VERSION ""

NS_ :

BS_:

BU_: VMCU VGGSECUSystem TECU OBDScanT2 HMIIOM EMS ECUspare2 ECUspare1 DACU CIOM BBM

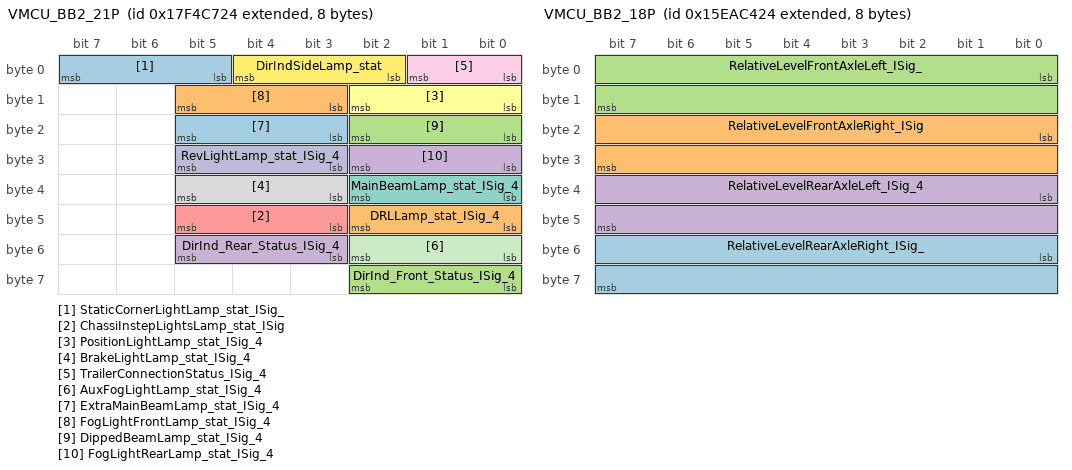
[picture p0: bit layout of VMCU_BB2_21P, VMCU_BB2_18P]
BO_ 2549401380 VMCU_BB2_21P: 8 VMCU
 SG_ StaticCornerLightLamp_stat_ISig_ : 5|3@1+ (1,0) [0|0] ""  HMIIOM
 SG_ DRLLamp_stat_ISig_4 : 40|3@1+ (1,0) [0|0] ""  HMIIOM
 SG_ DirInd_Front_Status_ISig_4 : 56|3@1+ (1,0) [0|0] ""  HMIIOM
 SG_ DirInd_Rear_Status_ISig_4 : 51|3@1+ (1,0) [0|0] ""  HMIIOM
 SG_ ChassiInstepLightsLamp_stat_ISig : 43|3@1+ (1,0) [0|0] ""  HMIIOM
 SG_ PositionLightLamp_stat_ISig_4 : 8|3@1+ (1,0) [0|0] ""  HMIIOM
 SG_ MainBeamLamp_stat_ISig_4 : 32|3@1+ (1,0) [0|0] ""  HMIIOM
 SG_ BrakeLightLamp_stat_ISig_4 : 35|3@1+ (1,0) [0|0] ""  HMIIOM
 SG_ TrailerConnectionStatus_ISig_4 : 0|2@1+ (1,0) [0|0] ""  HMIIOM
 SG_ RevLightLamp_stat_ISig_4 : 27|3@1+ (1,0) [0|0] ""  HMIIOM
 SG_ AuxFogLightLamp_stat_ISig_4 : 48|3@1+ (1,0) [0|0] ""  HMIIOM
 SG_ DirIndSideLamp_stat : 2|3@1+ (1,0) [0|0] ""  HMIIOM
 SG_ ExtraMainBeamLamp_stat_ISig_4 : 19|3@1+ (1,0) [0|0] ""  HMIIOM
 SG_ FogLightFrontLamp_stat_ISig_4 : 11|3@1+ (1,0) [0|0] ""  HMIIOM
 SG_ DippedBeamLamp_stat_ISig_4 : 16|3@1+ (1,0) [0|0] ""  HMIIOM
 SG_ FogLightRearLamp_stat_ISig_4 : 24|3@1+ (1,0) [0|0] ""  HMIIOM

BO_ 2481980708 VMCU_BB2_20P: 8 VMCU
 SG_ StartupProhibitStatus_ISig_4 : 8|2@1+ (1,0) [0|0] ""  BBM,HMIIOM
 SG_ LoadDistributionReasonChanged_IS : 59|3@1+ (1,0) [0|0] ""  HMIIOM
 SG_ RampLevelStatus_ISig_4 : 32|4@1+ (1,0) [0|0] ""  HMIIOM,CIOM
 SG_ KneelingInformation_ISig_4 : 42|4@1+ (1,0) [0|0] ""  BBM,HMIIOM,CIOM
 SG_ FrontAxleInBumperRange_ISig_4 : 40|2@1+ (1,0) [0|0] ""  TECU,HMIIOM
 SG_ FerryFunctionStatus_ISig_4 : 2|3@1+ (1,0) [0|0] ""  HMIIOM,CIOM
 SG_ EngPtoConsumesTorque : 10|2@1+ (1,0) [0|0] ""  TECU
 SG_ LiftingControlModeRearAxle_ISig_ : 36|2@1+ (1,0) [0|0] ""  BBM
 SG_ KneelingStatusHMI_ISig_4 : 53|2@1+ (1,0) [0|0] ""  CIOM
 SG_ SWEngineStop_rqst_ISig_4 : 12|3@1+ (1,0) [0|0] ""  VGGSECUSystem,BBM
 SG_ FrontEndPositionStatus_ISig_4 : 18|3@1+ (1,0) [0|0] ""  CIOM
 SG_ LiftingControlModeFrontAxle_ISig : 30|2@1+ (1,0) [0|0] ""  BBM
 SG_ FrontAxleInBumperRange_UB_ISig_4 : 46|1@1+ (1,0) [0|0] ""  TECU,HMIIOM
 SG_ UnevenLoadWarning_ISig_4 : 16|2@1+ (1,0) [0|0] ""  HMIIOM
 SG_ RampHeightOutsideTargetRange_ISi : 27|3@1+ (1,0) [0|0] ""  HMIIOM,CIOM
 SG_ DriveLevelPosUserInteraction_ISi : 48|3@1+ (1,0) [0|0] ""  HMIIOM
 SG_ RearEndPositionStatus_ISig_4 : 24|3@1+ (1,0) [0|0] ""  TECU,CIOM
 SG_ ProhibitControlStatus_ISig_4 : 6|2@1+ (1,0) [0|0] ""  HMIIOM,BBM
 SG_ ChangeKneelACK_ISig_4 : 51|2@1+ (1,0) [0|0] ""  CIOM
 SG_ RollEndPositionStatus_ISig_4 : 21|3@1+ (1,0) [0|0] ""  CIOM
 SG_ RearAxleInBumperRange_UB_ISig_4 : 47|1@1+ (1,0) [0|0] ""  TECU,HMIIOM
 SG_ TransferCaseBadCondition : 56|3@1+ (1,0) [0|0] ""  HMIIOM
 SG_ ECSStandbyAllowed_ISig_4 : 0|2@1+ (1,0) [0|0] ""  CIOM
 SG_ RearAxleInBumperRange_ISig_4 : 38|2@1+ (1,0) [0|0] ""  TECU,HMIIOM

BO_ 2515190820 VMCU_BB2_18P: 8 VMCU
 SG_ RelativeLevelRearAxleRight_ISig_ : 48|16@1+ (0.1,-3200) [-3200|3353.5] "mm"  BBM
 SG_ RelativeLevelFrontAxleRight_ISig : 16|16@1+ (0.1,-3200) [-3200|3353.5] "mm"  BBM
 SG_ RelativeLevelFrontAxleLeft_ISig_ : 0|16@1+ (0.1,-3200) [-3200|3353.5] "mm"  BBM
 SG_ RelativeLevelRearAxleLeft_ISig_4 : 32|16@1+ (0.1,-3200) [-3200|3353.5] "mm"  BBM

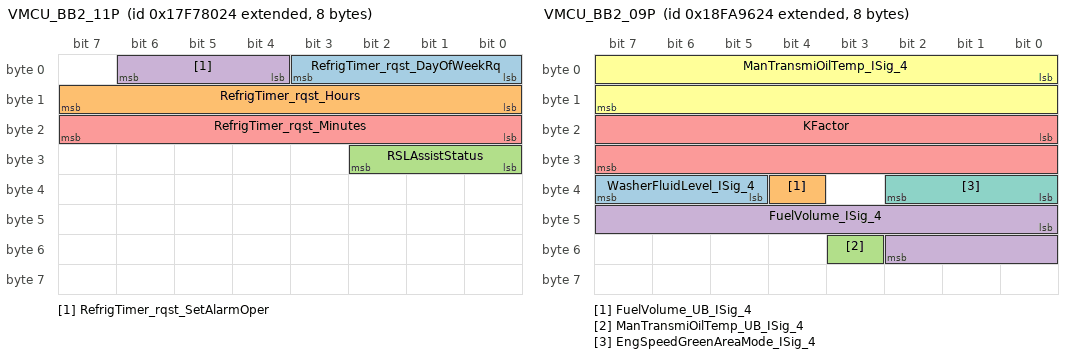
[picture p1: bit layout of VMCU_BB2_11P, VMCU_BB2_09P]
BO_ 2549579812 VMCU_BB2_11P: 8 VMCU
 SG_ RefrigTimer_rqst_DayOfWeekRq : 0|4@1+ (1,0) [0|0] ""  HMIIOM
 SG_ RefrigTimer_rqst_Hours : 8|8@1+ (1,0) [0|255] "h"  HMIIOM
 SG_ RSLAssistStatus : 24|3@1+ (1,0) [0|0] ""  TECU
 SG_ RefrigTimer_rqst_SetAlarmOper : 4|3@1+ (1,0) [0|0] ""  HMIIOM
 SG_ RefrigTimer_rqst_Minutes : 16|8@1+ (1,0) [0|255] "min"  HMIIOM

BO_ 2549430564 VMCU_BB2_10P: 8 VMCU
 SG_ HighResolutionTripDistance2_ISig : 32|32@1+ (5,0) [0|21474836475] "m"  VGGSECUSystem,HMIIOM
 SG_ HighResolutionTripDistance1_ISig : 0|32@1+ (5,0) [0|21474836475] "m"  BBM,VGGSECUSystem,HMIIOM

BO_ 2566559268 VMCU_BB2_09P: 8 VMCU
 SG_ WasherFluidLevel_ISig_4 : 37|3@1+ (1,0) [0|0] ""  HMIIOM
 SG_ FuelVolume_UB_ISig_4 : 36|1@1+ (1,0) [0|0] ""  HMIIOM
 SG_ ManTransmiOilTemp_UB_ISig_4 : 51|1@1+ (1,0) [0|0] ""  HMIIOM
 SG_ FuelVolume_ISig_4 : 40|11@1+ (1,0) [0|2047] "l"  HMIIOM
 SG_ KFactor : 16|16@1+ (1,0) [0|65535] "NotApplicable"  EMS,TECU,BBM,DACU
 SG_ ManTransmiOilTemp_ISig_4 : 0|16@1+ (0.03125,-273) [-273|1774.96875] "DegreeC"  HMIIOM
 SG_ EngSpeedGreenAreaMode_ISig_4 : 32|3@1+ (1,0) [0|0] ""  HMIIOM

BO_ 2515721252 VMCU_BB2_08P: 8 VMCU
 SG_ CabRoofSignLightFeedback_stat : 52|2@1+ (1,0) [0|0] ""  CIOM
 SG_ TemporaryRSLStatus : 54|2@1+ (1,0) [0|0] ""  CIOM
 SG_ CabExtraSideWrknLightFdbk_stat_I : 4|2@1+ (1,0) [0|0] ""  CIOM,BBM
 SG_ CabWrknLightChassisFdbk_stat_ISi : 10|2@1+ (1,0) [0|0] ""  BBM,CIOM
 SG_ HeadLightLevelRequest_stat : 40|5@1+ (1,0) [0|0] ""  HMIIOM
 SG_ CabTrailerBodyLgthnFdbk_stat : 8|2@1+ (1,0) [0|0] ""  CIOM
 SG_ DiffLockInterWhlStatusSplitBox_I : 56|2@1+ (1,0) [0|0] ""  BBM
 SG_ BodyOrCabWorkingLightFdbk_stat_I : 0|2@1+ (1,0) [0|0] ""  CIOM,BBM
 SG_ WheelBasedVehicleSpeedLowRes_ISi : 32|8@1+ (1,0) [0|255] "Km_per_h"  HMIIOM,CIOM
 SG_ AirDryerCoolingFanSpeed_rqst : 16|16@1+ (1,0) [0|65535] "rpm"  VGGSECUSystem,EMS
 SG_ CabFrontSpotFeedback_Status : 6|2@1+ (1,0) [0|0] ""  CIOM
 SG_ CabTiltEnableStatus : 2|2@1+ (1,0) [0|0] ""  CIOM
 SG_ TransmReverseDirectionSw_stat_IS : 58|2@1+ (1,0) [0|0] ""  BBM
 SG_ CabRoofSpotFeedback_Status : 12|2@1+ (1,0) [0|0] ""  HMIIOM,CIOM
 SG_ CabBeaconLightFeedback_Status_IS : 50|2@1+ (1,0) [0|0] ""  CIOM,BBM
 SG_ ExtraAxleSteeringFunctionStat_IS : 60|3@1+ (1,0) [0|0] ""  CIOM
 SG_ AirDryerCoolingFanSpeed_rqst_UB : 48|1@1+ (1,0) [0|0] ""  VGGSECUSystem,EMS
 SG_ CabTiltLockStatus_ISig_4 : 14|2@1+ (1,0) [0|0] ""  BBM,HMIIOM
 SG_ PositionLightRearLamp_stat_ISig_ : 45|3@1+ (1,0) [0|0] ""  HMIIOM

BO_ 2498842916 VMCU_BB2_07P: 8 VMCU
 SG_ Pto1BadCondition_ISig_4 : 4|4@1+ (1,0) [0|0] ""  BBM,HMIIOM
 SG_ PtosStatus_UB_ISig_4 : 40|1@1+ (1,0) [0|0] ""  EMS,CIOM,BBM,HMIIOM
 SG_ Pto4BadCondition : 12|4@1+ (1,0) [0|0] ""  HMIIOM,BBM
 SG_ Pto2BadCondition : 8|4@1+ (1,0) [0|0] ""  HMIIOM,BBM
 SG_ PtoRequest : 18|2@1+ (1,0) [0|0] ""  EMS
 SG_ Pto2ConsentRequest : 32|2@1+ (1,0) [0|0] ""  TECU
 SG_ PBStatusDisplay_cmd_ISig_4 : 42|2@1+ (1,0) [0|0] ""  HMIIOM
 SG_ Pto4DrivingRequest : 28|2@1+ (1,0) [0|0] ""  BBM
 SG_ Pto3Indication : 58|2@1+ (1,0) [0|0] ""  CIOM
 SG_ Pto2Status_ISig_4 : 22|2@1+ (1,0) [0|0] ""  HMIIOM,TECU,CIOM,BBM
 SG_ Pto4Status_ISig_4 : 34|2@1+ (1,0) [0|0] ""  CIOM,HMIIOM,BBM
 SG_ RampLevelRequestACK_ISig_4 : 44|2@1+ (1,0) [0|0] ""  CIOM
 SG_ Pto3BadCondition : 0|4@1+ (1,0) [0|0] ""  HMIIOM,BBM
 SG_ PtosStatus_ISig_4 : 36|2@1+ (1,0) [0|0] ""  BBM,CIOM,EMS,HMIIOM
 SG_ FrontWheelDriveAutoStatus_ISig_4 : 46|2@1+ (1,0) [0|0] ""  BBM,HMIIOM
 SG_ Pto1ConsentRequest : 24|2@1+ (1,0) [0|0] ""  TECU
 SG_ Pto4Indication : 60|2@1+ (1,0) [0|0] ""  CIOM
 SG_ Pto1FeedbackStatus_UB_ISig_4 : 41|1@1+ (1,0) [0|0] ""  BBM,HMIIOM
 SG_ Pto1Indication : 53|2@1+ (1,0) [0|0] ""  CIOM
 SG_ Pto3Status_ISig_4 : 16|2@1+ (1,0) [0|0] ""  BBM,HMIIOM,CIOM
 SG_ Pto2Indication : 56|2@1+ (1,0) [0|0] ""  CIOM
 SG_ Pto1FeedbackStatus_ISig_4 : 38|2@1+ (1,0) [0|0] ""  HMIIOM,BBM
 SG_ TransferCaseOrSplitboxPTOMode_IS : 26|2@1+ (1,0) [0|0] ""  TECU,BBM,HMIIOM
 SG_ FrontWheelDriveMenuFeedback : 48|2@1+ (1,0) [0|0] ""  HMIIOM
 SG_ DirIndRearLamp_Stat_ISig_4 : 50|3@1+ (1,0) [0|0] ""  HMIIOM
 SG_ Pto1Status_ISig_4 : 20|2@1+ (1,0) [0|0] ""  CIOM,TECU,BBM,HMIIOM
 SG_ Pto3DrivingRequest : 30|2@1+ (1,0) [0|0] ""  BBM

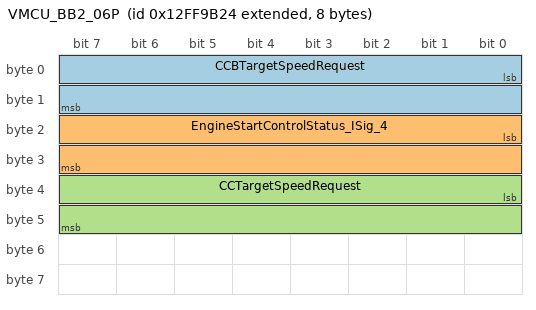
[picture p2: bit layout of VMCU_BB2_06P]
BO_ 2466224932 VMCU_BB2_06P: 8 VMCU
 SG_ CCBTargetSpeedRequest : 0|16@1+ (0.00390625,0) [0|255.99609375] "Km_per_h"  EMS,TECU
 SG_ EngineStartControlStatus_ISig_4 : 16|16@1+ (1,0) [0|0] ""  HMIIOM,BBM,VGGSECUSystem
 SG_ CCTargetSpeedRequest : 32|16@1+ (0.00390625,0) [0|255.99609375] "Km_per_h"  TECU,EMS

BO_ 2466210596 VMCU_BB2_05P: 8 VMCU
 SG_ StoreIdleValue_ISig_4 : 56|2@1+ (1,0) [0|0] ""  HMIIOM,EMS
 SG_ EngSpdCtrlBadConditions_ISig_4 : 50|5@1+ (1,0) [0|0] ""  HMIIOM,VGGSECUSystem
 SG_ TrailerConnected_UB_ISig_4 : 23|1@1+ (1,0) [0|0] ""  HMIIOM,EMS,DACU,TECU,BBM
 SG_ CrossCountryBadConditions : 24|5@1+ (1,0) [0|0] ""  HMIIOM
 SG_ ESCReqEMS_CtrlTrimMode_ISig_4 : 14|4@1+ (1,0) [0|0] ""  EMS,TECU,HMIIOM
 SG_ ESCReqESC_CtrlTrimMode_ISig_4 : 40|4@1+ (1,0) [0|0] ""  CIOM,HMIIOM,BBM,VGGSECUSystem
 SG_ IdleAdjustConditionStatus : 20|2@1+ (1,0) [0|0] ""  HMIIOM
 SG_ StopProhibitStatus_ISig_4 : 61|2@1+ (1,0) [0|0] ""  HMIIOM,BBM
 SG_ ESCReqEMS_CtrlTrimStat_ISig_4 : 11|3@1+ (1,0) [0|0] ""  HMIIOM,EMS,TECU
 SG_ TrailerConnected_ISig_4 : 18|2@1+ (1,0) [0|0] ""  TECU,HMIIOM,EMS,DACU,BBM
 SG_ ESCReqESC_CtrlTrimValue_ISig_4 : 32|8@1+ (10,0) [0|2550] ""  VGGSECUSystem,BBM,HMIIOM,CIOM
 SG_ BrakeLight_rqst_UB_ISig_4 : 22|1@1+ (1,0) [0|0] ""  BBM
 SG_ ESCReqESC_CtrlTrimStat_ISig_4 : 44|3@1+ (1,0) [0|0] ""  CIOM,BBM,HMIIOM,VGGSECUSystem
 SG_ SCLLogicEnable_rqst : 58|3@1+ (1,0) [0|0] ""  CIOM
 SG_ ESCReqESC_CtrlTrimReq_ISig_4 : 47|3@1+ (1,0) [0|0] ""  HMIIOM,CIOM,BBM,VGGSECUSystem
 SG_ BrakeLight_rqst_ISig_4 : 29|3@1+ (1,0) [0|0] ""  BBM
 SG_ ESCReqEMS_CtrlTrimValue_ISig_4 : 0|8@1+ (10,0) [0|2550] ""  HMIIOM,TECU,EMS
 SG_ ESCReqEMS_CtrlTrimReq_ISig_4 : 8|3@1+ (1,0) [0|0] ""  HMIIOM,TECU,EMS

BO_ 2466196004 VMCU_BB2_04P: 8 VMCU
 SG_ WiperParkStatus_Global_UB_ISig_4 : 39|1@1+ (1,0) [0|0] ""  DACU
 SG_ TrailerTest_stat : 3|3@1+ (1,0) [0|0] ""  VGGSECUSystem,HMIIOM
 SG_ Washing_HMI_rqst_ISig_4 : 42|2@1+ (1,0) [0|0] ""  CIOM
 SG_ AuxBrakesDwngrdModeInd_rqst_ISig : 27|3@1+ (1,0) [0|0] ""  HMIIOM,VGGSECUSystem
 SG_ XRSLTargetSpeedRequest : 48|16@1+ (0.00390625,0) [0|255.99609375] "Km_per_h"  EMS
 SG_ XPRsystemstate_ISig_4 : 8|8@1+ (1,0) [0|255] "NotApplicable"  DACU,BBM
 SG_ KeyAuthentication_rqst : 35|3@1+ (1,0) [0|0] ""  CIOM
 SG_ EngineSpeedControlStatus_ISig_4 : 32|3@1+ (1,0) [0|0] ""  CIOM,HMIIOM,BBM,VGGSECUSystem
 SG_ EngineSpeedLimitReached : 0|3@1+ (1,0) [0|0] ""  HMIIOM
 SG_ SecondThrottle : 30|2@1+ (1,0) [0|0] ""  EMS,DACU
 SG_ PredeliveryModeIndication_cmd_IS : 40|2@1+ (1,0) [0|0] ""  HMIIOM,CIOM
 SG_ LoadCutOffIndication_cmd_ISig_4 : 44|2@1+ (1,0) [0|0] ""  HMIIOM
 SG_ AutoPBRelease_stat_ISig_4 : 22|2@1+ (1,0) [0|0] ""  HMIIOM
 SG_ AutoParkBrakeActvnInhibd_stat_IS : 6|2@1+ (1,0) [0|0] ""  HMIIOM
 SG_ WiperParkStatus_Global_ISig_4 : 20|2@1+ (1,0) [0|0] ""  DACU
 SG_ ExitPreDeliveryModeHMI_rqst_ISig : 16|2@1+ (1,0) [0|0] ""  CIOM
 SG_ FdEquipmentStatus1_ISig_4 : 18|2@1+ (1,0) [0|0] ""  BBM,HMIIOM,CIOM

BO_ 2432649764 VMCU_BB2_03P: 8 VMCU
 SG_ ParkBrakeAlert_ISig_4 : 42|2@1+ (1,0) [0|0] ""  HMIIOM
 SG_ IntLightMode_CoreRqst_IL_Mode : 48|3@1+ (1,0) [0|0] ""  HMIIOM,CIOM
 SG_ WiperModeStatus_UB_ISig_4 : 55|1@1+ (1,0) [0|0] ""  CIOM,HMIIOM,DACU
 SG_ SteeringColumnLockErrInd_rqst : 27|3@1+ (1,0) [0|0] ""  HMIIOM
 SG_ MainBeamIndication_cmd : 14|2@1+ (1,0) [0|0] ""  HMIIOM
 SG_ PosLightWarning_rqst : 12|2@1+ (1,0) [0|0] ""  HMIIOM
 SG_ RainsensorActivationHMI_stat : 52|2@1+ (1,0) [0|0] ""  HMIIOM
 SG_ FogLight_Front_Indication_Cmd : 18|2@1+ (1,0) [0|0] ""  HMIIOM
 SG_ ParkingLight_Indication : 30|2@1+ (1,0) [0|0] ""  CIOM
 SG_ DaytimeRunningLight_Indication : 16|2@1+ (1,0) [0|0] ""  CIOM
 SG_ EPBBackupMode_ISig_4 : 44|4@1+ (1,0) [0|0] ""  HMIIOM
 SG_ WiperModeStatus_ISig_4 : 32|3@1+ (1,0) [0|0] ""  CIOM,DACU
 SG_ FrontFog_Indication : 22|2@1+ (1,0) [0|0] ""  CIOM
 SG_ PBReleaseAcceptance_stat_ISig_4 : 37|3@1+ (1,0) [0|0] ""  HMIIOM
 SG_ ParkingBrake_stat_UB_ISig_4 : 54|1@1+ (1,0) [0|0] ""  HMIIOM,EMS,CIOM,TECU,BBM
 SG_ DrivingLightPlus_Indication : 8|2@1+ (1,0) [0|0] ""  CIOM
 SG_ IntLightMode_CoreRqst_EventFlag : 51|1@1+ (1,0) [0|0] ""  CIOM,HMIIOM
 SG_ ParkingBrake_stat_ISig_4 : 40|2@1+ (1,0) [0|0] ""  EMS,HMIIOM,VGGSECUSystem,CIOM,BBM,TECU
 SG_ DrivingLight_Indication : 4|2@1+ (1,0) [0|0] ""  CIOM
 SG_ Rainsensor_Indication : 20|2@1+ (1,0) [0|0] ""  HMIIOM
 SG_ DippedBeamIndication_cmd : 10|2@1+ (1,0) [0|0] ""  HMIIOM
 SG_ MirrorHeatingMode_ISig_4 : 24|3@1+ (1,0) [0|0] ""  CIOM
 SG_ RearFog_Indication : 35|2@1+ (1,0) [0|0] ""  CIOM
 SG_ InteriorLightLevelInd_cmd : 56|8@1+ (1,0) [0|255] "Percent"  CIOM
 SG_ FogLight_Rear_Indication_Cmd : 2|2@1+ (1,0) [0|0] ""  HMIIOM
 SG_ PosLight_Indication_Cmd : 6|2@1+ (1,0) [0|0] ""  HMIIOM
 SG_ DirIndicationTimeoutInd_rqst : 0|2@1+ (1,0) [0|0] ""  HMIIOM

CM_ SG_ 2515190820 RelativeLevelRearAxleRight_ISig_ "65024 - 65279 Error ; 65280 - 65535 Not available";
CM_ SG_ 2515190820 RelativeLevelFrontAxleRight_ISig "65024 - 65279 Error ; 65280 - 65535 Not available";
CM_ SG_ 2515190820 RelativeLevelFrontAxleLeft_ISig_ "65024 - 65279 Error ; 65280 - 65535 Not available";
CM_ SG_ 2515190820 RelativeLevelRearAxleLeft_ISig_4 "65024 - 65279 Error ; 65280 - 65535 Not available";
CM_ SG_ 2549430564 HighResolutionTripDistance2_ISig "4261412864 - 4278190079 Error ; 4278190080 - 4294967295 Not available";
CM_ SG_ 2549430564 HighResolutionTripDistance1_ISig "4261412864 - 4278190079 Error ; 4278190080 - 4294967295 Not available";
CM_ SG_ 2566559268 KFactor "65024 - 65279 Error ; 65280 - 65535 Not available";
CM_ SG_ 2566559268 ManTransmiOilTemp_ISig_4 "65024 - 65279 Error ; 65280 - 65535 Not available";
CM_ SG_ 2515721252 WheelBasedVehicleSpeedLowRes_ISi "254 Error ; 255 Not available";
CM_ SG_ 2515721252 AirDryerCoolingFanSpeed_rqst "65024 - 65279 Error ; 65280 - 65535 Not available";
CM_ SG_ 2466224932 CCBTargetSpeedRequest "65024 - 65279 Error ; 65280 - 65535 Not available";
CM_ SG_ 2466224932 EngineStartControlStatus_ISig_4 "65534 Error ; 65535 Not available";
CM_ SG_ 2466224932 CCTargetSpeedRequest "65024 - 65279 Error ; 65280 - 65535 Not available";
CM_ SG_ 2466210596 ESCReqESC_CtrlTrimValue_ISig_4 "254 Error ; 255 Not available";
CM_ SG_ 2466210596 ESCReqEMS_CtrlTrimValue_ISig_4 "254 Error ; 255 Not available";
CM_ SG_ 2466196004 XRSLTargetSpeedRequest "65024 - 65279 Error ; 65280 - 65535 Not available";
BA_DEF_ BO_  "GenMsgStartDelayTime" INT 0 0;
BA_DEF_ BO_  "GenMsgDelayTime" INT 0 0;
BA_DEF_ BO_  "GenMsgCycleTime" INT 0 0;
BA_DEF_ BO_  "GenMsgSendType" ENUM  "Cyclic","NotUsed","NotUsed","NotUsed","NotUsed","NotUsed","NotUsed","IfActive","NoMsgSendType","NotUsed";
BA_DEF_ SG_  "GenSigStartValue" INT 0 0;
BA_DEF_ SG_  "GenSigCycleTimeActive" INT 0 0;
BA_DEF_ SG_  "GenSigCycleTime" INT 0 0;
BA_DEF_ SG_  "GenSigSendType" ENUM  "Cyclic","OnWrite","OnWriteWithRepetition","OnChange","OnChangeWithRepetition","IfActive","IfActiveWithRepetition","NoSigSendType","NotUsed","NotUsed","NotUsed","NotUsed","NotUsed";
BA_DEF_ BO_  "VFrameFormat" ENUM  "StandardCAN","ExtendedCAN","reserved","J1939PG";
BA_DEF_ SG_  "SigType" ENUM  "Default","Range","RangeSigned","ASCII","Discrete","Control","ReferencePGN","DTC","StringDelimiter","StringLength","StringLengthControl";
BA_DEF_ SG_  "SeToolVersion_SIGNAL" STRING ;
BA_DEF_ SG_  "SeToolUniqueID_SIGNAL" STRING ;
BA_DEF_ SG_  "SeToolOwnerSigGroup_SIGNAL" STRING ;
BA_DEF_ SG_  "SeToolOwnerSigGroupID_SIGNAL" STRING ;
BA_DEF_ SG_  "SeToolName_SIGNAL" STRING ;
BA_DEF_ SG_  "SeToolItemID_SIGNAL" STRING ;
BA_DEF_ SG_  "SeToolAncestorID_SIGNAL" STRING ;
BA_DEF_ SG_  "Platform_VMCU1_Sig" ENUM  "No","Yes";
BA_DEF_ BO_  "NmAsrMessage" ENUM  "No","Yes";
BA_DEF_ SG_  "NeedsUpdateBit" ENUM  "No","Yes";
BA_DEF_ SG_  "MmAnSignal" ENUM  "No","Yes";
BA_DEF_ SG_  "GenSigMaxLatency" INT 0 65535;
BA_DEF_ SG_  "GenSigILSupport" ENUM  "Yes","No";
BA_DEF_ BO_  "GenMsgRequestable" INT 0 1;
BA_DEF_ BO_  "GenMsgILSupport" ENUM  "No","Yes";
BA_DEF_ BO_  "DiagUUDTResponse" ENUM  "No","Yes";
BA_DEF_ BO_  "DiagState" ENUM  "No","Yes";
BA_DEF_ BO_  "DiagResponse" ENUM  "No","Yes";
BA_DEF_ BO_  "DiagRequest" ENUM  "No","Yes";
BA_DEF_ BO_  "DiagConnection" HEX 0 65535;
BA_DEF_ BO_  "CanTpSTmin" INT 0 255;
BA_DEF_ BO_  "CanTpFcFrameId" HEX 0 2147483647;
BA_DEF_ BO_  "CanTpBs" INT 0 255;
BA_DEF_ SG_  "SystemSignalLongSymbol" STRING ;
BA_DEF_REL_ BU_SG_REL_  "GenSigTimeoutTime" INT 0 65535;
BA_DEF_REL_ BU_SG_REL_  "GenSigFirstTimeoutTime" INT 0 65535;
BA_DEF_DEF_  "GenMsgStartDelayTime" 0;
BA_DEF_DEF_  "GenMsgDelayTime" 0;
BA_DEF_DEF_  "GenMsgCycleTime" 0;
BA_DEF_DEF_  "GenMsgSendType" "Cyclic";
BA_DEF_DEF_  "GenSigStartValue" 0;
BA_DEF_DEF_  "GenSigCycleTimeActive" 0;
BA_DEF_DEF_  "GenSigCycleTime" 0;
BA_DEF_DEF_  "GenSigSendType" "Cyclic";
BA_DEF_DEF_  "VFrameFormat" "ExtendedCAN";
BA_DEF_DEF_  "SigType" "Default";
BA_DEF_DEF_  "SeToolVersion_SIGNAL" "";
BA_DEF_DEF_  "SeToolUniqueID_SIGNAL" "";
BA_DEF_DEF_  "SeToolOwnerSigGroup_SIGNAL" "";
BA_DEF_DEF_  "SeToolOwnerSigGroupID_SIGNAL" "";
BA_DEF_DEF_  "SeToolName_SIGNAL" "";
BA_DEF_DEF_  "SeToolItemID_SIGNAL" "";
BA_DEF_DEF_  "SeToolAncestorID_SIGNAL" "";
BA_DEF_DEF_  "Platform_VMCU1_Sig" "No";
BA_DEF_DEF_  "NmAsrMessage" "No";
BA_DEF_DEF_  "NeedsUpdateBit" "No";
BA_DEF_DEF_  "MmAnSignal" "No";
BA_DEF_DEF_  "GenSigMaxLatency" 0;
BA_DEF_DEF_  "GenSigILSupport" "Yes";
BA_DEF_DEF_  "GenMsgRequestable" 1;
BA_DEF_DEF_  "GenMsgILSupport" "Yes";
BA_DEF_DEF_  "DiagUUDTResponse" "No";
BA_DEF_DEF_  "DiagState" "No";
BA_DEF_DEF_  "DiagResponse" "No";
BA_DEF_DEF_  "DiagRequest" "No";
BA_DEF_DEF_  "DiagConnection" 0;
BA_DEF_DEF_  "CanTpSTmin" 0;
BA_DEF_DEF_  "CanTpFcFrameId" 2147483647;
BA_DEF_DEF_  "CanTpBs" 255;
BA_DEF_DEF_REL_ "GenSigTimeoutTime" 0;
BA_DEF_DEF_REL_ "GenSigFirstTimeoutTime" 0;
BA_DEF_DEF_  "SystemSignalLongSymbol" "";
BA_ "GenMsgCycleTime" BO_ 2549401380 250;
BA_ "GenMsgStartDelayTime" BO_ 2549401380 90;
BA_ "GenMsgCycleTime" BO_ 2481980708 50;
BA_ "GenMsgStartDelayTime" BO_ 2481980708 20;
BA_ "GenMsgCycleTime" BO_ 2515190820 100;
BA_ "GenMsgStartDelayTime" BO_ 2515190820 15;
BA_ "GenMsgCycleTime" BO_ 2549579812 250;
BA_ "GenMsgStartDelayTime" BO_ 2549579812 50;
BA_ "GenMsgCycleTime" BO_ 2549430564 250;
BA_ "GenMsgStartDelayTime" BO_ 2549430564 190;
BA_ "GenMsgCycleTime" BO_ 2566559268 500;
BA_ "GenMsgStartDelayTime" BO_ 2566559268 125;
BA_ "GenMsgCycleTime" BO_ 2515721252 100;
BA_ "GenMsgStartDelayTime" BO_ 2515721252 60;
BA_ "GenMsgCycleTime" BO_ 2498842916 75;
BA_ "GenMsgStartDelayTime" BO_ 2498842916 25;
BA_ "GenMsgCycleTime" BO_ 2466224932 45;
BA_ "GenMsgStartDelayTime" BO_ 2466224932 5;
BA_ "GenMsgCycleTime" BO_ 2466210596 45;
BA_ "GenMsgStartDelayTime" BO_ 2466210596 10;
BA_ "GenMsgCycleTime" BO_ 2466196004 45;
BA_ "GenMsgStartDelayTime" BO_ 2466196004 25;
BA_ "GenMsgCycleTime" BO_ 2432649764 25;
BA_ "GenMsgStartDelayTime" BO_ 2432649764 5;
BA_ "GenSigCycleTime" SG_ 2549401380 StaticCornerLightLamp_stat_ISig_ 100;
BA_ "GenSigCycleTimeActive" SG_ 2549401380 StaticCornerLightLamp_stat_ISig_ 100;
BA_ "GenSigStartValue" SG_ 2549401380 StaticCornerLightLamp_stat_ISig_ 7;
BA_ "GenSigMaxLatency" SG_ 2549401380 StaticCornerLightLamp_stat_ISig_ 258;
BA_ "Platform_VMCU1_Sig" SG_ 2549401380 StaticCornerLightLamp_stat_ISig_ 1;
BA_ "SystemSignalLongSymbol" SG_ 2549401380 StaticCornerLightLamp_stat_ISig_ "StaticCornerLightLamp_stat_ISig_4";
BA_ "GenSigCycleTime" SG_ 2549401380 DRLLamp_stat_ISig_4 100;
BA_ "GenSigCycleTimeActive" SG_ 2549401380 DRLLamp_stat_ISig_4 100;
BA_ "GenSigStartValue" SG_ 2549401380 DRLLamp_stat_ISig_4 7;
BA_ "GenSigMaxLatency" SG_ 2549401380 DRLLamp_stat_ISig_4 258;
BA_ "Platform_VMCU1_Sig" SG_ 2549401380 DRLLamp_stat_ISig_4 1;
BA_ "GenSigCycleTime" SG_ 2549401380 DirInd_Front_Status_ISig_4 100;
BA_ "GenSigCycleTimeActive" SG_ 2549401380 DirInd_Front_Status_ISig_4 100;
BA_ "GenSigStartValue" SG_ 2549401380 DirInd_Front_Status_ISig_4 7;
BA_ "GenSigMaxLatency" SG_ 2549401380 DirInd_Front_Status_ISig_4 258;
BA_ "Platform_VMCU1_Sig" SG_ 2549401380 DirInd_Front_Status_ISig_4 1;
BA_ "SeToolAncestorID_SIGNAL" SG_ 2549401380 DirInd_Front_Status_ISig_4 "x0000001D041661B2";
BA_ "SeToolItemID_SIGNAL" SG_ 2549401380 DirInd_Front_Status_ISig_4 "x0000001D042DBCE4";
BA_ "SeToolName_SIGNAL" SG_ 2549401380 DirInd_Front_Status_ISig_4 "DirInd_Front_Status";
BA_ "SeToolVersion_SIGNAL" SG_ 2549401380 DirInd_Front_Status_ISig_4 "2";
BA_ "GenSigCycleTime" SG_ 2549401380 DirInd_Rear_Status_ISig_4 100;
BA_ "GenSigCycleTimeActive" SG_ 2549401380 DirInd_Rear_Status_ISig_4 100;
BA_ "GenSigStartValue" SG_ 2549401380 DirInd_Rear_Status_ISig_4 7;
BA_ "GenSigMaxLatency" SG_ 2549401380 DirInd_Rear_Status_ISig_4 258;
BA_ "Platform_VMCU1_Sig" SG_ 2549401380 DirInd_Rear_Status_ISig_4 1;
BA_ "SeToolAncestorID_SIGNAL" SG_ 2549401380 DirInd_Rear_Status_ISig_4 "x0000001D041661D0";
BA_ "SeToolItemID_SIGNAL" SG_ 2549401380 DirInd_Rear_Status_ISig_4 "x0000001D042DB8F6";
BA_ "SeToolName_SIGNAL" SG_ 2549401380 DirInd_Rear_Status_ISig_4 "DirInd_Rear_Status";
BA_ "SeToolVersion_SIGNAL" SG_ 2549401380 DirInd_Rear_Status_ISig_4 "2";
BA_ "GenSigCycleTime" SG_ 2549401380 ChassiInstepLightsLamp_stat_ISig 100;
BA_ "GenSigCycleTimeActive" SG_ 2549401380 ChassiInstepLightsLamp_stat_ISig 100;
BA_ "GenSigStartValue" SG_ 2549401380 ChassiInstepLightsLamp_stat_ISig 7;
BA_ "GenSigMaxLatency" SG_ 2549401380 ChassiInstepLightsLamp_stat_ISig 258;
BA_ "Platform_VMCU1_Sig" SG_ 2549401380 ChassiInstepLightsLamp_stat_ISig 1;
BA_ "SystemSignalLongSymbol" SG_ 2549401380 ChassiInstepLightsLamp_stat_ISig "ChassiInstepLightsLamp_stat_ISig_4";
BA_ "GenSigCycleTime" SG_ 2549401380 PositionLightLamp_stat_ISig_4 100;
BA_ "GenSigCycleTimeActive" SG_ 2549401380 PositionLightLamp_stat_ISig_4 100;
BA_ "GenSigStartValue" SG_ 2549401380 PositionLightLamp_stat_ISig_4 7;
BA_ "GenSigMaxLatency" SG_ 2549401380 PositionLightLamp_stat_ISig_4 258;
BA_ "Platform_VMCU1_Sig" SG_ 2549401380 PositionLightLamp_stat_ISig_4 1;
BA_ "GenSigCycleTime" SG_ 2549401380 MainBeamLamp_stat_ISig_4 100;
BA_ "GenSigCycleTimeActive" SG_ 2549401380 MainBeamLamp_stat_ISig_4 100;
BA_ "GenSigStartValue" SG_ 2549401380 MainBeamLamp_stat_ISig_4 7;
BA_ "GenSigMaxLatency" SG_ 2549401380 MainBeamLamp_stat_ISig_4 258;
BA_ "Platform_VMCU1_Sig" SG_ 2549401380 MainBeamLamp_stat_ISig_4 1;
BA_ "GenSigCycleTime" SG_ 2549401380 BrakeLightLamp_stat_ISig_4 100;
BA_ "GenSigCycleTimeActive" SG_ 2549401380 BrakeLightLamp_stat_ISig_4 100;
BA_ "GenSigStartValue" SG_ 2549401380 BrakeLightLamp_stat_ISig_4 7;
BA_ "GenSigMaxLatency" SG_ 2549401380 BrakeLightLamp_stat_ISig_4 258;
BA_ "Platform_VMCU1_Sig" SG_ 2549401380 BrakeLightLamp_stat_ISig_4 1;
BA_ "GenSigCycleTime" SG_ 2549401380 TrailerConnectionStatus_ISig_4 100;
BA_ "GenSigCycleTimeActive" SG_ 2549401380 TrailerConnectionStatus_ISig_4 100;
BA_ "GenSigStartValue" SG_ 2549401380 TrailerConnectionStatus_ISig_4 3;
BA_ "GenSigCycleTime" SG_ 2549401380 RevLightLamp_stat_ISig_4 100;
BA_ "GenSigCycleTimeActive" SG_ 2549401380 RevLightLamp_stat_ISig_4 100;
BA_ "GenSigStartValue" SG_ 2549401380 RevLightLamp_stat_ISig_4 7;
BA_ "GenSigMaxLatency" SG_ 2549401380 RevLightLamp_stat_ISig_4 258;
BA_ "Platform_VMCU1_Sig" SG_ 2549401380 RevLightLamp_stat_ISig_4 1;
BA_ "GenSigCycleTime" SG_ 2549401380 AuxFogLightLamp_stat_ISig_4 100;
BA_ "GenSigCycleTimeActive" SG_ 2549401380 AuxFogLightLamp_stat_ISig_4 100;
BA_ "GenSigStartValue" SG_ 2549401380 AuxFogLightLamp_stat_ISig_4 7;
BA_ "GenSigMaxLatency" SG_ 2549401380 AuxFogLightLamp_stat_ISig_4 258;
BA_ "Platform_VMCU1_Sig" SG_ 2549401380 AuxFogLightLamp_stat_ISig_4 1;
BA_ "GenSigCycleTime" SG_ 2549401380 DirIndSideLamp_stat 100;
BA_ "GenSigCycleTimeActive" SG_ 2549401380 DirIndSideLamp_stat 100;
BA_ "GenSigStartValue" SG_ 2549401380 DirIndSideLamp_stat 7;
BA_ "GenSigMaxLatency" SG_ 2549401380 DirIndSideLamp_stat 258;
BA_ "Platform_VMCU1_Sig" SG_ 2549401380 DirIndSideLamp_stat 1;
BA_ "GenSigCycleTime" SG_ 2549401380 ExtraMainBeamLamp_stat_ISig_4 100;
BA_ "GenSigCycleTimeActive" SG_ 2549401380 ExtraMainBeamLamp_stat_ISig_4 100;
BA_ "GenSigStartValue" SG_ 2549401380 ExtraMainBeamLamp_stat_ISig_4 7;
BA_ "GenSigMaxLatency" SG_ 2549401380 ExtraMainBeamLamp_stat_ISig_4 258;
BA_ "Platform_VMCU1_Sig" SG_ 2549401380 ExtraMainBeamLamp_stat_ISig_4 1;
BA_ "GenSigCycleTime" SG_ 2549401380 FogLightFrontLamp_stat_ISig_4 100;
BA_ "GenSigCycleTimeActive" SG_ 2549401380 FogLightFrontLamp_stat_ISig_4 100;
BA_ "GenSigStartValue" SG_ 2549401380 FogLightFrontLamp_stat_ISig_4 7;
BA_ "GenSigMaxLatency" SG_ 2549401380 FogLightFrontLamp_stat_ISig_4 258;
BA_ "Platform_VMCU1_Sig" SG_ 2549401380 FogLightFrontLamp_stat_ISig_4 1;
BA_ "GenSigCycleTime" SG_ 2549401380 DippedBeamLamp_stat_ISig_4 100;
BA_ "GenSigCycleTimeActive" SG_ 2549401380 DippedBeamLamp_stat_ISig_4 100;
BA_ "GenSigStartValue" SG_ 2549401380 DippedBeamLamp_stat_ISig_4 7;
BA_ "GenSigMaxLatency" SG_ 2549401380 DippedBeamLamp_stat_ISig_4 258;
BA_ "Platform_VMCU1_Sig" SG_ 2549401380 DippedBeamLamp_stat_ISig_4 1;
BA_ "GenSigCycleTime" SG_ 2549401380 FogLightRearLamp_stat_ISig_4 100;
BA_ "GenSigCycleTimeActive" SG_ 2549401380 FogLightRearLamp_stat_ISig_4 100;
BA_ "GenSigStartValue" SG_ 2549401380 FogLightRearLamp_stat_ISig_4 7;
BA_ "GenSigMaxLatency" SG_ 2549401380 FogLightRearLamp_stat_ISig_4 258;
BA_ "Platform_VMCU1_Sig" SG_ 2549401380 FogLightRearLamp_stat_ISig_4 1;
BA_ "GenSigCycleTime" SG_ 2481980708 StartupProhibitStatus_ISig_4 100;
BA_ "GenSigCycleTimeActive" SG_ 2481980708 StartupProhibitStatus_ISig_4 100;
BA_ "GenSigStartValue" SG_ 2481980708 StartupProhibitStatus_ISig_4 3;
BA_ "GenSigMaxLatency" SG_ 2481980708 StartupProhibitStatus_ISig_4 117;
BA_ "Platform_VMCU1_Sig" SG_ 2481980708 StartupProhibitStatus_ISig_4 1;
BA_ "GenSigCycleTime" SG_ 2481980708 LoadDistributionReasonChanged_IS 100;
BA_ "GenSigCycleTimeActive" SG_ 2481980708 LoadDistributionReasonChanged_IS 100;
BA_ "GenSigStartValue" SG_ 2481980708 LoadDistributionReasonChanged_IS 7;
BA_ "Platform_VMCU1_Sig" SG_ 2481980708 LoadDistributionReasonChanged_IS 1;
BA_ "SystemSignalLongSymbol" SG_ 2481980708 LoadDistributionReasonChanged_IS "LoadDistributionReasonChanged_ISig_4";
BA_ "GenSigCycleTime" SG_ 2481980708 RampLevelStatus_ISig_4 100;
BA_ "GenSigCycleTimeActive" SG_ 2481980708 RampLevelStatus_ISig_4 100;
BA_ "GenSigStartValue" SG_ 2481980708 RampLevelStatus_ISig_4 15;
BA_ "GenSigMaxLatency" SG_ 2481980708 RampLevelStatus_ISig_4 117;
BA_ "Platform_VMCU1_Sig" SG_ 2481980708 RampLevelStatus_ISig_4 1;
BA_ "GenSigCycleTime" SG_ 2481980708 KneelingInformation_ISig_4 100;
BA_ "GenSigCycleTimeActive" SG_ 2481980708 KneelingInformation_ISig_4 100;
BA_ "GenSigStartValue" SG_ 2481980708 KneelingInformation_ISig_4 15;
BA_ "Platform_VMCU1_Sig" SG_ 2481980708 KneelingInformation_ISig_4 1;
BA_ "GenSigCycleTime" SG_ 2481980708 FrontAxleInBumperRange_ISig_4 100;
BA_ "GenSigCycleTimeActive" SG_ 2481980708 FrontAxleInBumperRange_ISig_4 100;
BA_ "GenSigStartValue" SG_ 2481980708 FrontAxleInBumperRange_ISig_4 3;
BA_ "NeedsUpdateBit" SG_ 2481980708 FrontAxleInBumperRange_ISig_4 1;
BA_ "Platform_VMCU1_Sig" SG_ 2481980708 FrontAxleInBumperRange_ISig_4 1;
BA_ "SeToolAncestorID_SIGNAL" SG_ 2481980708 FrontAxleInBumperRange_ISig_4 "x0000001D04149915";
BA_ "SeToolItemID_SIGNAL" SG_ 2481980708 FrontAxleInBumperRange_ISig_4 "x0000001D04149915";
BA_ "SeToolName_SIGNAL" SG_ 2481980708 FrontAxleInBumperRange_ISig_4 "FrontAxleInBumperRange";
BA_ "SeToolVersion_SIGNAL" SG_ 2481980708 FrontAxleInBumperRange_ISig_4 "1";
BA_ "GenSigCycleTime" SG_ 2481980708 FerryFunctionStatus_ISig_4 100;
BA_ "GenSigCycleTimeActive" SG_ 2481980708 FerryFunctionStatus_ISig_4 100;
BA_ "GenSigStartValue" SG_ 2481980708 FerryFunctionStatus_ISig_4 7;
BA_ "GenSigMaxLatency" SG_ 2481980708 FerryFunctionStatus_ISig_4 117;
BA_ "Platform_VMCU1_Sig" SG_ 2481980708 FerryFunctionStatus_ISig_4 1;
BA_ "GenSigCycleTime" SG_ 2481980708 EngPtoConsumesTorque 100;
BA_ "GenSigCycleTimeActive" SG_ 2481980708 EngPtoConsumesTorque 100;
BA_ "GenSigStartValue" SG_ 2481980708 EngPtoConsumesTorque 3;
BA_ "Platform_VMCU1_Sig" SG_ 2481980708 EngPtoConsumesTorque 1;
BA_ "GenSigCycleTime" SG_ 2481980708 LiftingControlModeRearAxle_ISig_ 100;
BA_ "GenSigCycleTimeActive" SG_ 2481980708 LiftingControlModeRearAxle_ISig_ 100;
BA_ "GenSigStartValue" SG_ 2481980708 LiftingControlModeRearAxle_ISig_ 3;
BA_ "Platform_VMCU1_Sig" SG_ 2481980708 LiftingControlModeRearAxle_ISig_ 1;
BA_ "SeToolAncestorID_SIGNAL" SG_ 2481980708 LiftingControlModeRearAxle_ISig_ "x0000001D04149A4E";
BA_ "SeToolItemID_SIGNAL" SG_ 2481980708 LiftingControlModeRearAxle_ISig_ "x0000001D04149A4E";
BA_ "SeToolName_SIGNAL" SG_ 2481980708 LiftingControlModeRearAxle_ISig_ "LiftingControlModeRearAxle";
BA_ "SeToolVersion_SIGNAL" SG_ 2481980708 LiftingControlModeRearAxle_ISig_ "1";
BA_ "SystemSignalLongSymbol" SG_ 2481980708 LiftingControlModeRearAxle_ISig_ "LiftingControlModeRearAxle_ISig_4";
BA_ "GenSigCycleTime" SG_ 2481980708 KneelingStatusHMI_ISig_4 100;
BA_ "GenSigCycleTimeActive" SG_ 2481980708 KneelingStatusHMI_ISig_4 100;
BA_ "GenSigStartValue" SG_ 2481980708 KneelingStatusHMI_ISig_4 3;
BA_ "Platform_VMCU1_Sig" SG_ 2481980708 KneelingStatusHMI_ISig_4 1;
BA_ "GenSigCycleTime" SG_ 2481980708 SWEngineStop_rqst_ISig_4 100;
BA_ "GenSigCycleTimeActive" SG_ 2481980708 SWEngineStop_rqst_ISig_4 100;
BA_ "GenSigStartValue" SG_ 2481980708 SWEngineStop_rqst_ISig_4 7;
BA_ "Platform_VMCU1_Sig" SG_ 2481980708 SWEngineStop_rqst_ISig_4 1;
BA_ "GenSigCycleTime" SG_ 2481980708 FrontEndPositionStatus_ISig_4 100;
BA_ "GenSigCycleTimeActive" SG_ 2481980708 FrontEndPositionStatus_ISig_4 100;
BA_ "GenSigStartValue" SG_ 2481980708 FrontEndPositionStatus_ISig_4 7;
BA_ "GenSigMaxLatency" SG_ 2481980708 FrontEndPositionStatus_ISig_4 117;
BA_ "Platform_VMCU1_Sig" SG_ 2481980708 FrontEndPositionStatus_ISig_4 1;
BA_ "GenSigCycleTime" SG_ 2481980708 LiftingControlModeFrontAxle_ISig 100;
BA_ "GenSigCycleTimeActive" SG_ 2481980708 LiftingControlModeFrontAxle_ISig 100;
BA_ "GenSigStartValue" SG_ 2481980708 LiftingControlModeFrontAxle_ISig 3;
BA_ "Platform_VMCU1_Sig" SG_ 2481980708 LiftingControlModeFrontAxle_ISig 1;
BA_ "SeToolAncestorID_SIGNAL" SG_ 2481980708 LiftingControlModeFrontAxle_ISig "x0000001D04149903";
BA_ "SeToolItemID_SIGNAL" SG_ 2481980708 LiftingControlModeFrontAxle_ISig "x0000001D04149903";
BA_ "SeToolName_SIGNAL" SG_ 2481980708 LiftingControlModeFrontAxle_ISig "LiftingControlModeFrontAxle";
BA_ "SeToolVersion_SIGNAL" SG_ 2481980708 LiftingControlModeFrontAxle_ISig "1";
BA_ "SystemSignalLongSymbol" SG_ 2481980708 LiftingControlModeFrontAxle_ISig "LiftingControlModeFrontAxle_ISig_4";
BA_ "GenSigSendType" SG_ 2481980708 FrontAxleInBumperRange_UB_ISig_4 7;
BA_ "Platform_VMCU1_Sig" SG_ 2481980708 FrontAxleInBumperRange_UB_ISig_4 1;
BA_ "GenSigCycleTime" SG_ 2481980708 UnevenLoadWarning_ISig_4 100;
BA_ "GenSigCycleTimeActive" SG_ 2481980708 UnevenLoadWarning_ISig_4 100;
BA_ "GenSigStartValue" SG_ 2481980708 UnevenLoadWarning_ISig_4 3;
BA_ "GenSigMaxLatency" SG_ 2481980708 UnevenLoadWarning_ISig_4 117;
BA_ "Platform_VMCU1_Sig" SG_ 2481980708 UnevenLoadWarning_ISig_4 1;
BA_ "GenSigCycleTime" SG_ 2481980708 RampHeightOutsideTargetRange_ISi 100;
BA_ "GenSigCycleTimeActive" SG_ 2481980708 RampHeightOutsideTargetRange_ISi 100;
BA_ "GenSigStartValue" SG_ 2481980708 RampHeightOutsideTargetRange_ISi 7;
BA_ "GenSigMaxLatency" SG_ 2481980708 RampHeightOutsideTargetRange_ISi 117;
BA_ "Platform_VMCU1_Sig" SG_ 2481980708 RampHeightOutsideTargetRange_ISi 1;
BA_ "SystemSignalLongSymbol" SG_ 2481980708 RampHeightOutsideTargetRange_ISi "RampHeightOutsideTargetRange_ISig_4";
BA_ "GenSigCycleTime" SG_ 2481980708 DriveLevelPosUserInteraction_ISi 100;
BA_ "GenSigCycleTimeActive" SG_ 2481980708 DriveLevelPosUserInteraction_ISi 100;
BA_ "GenSigStartValue" SG_ 2481980708 DriveLevelPosUserInteraction_ISi 7;
BA_ "Platform_VMCU1_Sig" SG_ 2481980708 DriveLevelPosUserInteraction_ISi 1;
BA_ "SystemSignalLongSymbol" SG_ 2481980708 DriveLevelPosUserInteraction_ISi "DriveLevelPosUserInteraction_ISig_4";
BA_ "GenSigCycleTime" SG_ 2481980708 RearEndPositionStatus_ISig_4 100;
BA_ "GenSigCycleTimeActive" SG_ 2481980708 RearEndPositionStatus_ISig_4 100;
BA_ "GenSigStartValue" SG_ 2481980708 RearEndPositionStatus_ISig_4 7;
BA_ "GenSigMaxLatency" SG_ 2481980708 RearEndPositionStatus_ISig_4 117;
BA_ "Platform_VMCU1_Sig" SG_ 2481980708 RearEndPositionStatus_ISig_4 1;
BA_ "GenSigCycleTime" SG_ 2481980708 ProhibitControlStatus_ISig_4 100;
BA_ "GenSigCycleTimeActive" SG_ 2481980708 ProhibitControlStatus_ISig_4 100;
BA_ "GenSigStartValue" SG_ 2481980708 ProhibitControlStatus_ISig_4 3;
BA_ "GenSigMaxLatency" SG_ 2481980708 ProhibitControlStatus_ISig_4 117;
BA_ "Platform_VMCU1_Sig" SG_ 2481980708 ProhibitControlStatus_ISig_4 1;
BA_ "GenSigCycleTime" SG_ 2481980708 ChangeKneelACK_ISig_4 100;
BA_ "GenSigCycleTimeActive" SG_ 2481980708 ChangeKneelACK_ISig_4 100;
BA_ "GenSigStartValue" SG_ 2481980708 ChangeKneelACK_ISig_4 3;
BA_ "Platform_VMCU1_Sig" SG_ 2481980708 ChangeKneelACK_ISig_4 1;
BA_ "GenSigCycleTime" SG_ 2481980708 RollEndPositionStatus_ISig_4 100;
BA_ "GenSigCycleTimeActive" SG_ 2481980708 RollEndPositionStatus_ISig_4 100;
BA_ "GenSigStartValue" SG_ 2481980708 RollEndPositionStatus_ISig_4 7;
BA_ "GenSigMaxLatency" SG_ 2481980708 RollEndPositionStatus_ISig_4 117;
BA_ "Platform_VMCU1_Sig" SG_ 2481980708 RollEndPositionStatus_ISig_4 1;
BA_ "GenSigSendType" SG_ 2481980708 RearAxleInBumperRange_UB_ISig_4 7;
BA_ "Platform_VMCU1_Sig" SG_ 2481980708 RearAxleInBumperRange_UB_ISig_4 1;
BA_ "GenSigCycleTime" SG_ 2481980708 TransferCaseBadCondition 100;
BA_ "GenSigCycleTimeActive" SG_ 2481980708 TransferCaseBadCondition 100;
BA_ "GenSigStartValue" SG_ 2481980708 TransferCaseBadCondition 7;
BA_ "Platform_VMCU1_Sig" SG_ 2481980708 TransferCaseBadCondition 1;
BA_ "GenSigCycleTime" SG_ 2481980708 ECSStandbyAllowed_ISig_4 100;
BA_ "GenSigCycleTimeActive" SG_ 2481980708 ECSStandbyAllowed_ISig_4 100;
BA_ "GenSigStartValue" SG_ 2481980708 ECSStandbyAllowed_ISig_4 3;
BA_ "Platform_VMCU1_Sig" SG_ 2481980708 ECSStandbyAllowed_ISig_4 1;
BA_ "GenSigCycleTime" SG_ 2481980708 RearAxleInBumperRange_ISig_4 100;
BA_ "GenSigCycleTimeActive" SG_ 2481980708 RearAxleInBumperRange_ISig_4 100;
BA_ "GenSigStartValue" SG_ 2481980708 RearAxleInBumperRange_ISig_4 3;
BA_ "NeedsUpdateBit" SG_ 2481980708 RearAxleInBumperRange_ISig_4 1;
BA_ "Platform_VMCU1_Sig" SG_ 2481980708 RearAxleInBumperRange_ISig_4 1;
BA_ "SeToolAncestorID_SIGNAL" SG_ 2481980708 RearAxleInBumperRange_ISig_4 "x0000001D04149986";
BA_ "SeToolItemID_SIGNAL" SG_ 2481980708 RearAxleInBumperRange_ISig_4 "x0000001D04149986";
BA_ "SeToolName_SIGNAL" SG_ 2481980708 RearAxleInBumperRange_ISig_4 "RearAxleInBumperRange";
BA_ "SeToolVersion_SIGNAL" SG_ 2481980708 RearAxleInBumperRange_ISig_4 "1";
BA_ "GenSigCycleTime" SG_ 2515190820 RelativeLevelRearAxleRight_ISig_ 100;
BA_ "GenSigCycleTimeActive" SG_ 2515190820 RelativeLevelRearAxleRight_ISig_ 100;
BA_ "GenSigStartValue" SG_ 2515190820 RelativeLevelRearAxleRight_ISig_ 65535;
BA_ "Platform_VMCU1_Sig" SG_ 2515190820 RelativeLevelRearAxleRight_ISig_ 1;
BA_ "SeToolAncestorID_SIGNAL" SG_ 2515190820 RelativeLevelRearAxleRight_ISig_ "x0000001D0412EE40";
BA_ "SeToolItemID_SIGNAL" SG_ 2515190820 RelativeLevelRearAxleRight_ISig_ "x0000001D04384E50";
BA_ "SeToolName_SIGNAL" SG_ 2515190820 RelativeLevelRearAxleRight_ISig_ "RelativeLevelRearAxleRight";
BA_ "SeToolVersion_SIGNAL" SG_ 2515190820 RelativeLevelRearAxleRight_ISig_ "2";
BA_ "SystemSignalLongSymbol" SG_ 2515190820 RelativeLevelRearAxleRight_ISig_ "RelativeLevelRearAxleRight_ISig_4";
BA_ "GenSigCycleTime" SG_ 2515190820 RelativeLevelFrontAxleRight_ISig 100;
BA_ "GenSigCycleTimeActive" SG_ 2515190820 RelativeLevelFrontAxleRight_ISig 100;
BA_ "GenSigStartValue" SG_ 2515190820 RelativeLevelFrontAxleRight_ISig 65535;
BA_ "Platform_VMCU1_Sig" SG_ 2515190820 RelativeLevelFrontAxleRight_ISig 1;
BA_ "SeToolAncestorID_SIGNAL" SG_ 2515190820 RelativeLevelFrontAxleRight_ISig "x0000001D0412EE3C";
BA_ "SeToolItemID_SIGNAL" SG_ 2515190820 RelativeLevelFrontAxleRight_ISig "x0000001D04384E33";
BA_ "SeToolName_SIGNAL" SG_ 2515190820 RelativeLevelFrontAxleRight_ISig "RelativeLevelFrontAxleRight";
BA_ "SeToolVersion_SIGNAL" SG_ 2515190820 RelativeLevelFrontAxleRight_ISig "2";
BA_ "SystemSignalLongSymbol" SG_ 2515190820 RelativeLevelFrontAxleRight_ISig "RelativeLevelFrontAxleRight_ISig_4";
BA_ "GenSigCycleTime" SG_ 2515190820 RelativeLevelFrontAxleLeft_ISig_ 100;
BA_ "GenSigCycleTimeActive" SG_ 2515190820 RelativeLevelFrontAxleLeft_ISig_ 100;
BA_ "GenSigStartValue" SG_ 2515190820 RelativeLevelFrontAxleLeft_ISig_ 65535;
BA_ "Platform_VMCU1_Sig" SG_ 2515190820 RelativeLevelFrontAxleLeft_ISig_ 1;
BA_ "SeToolAncestorID_SIGNAL" SG_ 2515190820 RelativeLevelFrontAxleLeft_ISig_ "x0000001D0412EE39";
BA_ "SeToolItemID_SIGNAL" SG_ 2515190820 RelativeLevelFrontAxleLeft_ISig_ "x0000001D04384DFD";
BA_ "SeToolName_SIGNAL" SG_ 2515190820 RelativeLevelFrontAxleLeft_ISig_ "RelativeLevelFrontAxleLeft";
BA_ "SeToolVersion_SIGNAL" SG_ 2515190820 RelativeLevelFrontAxleLeft_ISig_ "2";
BA_ "SystemSignalLongSymbol" SG_ 2515190820 RelativeLevelFrontAxleLeft_ISig_ "RelativeLevelFrontAxleLeft_ISig_4";
BA_ "GenSigCycleTime" SG_ 2515190820 RelativeLevelRearAxleLeft_ISig_4 100;
BA_ "GenSigCycleTimeActive" SG_ 2515190820 RelativeLevelRearAxleLeft_ISig_4 100;
BA_ "GenSigStartValue" SG_ 2515190820 RelativeLevelRearAxleLeft_ISig_4 65535;
BA_ "Platform_VMCU1_Sig" SG_ 2515190820 RelativeLevelRearAxleLeft_ISig_4 1;
BA_ "SeToolAncestorID_SIGNAL" SG_ 2515190820 RelativeLevelRearAxleLeft_ISig_4 "x0000001D0412EE3E";
BA_ "SeToolItemID_SIGNAL" SG_ 2515190820 RelativeLevelRearAxleLeft_ISig_4 "x0000001D04384E3D";
BA_ "SeToolName_SIGNAL" SG_ 2515190820 RelativeLevelRearAxleLeft_ISig_4 "RelativeLevelRearAxleLeft";
BA_ "SeToolVersion_SIGNAL" SG_ 2515190820 RelativeLevelRearAxleLeft_ISig_4 "2";
BA_ "GenSigCycleTime" SG_ 2549579812 RefrigTimer_rqst_DayOfWeekRq 100;
BA_ "GenSigCycleTimeActive" SG_ 2549579812 RefrigTimer_rqst_DayOfWeekRq 100;
BA_ "GenSigStartValue" SG_ 2549579812 RefrigTimer_rqst_DayOfWeekRq 15;
BA_ "Platform_VMCU1_Sig" SG_ 2549579812 RefrigTimer_rqst_DayOfWeekRq 1;
BA_ "GenSigCycleTime" SG_ 2549579812 RefrigTimer_rqst_Hours 100;
BA_ "GenSigCycleTimeActive" SG_ 2549579812 RefrigTimer_rqst_Hours 100;
BA_ "GenSigStartValue" SG_ 2549579812 RefrigTimer_rqst_Hours 255;
BA_ "Platform_VMCU1_Sig" SG_ 2549579812 RefrigTimer_rqst_Hours 1;
BA_ "GenSigCycleTime" SG_ 2549579812 RSLAssistStatus 100;
BA_ "GenSigCycleTimeActive" SG_ 2549579812 RSLAssistStatus 100;
BA_ "GenSigStartValue" SG_ 2549579812 RSLAssistStatus 7;
BA_ "GenSigCycleTime" SG_ 2549579812 RefrigTimer_rqst_SetAlarmOper 100;
BA_ "GenSigCycleTimeActive" SG_ 2549579812 RefrigTimer_rqst_SetAlarmOper 100;
BA_ "GenSigStartValue" SG_ 2549579812 RefrigTimer_rqst_SetAlarmOper 7;
BA_ "Platform_VMCU1_Sig" SG_ 2549579812 RefrigTimer_rqst_SetAlarmOper 1;
BA_ "GenSigCycleTime" SG_ 2549579812 RefrigTimer_rqst_Minutes 100;
BA_ "GenSigCycleTimeActive" SG_ 2549579812 RefrigTimer_rqst_Minutes 100;
BA_ "GenSigStartValue" SG_ 2549579812 RefrigTimer_rqst_Minutes 255;
BA_ "Platform_VMCU1_Sig" SG_ 2549579812 RefrigTimer_rqst_Minutes 1;
BA_ "GenSigCycleTime" SG_ 2549430564 HighResolutionTripDistance2_ISig 100;
BA_ "GenSigCycleTimeActive" SG_ 2549430564 HighResolutionTripDistance2_ISig 100;
BA_ "GenSigStartValue" SG_ 2549430564 HighResolutionTripDistance2_ISig 4294967295;
BA_ "GenSigMaxLatency" SG_ 2549430564 HighResolutionTripDistance2_ISig 251;
BA_ "Platform_VMCU1_Sig" SG_ 2549430564 HighResolutionTripDistance2_ISig 1;
BA_ "SeToolAncestorID_SIGNAL" SG_ 2549430564 HighResolutionTripDistance2_ISig "x0000001D0417BFE5";
BA_ "SeToolItemID_SIGNAL" SG_ 2549430564 HighResolutionTripDistance2_ISig "x0000001D0417BFE5";
BA_ "SeToolName_SIGNAL" SG_ 2549430564 HighResolutionTripDistance2_ISig "HighResolutionTripDistance2";
BA_ "SeToolVersion_SIGNAL" SG_ 2549430564 HighResolutionTripDistance2_ISig "1";
BA_ "SystemSignalLongSymbol" SG_ 2549430564 HighResolutionTripDistance2_ISig "HighResolutionTripDistance2_ISig_4";
BA_ "GenSigCycleTime" SG_ 2549430564 HighResolutionTripDistance1_ISig 100;
BA_ "GenSigCycleTimeActive" SG_ 2549430564 HighResolutionTripDistance1_ISig 100;
BA_ "GenSigStartValue" SG_ 2549430564 HighResolutionTripDistance1_ISig 4294967295;
BA_ "GenSigMaxLatency" SG_ 2549430564 HighResolutionTripDistance1_ISig 251;
BA_ "Platform_VMCU1_Sig" SG_ 2549430564 HighResolutionTripDistance1_ISig 1;
BA_ "SeToolAncestorID_SIGNAL" SG_ 2549430564 HighResolutionTripDistance1_ISig "x0000001D0417BFE5";
BA_ "SeToolItemID_SIGNAL" SG_ 2549430564 HighResolutionTripDistance1_ISig "x0000001D0417BFE5";
BA_ "SeToolName_SIGNAL" SG_ 2549430564 HighResolutionTripDistance1_ISig "HighResolutionTripDistance1";
BA_ "SeToolVersion_SIGNAL" SG_ 2549430564 HighResolutionTripDistance1_ISig "1";
BA_ "SystemSignalLongSymbol" SG_ 2549430564 HighResolutionTripDistance1_ISig "HighResolutionTripDistance1_ISig_4";
BA_ "GenSigCycleTime" SG_ 2566559268 WasherFluidLevel_ISig_4 100;
BA_ "GenSigCycleTimeActive" SG_ 2566559268 WasherFluidLevel_ISig_4 100;
BA_ "GenSigStartValue" SG_ 2566559268 WasherFluidLevel_ISig_4 7;
BA_ "GenSigMaxLatency" SG_ 2566559268 WasherFluidLevel_ISig_4 1110;
BA_ "Platform_VMCU1_Sig" SG_ 2566559268 WasherFluidLevel_ISig_4 1;
BA_ "SeToolAncestorID_SIGNAL" SG_ 2566559268 WasherFluidLevel_ISig_4 "x0000001D04104D03";
BA_ "SeToolItemID_SIGNAL" SG_ 2566559268 WasherFluidLevel_ISig_4 "x0000001D0435D527";
BA_ "SeToolName_SIGNAL" SG_ 2566559268 WasherFluidLevel_ISig_4 "WasherFluidLevel";
BA_ "SeToolVersion_SIGNAL" SG_ 2566559268 WasherFluidLevel_ISig_4 "3";
BA_ "GenSigSendType" SG_ 2566559268 FuelVolume_UB_ISig_4 7;
BA_ "Platform_VMCU1_Sig" SG_ 2566559268 FuelVolume_UB_ISig_4 1;
BA_ "GenSigSendType" SG_ 2566559268 ManTransmiOilTemp_UB_ISig_4 7;
BA_ "Platform_VMCU1_Sig" SG_ 2566559268 ManTransmiOilTemp_UB_ISig_4 1;
BA_ "GenSigCycleTime" SG_ 2566559268 FuelVolume_ISig_4 100;
BA_ "GenSigCycleTimeActive" SG_ 2566559268 FuelVolume_ISig_4 100;
BA_ "GenSigStartValue" SG_ 2566559268 FuelVolume_ISig_4 2047;
BA_ "NeedsUpdateBit" SG_ 2566559268 FuelVolume_ISig_4 1;
BA_ "Platform_VMCU1_Sig" SG_ 2566559268 FuelVolume_ISig_4 1;
BA_ "GenSigCycleTime" SG_ 2566559268 KFactor 100;
BA_ "GenSigCycleTimeActive" SG_ 2566559268 KFactor 100;
BA_ "GenSigStartValue" SG_ 2566559268 KFactor 65535;
BA_ "GenSigMaxLatency" SG_ 2566559268 KFactor 511;
BA_ "Platform_VMCU1_Sig" SG_ 2566559268 KFactor 1;
BA_ "SeToolAncestorID_SIGNAL" SG_ 2566559268 KFactor "x0000001D0416ED52";
BA_ "SeToolItemID_SIGNAL" SG_ 2566559268 KFactor "x0000001D041B55DB";
BA_ "SeToolName_SIGNAL" SG_ 2566559268 KFactor "K-Factor";
BA_ "SeToolVersion_SIGNAL" SG_ 2566559268 KFactor "2";
BA_ "GenSigCycleTime" SG_ 2566559268 ManTransmiOilTemp_ISig_4 100;
BA_ "GenSigCycleTimeActive" SG_ 2566559268 ManTransmiOilTemp_ISig_4 100;
BA_ "GenSigStartValue" SG_ 2566559268 ManTransmiOilTemp_ISig_4 65535;
BA_ "NeedsUpdateBit" SG_ 2566559268 ManTransmiOilTemp_ISig_4 1;
BA_ "Platform_VMCU1_Sig" SG_ 2566559268 ManTransmiOilTemp_ISig_4 1;
BA_ "GenSigCycleTime" SG_ 2566559268 EngSpeedGreenAreaMode_ISig_4 100;
BA_ "GenSigCycleTimeActive" SG_ 2566559268 EngSpeedGreenAreaMode_ISig_4 100;
BA_ "GenSigStartValue" SG_ 2566559268 EngSpeedGreenAreaMode_ISig_4 7;
BA_ "Platform_VMCU1_Sig" SG_ 2566559268 EngSpeedGreenAreaMode_ISig_4 1;
BA_ "GenSigCycleTime" SG_ 2515721252 CabRoofSignLightFeedback_stat 100;
BA_ "GenSigCycleTimeActive" SG_ 2515721252 CabRoofSignLightFeedback_stat 100;
BA_ "GenSigStartValue" SG_ 2515721252 CabRoofSignLightFeedback_stat 3;
BA_ "Platform_VMCU1_Sig" SG_ 2515721252 CabRoofSignLightFeedback_stat 1;
BA_ "SeToolAncestorID_SIGNAL" SG_ 2515721252 CabRoofSignLightFeedback_stat "x0000001D041B0A30";
BA_ "SeToolItemID_SIGNAL" SG_ 2515721252 CabRoofSignLightFeedback_stat "x0000001D041B0A30";
BA_ "SeToolName_SIGNAL" SG_ 2515721252 CabRoofSignLightFeedback_stat "CabRoofSignLightFeedback_Status";
BA_ "SeToolVersion_SIGNAL" SG_ 2515721252 CabRoofSignLightFeedback_stat "1";
BA_ "GenSigCycleTime" SG_ 2515721252 TemporaryRSLStatus 100;
BA_ "GenSigCycleTimeActive" SG_ 2515721252 TemporaryRSLStatus 100;
BA_ "GenSigStartValue" SG_ 2515721252 TemporaryRSLStatus 3;
BA_ "Platform_VMCU1_Sig" SG_ 2515721252 TemporaryRSLStatus 1;
BA_ "GenSigCycleTime" SG_ 2515721252 CabExtraSideWrknLightFdbk_stat_I 100;
BA_ "GenSigCycleTimeActive" SG_ 2515721252 CabExtraSideWrknLightFdbk_stat_I 100;
BA_ "GenSigStartValue" SG_ 2515721252 CabExtraSideWrknLightFdbk_stat_I 3;
BA_ "GenSigMaxLatency" SG_ 2515721252 CabExtraSideWrknLightFdbk_stat_I 112;
BA_ "Platform_VMCU1_Sig" SG_ 2515721252 CabExtraSideWrknLightFdbk_stat_I 1;
BA_ "SeToolAncestorID_SIGNAL" SG_ 2515721252 CabExtraSideWrknLightFdbk_stat_I "x0000001D041B0A4B";
BA_ "SeToolItemID_SIGNAL" SG_ 2515721252 CabExtraSideWrknLightFdbk_stat_I "x0000001D041B0A4B";
BA_ "SeToolName_SIGNAL" SG_ 2515721252 CabExtraSideWrknLightFdbk_stat_I "CabExtraSideWorkingFeedback_Status";
BA_ "SeToolVersion_SIGNAL" SG_ 2515721252 CabExtraSideWrknLightFdbk_stat_I "1";
BA_ "SystemSignalLongSymbol" SG_ 2515721252 CabExtraSideWrknLightFdbk_stat_I "CabExtraSideWrknLightFdbk_stat_ISig_4";
BA_ "GenSigCycleTime" SG_ 2515721252 CabWrknLightChassisFdbk_stat_ISi 100;
BA_ "GenSigCycleTimeActive" SG_ 2515721252 CabWrknLightChassisFdbk_stat_ISi 100;
BA_ "GenSigStartValue" SG_ 2515721252 CabWrknLightChassisFdbk_stat_ISi 3;
BA_ "GenSigMaxLatency" SG_ 2515721252 CabWrknLightChassisFdbk_stat_ISi 112;
BA_ "Platform_VMCU1_Sig" SG_ 2515721252 CabWrknLightChassisFdbk_stat_ISi 1;
BA_ "SeToolAncestorID_SIGNAL" SG_ 2515721252 CabWrknLightChassisFdbk_stat_ISi "x0000001D041B0A49";
BA_ "SeToolItemID_SIGNAL" SG_ 2515721252 CabWrknLightChassisFdbk_stat_ISi "x0000001D041B0A49";
BA_ "SeToolName_SIGNAL" SG_ 2515721252 CabWrknLightChassisFdbk_stat_ISi "CabWorkingLightChassisFeedback_Status";
BA_ "SeToolVersion_SIGNAL" SG_ 2515721252 CabWrknLightChassisFdbk_stat_ISi "1";
BA_ "SystemSignalLongSymbol" SG_ 2515721252 CabWrknLightChassisFdbk_stat_ISi "CabWrknLightChassisFdbk_stat_ISig_4";
BA_ "GenSigCycleTime" SG_ 2515721252 HeadLightLevelRequest_stat 100;
BA_ "GenSigCycleTimeActive" SG_ 2515721252 HeadLightLevelRequest_stat 100;
BA_ "GenSigStartValue" SG_ 2515721252 HeadLightLevelRequest_stat 31;
BA_ "Platform_VMCU1_Sig" SG_ 2515721252 HeadLightLevelRequest_stat 1;
BA_ "GenSigCycleTime" SG_ 2515721252 CabTrailerBodyLgthnFdbk_stat 100;
BA_ "GenSigCycleTimeActive" SG_ 2515721252 CabTrailerBodyLgthnFdbk_stat 100;
BA_ "GenSigStartValue" SG_ 2515721252 CabTrailerBodyLgthnFdbk_stat 3;
BA_ "GenSigMaxLatency" SG_ 2515721252 CabTrailerBodyLgthnFdbk_stat 112;
BA_ "Platform_VMCU1_Sig" SG_ 2515721252 CabTrailerBodyLgthnFdbk_stat 1;
BA_ "SeToolAncestorID_SIGNAL" SG_ 2515721252 CabTrailerBodyLgthnFdbk_stat "x0000001D04206B2D";
BA_ "SeToolItemID_SIGNAL" SG_ 2515721252 CabTrailerBodyLgthnFdbk_stat "x0000001D04206B2D";
BA_ "SeToolName_SIGNAL" SG_ 2515721252 CabTrailerBodyLgthnFdbk_stat "CabTrailerBodyLightingFeedback_Status";
BA_ "SeToolVersion_SIGNAL" SG_ 2515721252 CabTrailerBodyLgthnFdbk_stat "1";
BA_ "GenSigCycleTime" SG_ 2515721252 DiffLockInterWhlStatusSplitBox_I 100;
BA_ "GenSigCycleTimeActive" SG_ 2515721252 DiffLockInterWhlStatusSplitBox_I 100;
BA_ "GenSigStartValue" SG_ 2515721252 DiffLockInterWhlStatusSplitBox_I 3;
BA_ "Platform_VMCU1_Sig" SG_ 2515721252 DiffLockInterWhlStatusSplitBox_I 1;
BA_ "SystemSignalLongSymbol" SG_ 2515721252 DiffLockInterWhlStatusSplitBox_I "DiffLockInterWhlStatusSplitBox_ISig_4";
BA_ "GenSigCycleTime" SG_ 2515721252 BodyOrCabWorkingLightFdbk_stat_I 100;
BA_ "GenSigCycleTimeActive" SG_ 2515721252 BodyOrCabWorkingLightFdbk_stat_I 100;
BA_ "GenSigStartValue" SG_ 2515721252 BodyOrCabWorkingLightFdbk_stat_I 3;
BA_ "GenSigMaxLatency" SG_ 2515721252 BodyOrCabWorkingLightFdbk_stat_I 112;
BA_ "Platform_VMCU1_Sig" SG_ 2515721252 BodyOrCabWorkingLightFdbk_stat_I 1;
BA_ "SeToolAncestorID_SIGNAL" SG_ 2515721252 BodyOrCabWorkingLightFdbk_stat_I "x0000001D041B0A46";
BA_ "SeToolItemID_SIGNAL" SG_ 2515721252 BodyOrCabWorkingLightFdbk_stat_I "x0000001D041B0A46";
BA_ "SeToolName_SIGNAL" SG_ 2515721252 BodyOrCabWorkingLightFdbk_stat_I "CabBody/CabWorkingLightFeedback_Status";
BA_ "SeToolVersion_SIGNAL" SG_ 2515721252 BodyOrCabWorkingLightFdbk_stat_I "1";
BA_ "SystemSignalLongSymbol" SG_ 2515721252 BodyOrCabWorkingLightFdbk_stat_I "BodyOrCabWorkingLightFdbk_stat_ISig_4";
BA_ "GenSigCycleTime" SG_ 2515721252 WheelBasedVehicleSpeedLowRes_ISi 100;
BA_ "GenSigCycleTimeActive" SG_ 2515721252 WheelBasedVehicleSpeedLowRes_ISi 100;
BA_ "GenSigStartValue" SG_ 2515721252 WheelBasedVehicleSpeedLowRes_ISi 255;
BA_ "GenSigMaxLatency" SG_ 2515721252 WheelBasedVehicleSpeedLowRes_ISi 112;
BA_ "Platform_VMCU1_Sig" SG_ 2515721252 WheelBasedVehicleSpeedLowRes_ISi 1;
BA_ "SeToolAncestorID_SIGNAL" SG_ 2515721252 WheelBasedVehicleSpeedLowRes_ISi "x0000001D041F9CE4";
BA_ "SeToolItemID_SIGNAL" SG_ 2515721252 WheelBasedVehicleSpeedLowRes_ISi "x0000001D041F9CE4";
BA_ "SeToolName_SIGNAL" SG_ 2515721252 WheelBasedVehicleSpeedLowRes_ISi "Wheel-BasedVehicleSpeedLowRes";
BA_ "SeToolVersion_SIGNAL" SG_ 2515721252 WheelBasedVehicleSpeedLowRes_ISi "1";
BA_ "SystemSignalLongSymbol" SG_ 2515721252 WheelBasedVehicleSpeedLowRes_ISi "WheelBasedVehicleSpeedLowRes_ISig_4";
BA_ "GenSigCycleTime" SG_ 2515721252 AirDryerCoolingFanSpeed_rqst 100;
BA_ "GenSigCycleTimeActive" SG_ 2515721252 AirDryerCoolingFanSpeed_rqst 100;
BA_ "GenSigStartValue" SG_ 2515721252 AirDryerCoolingFanSpeed_rqst 65535;
BA_ "GenSigMaxLatency" SG_ 2515721252 AirDryerCoolingFanSpeed_rqst 112;
BA_ "NeedsUpdateBit" SG_ 2515721252 AirDryerCoolingFanSpeed_rqst 1;
BA_ "Platform_VMCU1_Sig" SG_ 2515721252 AirDryerCoolingFanSpeed_rqst 1;
BA_ "SeToolAncestorID_SIGNAL" SG_ 2515721252 AirDryerCoolingFanSpeed_rqst "x0000001D0425B656";
BA_ "SeToolItemID_SIGNAL" SG_ 2515721252 AirDryerCoolingFanSpeed_rqst "x0000001D043C814A";
BA_ "SeToolName_SIGNAL" SG_ 2515721252 AirDryerCoolingFanSpeed_rqst "AirDryerCoolingFanSpeed_rqst";
BA_ "SeToolVersion_SIGNAL" SG_ 2515721252 AirDryerCoolingFanSpeed_rqst "2";
BA_ "GenSigCycleTime" SG_ 2515721252 CabFrontSpotFeedback_Status 100;
BA_ "GenSigCycleTimeActive" SG_ 2515721252 CabFrontSpotFeedback_Status 100;
BA_ "GenSigStartValue" SG_ 2515721252 CabFrontSpotFeedback_Status 3;
BA_ "GenSigMaxLatency" SG_ 2515721252 CabFrontSpotFeedback_Status 112;
BA_ "Platform_VMCU1_Sig" SG_ 2515721252 CabFrontSpotFeedback_Status 1;
BA_ "SeToolAncestorID_SIGNAL" SG_ 2515721252 CabFrontSpotFeedback_Status "x0000001D041B0A34";
BA_ "SeToolItemID_SIGNAL" SG_ 2515721252 CabFrontSpotFeedback_Status "x0000001D041B0A34";
BA_ "SeToolName_SIGNAL" SG_ 2515721252 CabFrontSpotFeedback_Status "CabFrontSpotFeedback_Status";
BA_ "SeToolVersion_SIGNAL" SG_ 2515721252 CabFrontSpotFeedback_Status "1";
BA_ "GenSigCycleTime" SG_ 2515721252 CabTiltEnableStatus 100;
BA_ "GenSigCycleTimeActive" SG_ 2515721252 CabTiltEnableStatus 100;
BA_ "GenSigStartValue" SG_ 2515721252 CabTiltEnableStatus 3;
BA_ "GenSigMaxLatency" SG_ 2515721252 CabTiltEnableStatus 112;
BA_ "Platform_VMCU1_Sig" SG_ 2515721252 CabTiltEnableStatus 1;
BA_ "SeToolAncestorID_SIGNAL" SG_ 2515721252 CabTiltEnableStatus "x0000001D04173E71";
BA_ "SeToolItemID_SIGNAL" SG_ 2515721252 CabTiltEnableStatus "x0000001D0419EA6D";
BA_ "SeToolName_SIGNAL" SG_ 2515721252 CabTiltEnableStatus "CabTiltEnableStatus";
BA_ "SeToolVersion_SIGNAL" SG_ 2515721252 CabTiltEnableStatus "2";
BA_ "GenSigCycleTime" SG_ 2515721252 TransmReverseDirectionSw_stat_IS 100;
BA_ "GenSigCycleTimeActive" SG_ 2515721252 TransmReverseDirectionSw_stat_IS 100;
BA_ "GenSigStartValue" SG_ 2515721252 TransmReverseDirectionSw_stat_IS 3;
BA_ "Platform_VMCU1_Sig" SG_ 2515721252 TransmReverseDirectionSw_stat_IS 1;
BA_ "SystemSignalLongSymbol" SG_ 2515721252 TransmReverseDirectionSw_stat_IS "TransmReverseDirectionSw_stat_ISig_4";
BA_ "GenSigCycleTime" SG_ 2515721252 CabRoofSpotFeedback_Status 100;
BA_ "GenSigCycleTimeActive" SG_ 2515721252 CabRoofSpotFeedback_Status 100;
BA_ "GenSigStartValue" SG_ 2515721252 CabRoofSpotFeedback_Status 3;
BA_ "GenSigMaxLatency" SG_ 2515721252 CabRoofSpotFeedback_Status 112;
BA_ "Platform_VMCU1_Sig" SG_ 2515721252 CabRoofSpotFeedback_Status 1;
BA_ "SeToolAncestorID_SIGNAL" SG_ 2515721252 CabRoofSpotFeedback_Status "x0000001D041B0A36";
BA_ "SeToolItemID_SIGNAL" SG_ 2515721252 CabRoofSpotFeedback_Status "x0000001D041B0A36";
BA_ "SeToolName_SIGNAL" SG_ 2515721252 CabRoofSpotFeedback_Status "CabRoofSpotFeedback_Status";
BA_ "SeToolVersion_SIGNAL" SG_ 2515721252 CabRoofSpotFeedback_Status "1";
BA_ "GenSigCycleTime" SG_ 2515721252 CabBeaconLightFeedback_Status_IS 100;
BA_ "GenSigCycleTimeActive" SG_ 2515721252 CabBeaconLightFeedback_Status_IS 100;
BA_ "GenSigStartValue" SG_ 2515721252 CabBeaconLightFeedback_Status_IS 3;
BA_ "GenSigMaxLatency" SG_ 2515721252 CabBeaconLightFeedback_Status_IS 112;
BA_ "Platform_VMCU1_Sig" SG_ 2515721252 CabBeaconLightFeedback_Status_IS 1;
BA_ "SeToolAncestorID_SIGNAL" SG_ 2515721252 CabBeaconLightFeedback_Status_IS "x0000001D041B0A09";
BA_ "SeToolItemID_SIGNAL" SG_ 2515721252 CabBeaconLightFeedback_Status_IS "x0000001D041B0A09";
BA_ "SeToolName_SIGNAL" SG_ 2515721252 CabBeaconLightFeedback_Status_IS "CabBeaconLightFeedback_Status";
BA_ "SeToolVersion_SIGNAL" SG_ 2515721252 CabBeaconLightFeedback_Status_IS "1";
BA_ "SystemSignalLongSymbol" SG_ 2515721252 CabBeaconLightFeedback_Status_IS "CabBeaconLightFeedback_Status_ISig_4";
BA_ "GenSigCycleTime" SG_ 2515721252 ExtraAxleSteeringFunctionStat_IS 100;
BA_ "GenSigCycleTimeActive" SG_ 2515721252 ExtraAxleSteeringFunctionStat_IS 100;
BA_ "GenSigStartValue" SG_ 2515721252 ExtraAxleSteeringFunctionStat_IS 7;
BA_ "Platform_VMCU1_Sig" SG_ 2515721252 ExtraAxleSteeringFunctionStat_IS 1;
BA_ "SystemSignalLongSymbol" SG_ 2515721252 ExtraAxleSteeringFunctionStat_IS "ExtraAxleSteeringFunctionStat_ISig_4";
BA_ "GenSigSendType" SG_ 2515721252 AirDryerCoolingFanSpeed_rqst_UB 7;
BA_ "GenSigCycleTime" SG_ 2515721252 AirDryerCoolingFanSpeed_rqst_UB 100;
BA_ "GenSigCycleTimeActive" SG_ 2515721252 AirDryerCoolingFanSpeed_rqst_UB 100;
BA_ "Platform_VMCU1_Sig" SG_ 2515721252 AirDryerCoolingFanSpeed_rqst_UB 1;
BA_ "GenSigCycleTime" SG_ 2515721252 CabTiltLockStatus_ISig_4 100;
BA_ "GenSigCycleTimeActive" SG_ 2515721252 CabTiltLockStatus_ISig_4 100;
BA_ "GenSigStartValue" SG_ 2515721252 CabTiltLockStatus_ISig_4 3;
BA_ "GenSigMaxLatency" SG_ 2515721252 CabTiltLockStatus_ISig_4 112;
BA_ "Platform_VMCU1_Sig" SG_ 2515721252 CabTiltLockStatus_ISig_4 1;
BA_ "SeToolAncestorID_SIGNAL" SG_ 2515721252 CabTiltLockStatus_ISig_4 "x0000001D04173E82";
BA_ "SeToolItemID_SIGNAL" SG_ 2515721252 CabTiltLockStatus_ISig_4 "x0000001D041D94E8";
BA_ "SeToolName_SIGNAL" SG_ 2515721252 CabTiltLockStatus_ISig_4 "CabTiltLockStatus";
BA_ "SeToolVersion_SIGNAL" SG_ 2515721252 CabTiltLockStatus_ISig_4 "2";
BA_ "GenSigCycleTime" SG_ 2515721252 PositionLightRearLamp_stat_ISig_ 100;
BA_ "GenSigCycleTimeActive" SG_ 2515721252 PositionLightRearLamp_stat_ISig_ 100;
BA_ "GenSigStartValue" SG_ 2515721252 PositionLightRearLamp_stat_ISig_ 7;
BA_ "Platform_VMCU1_Sig" SG_ 2515721252 PositionLightRearLamp_stat_ISig_ 1;
BA_ "SystemSignalLongSymbol" SG_ 2515721252 PositionLightRearLamp_stat_ISig_ "PositionLightRearLamp_stat_ISig_4";
BA_ "GenSigCycleTime" SG_ 2498842916 Pto1BadCondition_ISig_4 100;
BA_ "GenSigCycleTimeActive" SG_ 2498842916 Pto1BadCondition_ISig_4 100;
BA_ "GenSigStartValue" SG_ 2498842916 Pto1BadCondition_ISig_4 15;
BA_ "GenSigMaxLatency" SG_ 2498842916 Pto1BadCondition_ISig_4 110;
BA_ "Platform_VMCU1_Sig" SG_ 2498842916 Pto1BadCondition_ISig_4 1;
BA_ "SeToolAncestorID_SIGNAL" SG_ 2498842916 Pto1BadCondition_ISig_4 "x0000001D042DDF2A";
BA_ "SeToolItemID_SIGNAL" SG_ 2498842916 Pto1BadCondition_ISig_4 "x0000001D042DDF2A";
BA_ "SeToolName_SIGNAL" SG_ 2498842916 Pto1BadCondition_ISig_4 "Pto1BadCondition";
BA_ "SeToolVersion_SIGNAL" SG_ 2498842916 Pto1BadCondition_ISig_4 "1";
BA_ "GenSigSendType" SG_ 2498842916 PtosStatus_UB_ISig_4 7;
BA_ "Platform_VMCU1_Sig" SG_ 2498842916 PtosStatus_UB_ISig_4 1;
BA_ "GenSigCycleTime" SG_ 2498842916 Pto4BadCondition 100;
BA_ "GenSigCycleTimeActive" SG_ 2498842916 Pto4BadCondition 100;
BA_ "GenSigStartValue" SG_ 2498842916 Pto4BadCondition 15;
BA_ "GenSigMaxLatency" SG_ 2498842916 Pto4BadCondition 110;
BA_ "Platform_VMCU1_Sig" SG_ 2498842916 Pto4BadCondition 1;
BA_ "SeToolAncestorID_SIGNAL" SG_ 2498842916 Pto4BadCondition "x0000001D042DE32A";
BA_ "SeToolItemID_SIGNAL" SG_ 2498842916 Pto4BadCondition "x0000001D042DE32A";
BA_ "SeToolName_SIGNAL" SG_ 2498842916 Pto4BadCondition "Pto4BadCondition";
BA_ "SeToolVersion_SIGNAL" SG_ 2498842916 Pto4BadCondition "1";
BA_ "GenSigCycleTime" SG_ 2498842916 Pto2BadCondition 100;
BA_ "GenSigCycleTimeActive" SG_ 2498842916 Pto2BadCondition 100;
BA_ "GenSigStartValue" SG_ 2498842916 Pto2BadCondition 15;
BA_ "GenSigMaxLatency" SG_ 2498842916 Pto2BadCondition 110;
BA_ "Platform_VMCU1_Sig" SG_ 2498842916 Pto2BadCondition 1;
BA_ "SeToolAncestorID_SIGNAL" SG_ 2498842916 Pto2BadCondition "x0000001D042DE326";
BA_ "SeToolItemID_SIGNAL" SG_ 2498842916 Pto2BadCondition "x0000001D042DE326";
BA_ "SeToolName_SIGNAL" SG_ 2498842916 Pto2BadCondition "Pto2BadCondition";
BA_ "SeToolVersion_SIGNAL" SG_ 2498842916 Pto2BadCondition "1";
BA_ "GenSigCycleTime" SG_ 2498842916 PtoRequest 100;
BA_ "GenSigCycleTimeActive" SG_ 2498842916 PtoRequest 100;
BA_ "GenSigStartValue" SG_ 2498842916 PtoRequest 3;
BA_ "Platform_VMCU1_Sig" SG_ 2498842916 PtoRequest 1;
BA_ "GenSigCycleTime" SG_ 2498842916 Pto2ConsentRequest 100;
BA_ "GenSigCycleTimeActive" SG_ 2498842916 Pto2ConsentRequest 100;
BA_ "GenSigStartValue" SG_ 2498842916 Pto2ConsentRequest 3;
BA_ "GenSigMaxLatency" SG_ 2498842916 Pto2ConsentRequest 110;
BA_ "Platform_VMCU1_Sig" SG_ 2498842916 Pto2ConsentRequest 1;
BA_ "SeToolAncestorID_SIGNAL" SG_ 2498842916 Pto2ConsentRequest "x0000001D04156EA0";
BA_ "SeToolItemID_SIGNAL" SG_ 2498842916 Pto2ConsentRequest "x0000001D043A5C95";
BA_ "SeToolName_SIGNAL" SG_ 2498842916 Pto2ConsentRequest "Pto2ConsentRequest";
BA_ "SeToolVersion_SIGNAL" SG_ 2498842916 Pto2ConsentRequest "2";
BA_ "GenSigCycleTime" SG_ 2498842916 PBStatusDisplay_cmd_ISig_4 100;
BA_ "GenSigCycleTimeActive" SG_ 2498842916 PBStatusDisplay_cmd_ISig_4 100;
BA_ "GenSigStartValue" SG_ 2498842916 PBStatusDisplay_cmd_ISig_4 3;
BA_ "Platform_VMCU1_Sig" SG_ 2498842916 PBStatusDisplay_cmd_ISig_4 1;
BA_ "GenSigCycleTime" SG_ 2498842916 Pto4DrivingRequest 100;
BA_ "GenSigCycleTimeActive" SG_ 2498842916 Pto4DrivingRequest 100;
BA_ "GenSigStartValue" SG_ 2498842916 Pto4DrivingRequest 3;
BA_ "GenSigMaxLatency" SG_ 2498842916 Pto4DrivingRequest 110;
BA_ "Platform_VMCU1_Sig" SG_ 2498842916 Pto4DrivingRequest 1;
BA_ "SeToolAncestorID_SIGNAL" SG_ 2498842916 Pto4DrivingRequest "x0000001D041538FE";
BA_ "SeToolItemID_SIGNAL" SG_ 2498842916 Pto4DrivingRequest "x0000001D041538FE";
BA_ "SeToolName_SIGNAL" SG_ 2498842916 Pto4DrivingRequest "Pto4DrivingRequest";
BA_ "SeToolVersion_SIGNAL" SG_ 2498842916 Pto4DrivingRequest "1";
BA_ "GenSigCycleTime" SG_ 2498842916 Pto3Indication 100;
BA_ "GenSigCycleTimeActive" SG_ 2498842916 Pto3Indication 100;
BA_ "GenSigStartValue" SG_ 2498842916 Pto3Indication 3;
BA_ "Platform_VMCU1_Sig" SG_ 2498842916 Pto3Indication 1;
BA_ "GenSigCycleTime" SG_ 2498842916 Pto2Status_ISig_4 100;
BA_ "GenSigCycleTimeActive" SG_ 2498842916 Pto2Status_ISig_4 100;
BA_ "GenSigStartValue" SG_ 2498842916 Pto2Status_ISig_4 3;
BA_ "GenSigMaxLatency" SG_ 2498842916 Pto2Status_ISig_4 110;
BA_ "Platform_VMCU1_Sig" SG_ 2498842916 Pto2Status_ISig_4 1;
BA_ "SeToolAncestorID_SIGNAL" SG_ 2498842916 Pto2Status_ISig_4 "x0000001D041534A5";
BA_ "SeToolItemID_SIGNAL" SG_ 2498842916 Pto2Status_ISig_4 "x0000001D04321002";
BA_ "SeToolName_SIGNAL" SG_ 2498842916 Pto2Status_ISig_4 "Pto2Status";
BA_ "SeToolVersion_SIGNAL" SG_ 2498842916 Pto2Status_ISig_4 "3";
BA_ "GenSigCycleTime" SG_ 2498842916 Pto4Status_ISig_4 100;
BA_ "GenSigCycleTimeActive" SG_ 2498842916 Pto4Status_ISig_4 100;
BA_ "GenSigStartValue" SG_ 2498842916 Pto4Status_ISig_4 3;
BA_ "GenSigMaxLatency" SG_ 2498842916 Pto4Status_ISig_4 110;
BA_ "Platform_VMCU1_Sig" SG_ 2498842916 Pto4Status_ISig_4 1;
BA_ "SeToolAncestorID_SIGNAL" SG_ 2498842916 Pto4Status_ISig_4 "x0000001D041534AC";
BA_ "SeToolItemID_SIGNAL" SG_ 2498842916 Pto4Status_ISig_4 "x0000001D04321056";
BA_ "SeToolName_SIGNAL" SG_ 2498842916 Pto4Status_ISig_4 "Pto4Status";
BA_ "SeToolVersion_SIGNAL" SG_ 2498842916 Pto4Status_ISig_4 "3";
BA_ "GenSigCycleTime" SG_ 2498842916 RampLevelRequestACK_ISig_4 100;
BA_ "GenSigCycleTimeActive" SG_ 2498842916 RampLevelRequestACK_ISig_4 100;
BA_ "GenSigStartValue" SG_ 2498842916 RampLevelRequestACK_ISig_4 3;
BA_ "Platform_VMCU1_Sig" SG_ 2498842916 RampLevelRequestACK_ISig_4 1;
BA_ "GenSigCycleTime" SG_ 2498842916 Pto3BadCondition 100;
BA_ "GenSigCycleTimeActive" SG_ 2498842916 Pto3BadCondition 100;
BA_ "GenSigStartValue" SG_ 2498842916 Pto3BadCondition 15;
BA_ "GenSigMaxLatency" SG_ 2498842916 Pto3BadCondition 110;
BA_ "Platform_VMCU1_Sig" SG_ 2498842916 Pto3BadCondition 1;
BA_ "SeToolAncestorID_SIGNAL" SG_ 2498842916 Pto3BadCondition "x0000001D042DE328";
BA_ "SeToolItemID_SIGNAL" SG_ 2498842916 Pto3BadCondition "x0000001D042DE328";
BA_ "SeToolName_SIGNAL" SG_ 2498842916 Pto3BadCondition "Pto3BadCondition";
BA_ "SeToolVersion_SIGNAL" SG_ 2498842916 Pto3BadCondition "1";
BA_ "GenSigCycleTime" SG_ 2498842916 PtosStatus_ISig_4 100;
BA_ "GenSigCycleTimeActive" SG_ 2498842916 PtosStatus_ISig_4 100;
BA_ "GenSigStartValue" SG_ 2498842916 PtosStatus_ISig_4 3;
BA_ "GenSigMaxLatency" SG_ 2498842916 PtosStatus_ISig_4 110;
BA_ "NeedsUpdateBit" SG_ 2498842916 PtosStatus_ISig_4 1;
BA_ "Platform_VMCU1_Sig" SG_ 2498842916 PtosStatus_ISig_4 1;
BA_ "SeToolAncestorID_SIGNAL" SG_ 2498842916 PtosStatus_ISig_4 "x0000001D042CA490";
BA_ "SeToolItemID_SIGNAL" SG_ 2498842916 PtosStatus_ISig_4 "x0000001D042CA490";
BA_ "SeToolName_SIGNAL" SG_ 2498842916 PtosStatus_ISig_4 "PtosStatus";
BA_ "SeToolVersion_SIGNAL" SG_ 2498842916 PtosStatus_ISig_4 "1";
BA_ "GenSigCycleTime" SG_ 2498842916 FrontWheelDriveAutoStatus_ISig_4 100;
BA_ "GenSigCycleTimeActive" SG_ 2498842916 FrontWheelDriveAutoStatus_ISig_4 100;
BA_ "GenSigStartValue" SG_ 2498842916 FrontWheelDriveAutoStatus_ISig_4 3;
BA_ "Platform_VMCU1_Sig" SG_ 2498842916 FrontWheelDriveAutoStatus_ISig_4 1;
BA_ "GenSigCycleTime" SG_ 2498842916 Pto1ConsentRequest 100;
BA_ "GenSigCycleTimeActive" SG_ 2498842916 Pto1ConsentRequest 100;
BA_ "GenSigStartValue" SG_ 2498842916 Pto1ConsentRequest 3;
BA_ "GenSigMaxLatency" SG_ 2498842916 Pto1ConsentRequest 110;
BA_ "Platform_VMCU1_Sig" SG_ 2498842916 Pto1ConsentRequest 1;
BA_ "SeToolAncestorID_SIGNAL" SG_ 2498842916 Pto1ConsentRequest "x0000001D04156E9D";
BA_ "SeToolItemID_SIGNAL" SG_ 2498842916 Pto1ConsentRequest "x0000001D043A5C3F";
BA_ "SeToolName_SIGNAL" SG_ 2498842916 Pto1ConsentRequest "Pto1ConsentRequest";
BA_ "SeToolVersion_SIGNAL" SG_ 2498842916 Pto1ConsentRequest "2";
BA_ "GenSigCycleTime" SG_ 2498842916 Pto4Indication 100;
BA_ "GenSigCycleTimeActive" SG_ 2498842916 Pto4Indication 100;
BA_ "GenSigStartValue" SG_ 2498842916 Pto4Indication 3;
BA_ "Platform_VMCU1_Sig" SG_ 2498842916 Pto4Indication 1;
BA_ "GenSigSendType" SG_ 2498842916 Pto1FeedbackStatus_UB_ISig_4 7;
BA_ "Platform_VMCU1_Sig" SG_ 2498842916 Pto1FeedbackStatus_UB_ISig_4 1;
BA_ "GenSigCycleTime" SG_ 2498842916 Pto1Indication 100;
BA_ "GenSigCycleTimeActive" SG_ 2498842916 Pto1Indication 100;
BA_ "GenSigStartValue" SG_ 2498842916 Pto1Indication 3;
BA_ "Platform_VMCU1_Sig" SG_ 2498842916 Pto1Indication 1;
BA_ "GenSigCycleTime" SG_ 2498842916 Pto3Status_ISig_4 100;
BA_ "GenSigCycleTimeActive" SG_ 2498842916 Pto3Status_ISig_4 100;
BA_ "GenSigStartValue" SG_ 2498842916 Pto3Status_ISig_4 3;
BA_ "GenSigMaxLatency" SG_ 2498842916 Pto3Status_ISig_4 110;
BA_ "Platform_VMCU1_Sig" SG_ 2498842916 Pto3Status_ISig_4 1;
BA_ "SeToolAncestorID_SIGNAL" SG_ 2498842916 Pto3Status_ISig_4 "x0000001D041534A7";
BA_ "SeToolItemID_SIGNAL" SG_ 2498842916 Pto3Status_ISig_4 "x0000001D04321034";
BA_ "SeToolName_SIGNAL" SG_ 2498842916 Pto3Status_ISig_4 "Pto3Status";
BA_ "SeToolVersion_SIGNAL" SG_ 2498842916 Pto3Status_ISig_4 "3";
BA_ "GenSigCycleTime" SG_ 2498842916 Pto2Indication 100;
BA_ "GenSigCycleTimeActive" SG_ 2498842916 Pto2Indication 100;
BA_ "GenSigStartValue" SG_ 2498842916 Pto2Indication 3;
BA_ "Platform_VMCU1_Sig" SG_ 2498842916 Pto2Indication 1;
BA_ "GenSigCycleTime" SG_ 2498842916 Pto1FeedbackStatus_ISig_4 100;
BA_ "GenSigCycleTimeActive" SG_ 2498842916 Pto1FeedbackStatus_ISig_4 100;
BA_ "GenSigStartValue" SG_ 2498842916 Pto1FeedbackStatus_ISig_4 3;
BA_ "GenSigMaxLatency" SG_ 2498842916 Pto1FeedbackStatus_ISig_4 110;
BA_ "NeedsUpdateBit" SG_ 2498842916 Pto1FeedbackStatus_ISig_4 1;
BA_ "Platform_VMCU1_Sig" SG_ 2498842916 Pto1FeedbackStatus_ISig_4 1;
BA_ "SeToolAncestorID_SIGNAL" SG_ 2498842916 Pto1FeedbackStatus_ISig_4 "x0000001D041538D8";
BA_ "SeToolItemID_SIGNAL" SG_ 2498842916 Pto1FeedbackStatus_ISig_4 "x0000001D041538D8";
BA_ "SeToolName_SIGNAL" SG_ 2498842916 Pto1FeedbackStatus_ISig_4 "Pto1FeedbackStatus";
BA_ "SeToolVersion_SIGNAL" SG_ 2498842916 Pto1FeedbackStatus_ISig_4 "1";
BA_ "GenSigCycleTime" SG_ 2498842916 TransferCaseOrSplitboxPTOMode_IS 100;
BA_ "GenSigCycleTimeActive" SG_ 2498842916 TransferCaseOrSplitboxPTOMode_IS 100;
BA_ "GenSigStartValue" SG_ 2498842916 TransferCaseOrSplitboxPTOMode_IS 3;
BA_ "Platform_VMCU1_Sig" SG_ 2498842916 TransferCaseOrSplitboxPTOMode_IS 1;
BA_ "SeToolAncestorID_SIGNAL" SG_ 2498842916 TransferCaseOrSplitboxPTOMode_IS "x0000001D0419DC89";
BA_ "SeToolItemID_SIGNAL" SG_ 2498842916 TransferCaseOrSplitboxPTOMode_IS "x0000001D0419DC89";
BA_ "SeToolName_SIGNAL" SG_ 2498842916 TransferCaseOrSplitboxPTOMode_IS "SplitBoxPtoStatus";
BA_ "SeToolVersion_SIGNAL" SG_ 2498842916 TransferCaseOrSplitboxPTOMode_IS "1";
BA_ "SystemSignalLongSymbol" SG_ 2498842916 TransferCaseOrSplitboxPTOMode_IS "TransferCaseOrSplitboxPTOMode_ISig_4";
BA_ "GenSigCycleTime" SG_ 2498842916 FrontWheelDriveMenuFeedback 100;
BA_ "GenSigCycleTimeActive" SG_ 2498842916 FrontWheelDriveMenuFeedback 100;
BA_ "GenSigStartValue" SG_ 2498842916 FrontWheelDriveMenuFeedback 3;
BA_ "Platform_VMCU1_Sig" SG_ 2498842916 FrontWheelDriveMenuFeedback 1;
BA_ "GenSigCycleTime" SG_ 2498842916 DirIndRearLamp_Stat_ISig_4 100;
BA_ "GenSigCycleTimeActive" SG_ 2498842916 DirIndRearLamp_Stat_ISig_4 100;
BA_ "GenSigStartValue" SG_ 2498842916 DirIndRearLamp_Stat_ISig_4 7;
BA_ "Platform_VMCU1_Sig" SG_ 2498842916 DirIndRearLamp_Stat_ISig_4 1;
BA_ "GenSigCycleTime" SG_ 2498842916 Pto1Status_ISig_4 100;
BA_ "GenSigCycleTimeActive" SG_ 2498842916 Pto1Status_ISig_4 100;
BA_ "GenSigStartValue" SG_ 2498842916 Pto1Status_ISig_4 3;
BA_ "GenSigMaxLatency" SG_ 2498842916 Pto1Status_ISig_4 110;
BA_ "Platform_VMCU1_Sig" SG_ 2498842916 Pto1Status_ISig_4 1;
BA_ "SeToolAncestorID_SIGNAL" SG_ 2498842916 Pto1Status_ISig_4 "x0000001D041534A3";
BA_ "SeToolItemID_SIGNAL" SG_ 2498842916 Pto1Status_ISig_4 "x0000001D04320FF9";
BA_ "SeToolName_SIGNAL" SG_ 2498842916 Pto1Status_ISig_4 "Pto1Status";
BA_ "SeToolVersion_SIGNAL" SG_ 2498842916 Pto1Status_ISig_4 "3";
BA_ "GenSigCycleTime" SG_ 2498842916 Pto3DrivingRequest 100;
BA_ "GenSigCycleTimeActive" SG_ 2498842916 Pto3DrivingRequest 100;
BA_ "GenSigStartValue" SG_ 2498842916 Pto3DrivingRequest 3;
BA_ "GenSigMaxLatency" SG_ 2498842916 Pto3DrivingRequest 110;
BA_ "Platform_VMCU1_Sig" SG_ 2498842916 Pto3DrivingRequest 1;
BA_ "SeToolAncestorID_SIGNAL" SG_ 2498842916 Pto3DrivingRequest "x0000001D041538FC";
BA_ "SeToolItemID_SIGNAL" SG_ 2498842916 Pto3DrivingRequest "x0000001D041538FC";
BA_ "SeToolName_SIGNAL" SG_ 2498842916 Pto3DrivingRequest "Pto3DrivingRequest";
BA_ "SeToolVersion_SIGNAL" SG_ 2498842916 Pto3DrivingRequest "1";
BA_ "GenSigCycleTime" SG_ 2466224932 CCBTargetSpeedRequest 100;
BA_ "GenSigCycleTimeActive" SG_ 2466224932 CCBTargetSpeedRequest 100;
BA_ "GenSigStartValue" SG_ 2466224932 CCBTargetSpeedRequest 65535;
BA_ "GenSigMaxLatency" SG_ 2466224932 CCBTargetSpeedRequest 57;
BA_ "Platform_VMCU1_Sig" SG_ 2466224932 CCBTargetSpeedRequest 1;
BA_ "SeToolAncestorID_SIGNAL" SG_ 2466224932 CCBTargetSpeedRequest "x0000001D043FE028";
BA_ "SeToolItemID_SIGNAL" SG_ 2466224932 CCBTargetSpeedRequest "x0000001D043FE028";
BA_ "SeToolName_SIGNAL" SG_ 2466224932 CCBTargetSpeedRequest "CCBTargetSpeedRequest";
BA_ "SeToolVersion_SIGNAL" SG_ 2466224932 CCBTargetSpeedRequest "1";
BA_ "GenSigCycleTime" SG_ 2466224932 EngineStartControlStatus_ISig_4 100;
BA_ "GenSigCycleTimeActive" SG_ 2466224932 EngineStartControlStatus_ISig_4 100;
BA_ "GenSigStartValue" SG_ 2466224932 EngineStartControlStatus_ISig_4 65535;
BA_ "GenSigMaxLatency" SG_ 2466224932 EngineStartControlStatus_ISig_4 57;
BA_ "Platform_VMCU1_Sig" SG_ 2466224932 EngineStartControlStatus_ISig_4 1;
BA_ "SeToolAncestorID_SIGNAL" SG_ 2466224932 EngineStartControlStatus_ISig_4 "x0000001D041E8EE9";
BA_ "SeToolItemID_SIGNAL" SG_ 2466224932 EngineStartControlStatus_ISig_4 "x0000001D0425C909";
BA_ "SeToolName_SIGNAL" SG_ 2466224932 EngineStartControlStatus_ISig_4 "EngineStartControlStatus";
BA_ "SeToolVersion_SIGNAL" SG_ 2466224932 EngineStartControlStatus_ISig_4 "3";
BA_ "GenSigCycleTime" SG_ 2466224932 CCTargetSpeedRequest 100;
BA_ "GenSigCycleTimeActive" SG_ 2466224932 CCTargetSpeedRequest 100;
BA_ "GenSigStartValue" SG_ 2466224932 CCTargetSpeedRequest 65535;
BA_ "GenSigMaxLatency" SG_ 2466224932 CCTargetSpeedRequest 57;
BA_ "Platform_VMCU1_Sig" SG_ 2466224932 CCTargetSpeedRequest 1;
BA_ "SeToolAncestorID_SIGNAL" SG_ 2466224932 CCTargetSpeedRequest "x0000001D043FE024";
BA_ "SeToolItemID_SIGNAL" SG_ 2466224932 CCTargetSpeedRequest "x0000001D043FE024";
BA_ "SeToolName_SIGNAL" SG_ 2466224932 CCTargetSpeedRequest "CCTargetSpeedRequest";
BA_ "SeToolVersion_SIGNAL" SG_ 2466224932 CCTargetSpeedRequest "1";
BA_ "GenSigCycleTime" SG_ 2466210596 StoreIdleValue_ISig_4 100;
BA_ "GenSigCycleTimeActive" SG_ 2466210596 StoreIdleValue_ISig_4 100;
BA_ "GenSigStartValue" SG_ 2466210596 StoreIdleValue_ISig_4 3;
BA_ "Platform_VMCU1_Sig" SG_ 2466210596 StoreIdleValue_ISig_4 1;
BA_ "GenSigCycleTime" SG_ 2466210596 EngSpdCtrlBadConditions_ISig_4 100;
BA_ "GenSigCycleTimeActive" SG_ 2466210596 EngSpdCtrlBadConditions_ISig_4 100;
BA_ "GenSigStartValue" SG_ 2466210596 EngSpdCtrlBadConditions_ISig_4 31;
BA_ "GenSigMaxLatency" SG_ 2466210596 EngSpdCtrlBadConditions_ISig_4 56;
BA_ "Platform_VMCU1_Sig" SG_ 2466210596 EngSpdCtrlBadConditions_ISig_4 1;
BA_ "SeToolAncestorID_SIGNAL" SG_ 2466210596 EngSpdCtrlBadConditions_ISig_4 "x0000001D043DD2B6";
BA_ "SeToolItemID_SIGNAL" SG_ 2466210596 EngSpdCtrlBadConditions_ISig_4 "x0000001D043DD2B6";
BA_ "SeToolName_SIGNAL" SG_ 2466210596 EngSpdCtrlBadConditions_ISig_4 "EngSpdCtrlBadConditions";
BA_ "SeToolVersion_SIGNAL" SG_ 2466210596 EngSpdCtrlBadConditions_ISig_4 "1";
BA_ "GenSigSendType" SG_ 2466210596 TrailerConnected_UB_ISig_4 7;
BA_ "Platform_VMCU1_Sig" SG_ 2466210596 TrailerConnected_UB_ISig_4 1;
BA_ "GenSigCycleTime" SG_ 2466210596 CrossCountryBadConditions 100;
BA_ "GenSigCycleTimeActive" SG_ 2466210596 CrossCountryBadConditions 100;
BA_ "GenSigStartValue" SG_ 2466210596 CrossCountryBadConditions 31;
BA_ "GenSigMaxLatency" SG_ 2466210596 CrossCountryBadConditions 56;
BA_ "Platform_VMCU1_Sig" SG_ 2466210596 CrossCountryBadConditions 1;
BA_ "SeToolAncestorID_SIGNAL" SG_ 2466210596 CrossCountryBadConditions "x0000001D043DD2B6";
BA_ "SeToolItemID_SIGNAL" SG_ 2466210596 CrossCountryBadConditions "x0000001D043DD2B6";
BA_ "SeToolName_SIGNAL" SG_ 2466210596 CrossCountryBadConditions "CrossCountryBadConditions";
BA_ "SeToolVersion_SIGNAL" SG_ 2466210596 CrossCountryBadConditions "1";
BA_ "GenSigCycleTime" SG_ 2466210596 ESCReqEMS_CtrlTrimMode_ISig_4 100;
BA_ "GenSigCycleTimeActive" SG_ 2466210596 ESCReqEMS_CtrlTrimMode_ISig_4 100;
BA_ "GenSigStartValue" SG_ 2466210596 ESCReqEMS_CtrlTrimMode_ISig_4 15;
BA_ "GenSigMaxLatency" SG_ 2466210596 ESCReqEMS_CtrlTrimMode_ISig_4 56;
BA_ "Platform_VMCU1_Sig" SG_ 2466210596 ESCReqEMS_CtrlTrimMode_ISig_4 1;
BA_ "SeToolAncestorID_SIGNAL" SG_ 2466210596 ESCReqEMS_CtrlTrimMode_ISig_4 "x0000001D042A710F";
BA_ "SeToolItemID_SIGNAL" SG_ 2466210596 ESCReqEMS_CtrlTrimMode_ISig_4 "x0000001D042A710F";
BA_ "SeToolName_SIGNAL" SG_ 2466210596 ESCReqEMS_CtrlTrimMode_ISig_4 "CtrlTrimMode";
BA_ "SeToolOwnerSigGroupID_SIGNAL" SG_ 2466210596 ESCReqEMS_CtrlTrimMode_ISig_4 "x0000001D043D5DDC";
BA_ "SeToolOwnerSigGroup_SIGNAL" SG_ 2466210596 ESCReqEMS_CtrlTrimMode_ISig_4 "ESCReqEMS";
BA_ "SeToolVersion_SIGNAL" SG_ 2466210596 ESCReqEMS_CtrlTrimMode_ISig_4 "1";
BA_ "GenSigCycleTime" SG_ 2466210596 ESCReqESC_CtrlTrimMode_ISig_4 100;
BA_ "GenSigCycleTimeActive" SG_ 2466210596 ESCReqESC_CtrlTrimMode_ISig_4 100;
BA_ "GenSigStartValue" SG_ 2466210596 ESCReqESC_CtrlTrimMode_ISig_4 15;
BA_ "GenSigMaxLatency" SG_ 2466210596 ESCReqESC_CtrlTrimMode_ISig_4 56;
BA_ "Platform_VMCU1_Sig" SG_ 2466210596 ESCReqESC_CtrlTrimMode_ISig_4 1;
BA_ "SeToolAncestorID_SIGNAL" SG_ 2466210596 ESCReqESC_CtrlTrimMode_ISig_4 "x0000001D042A710F";
BA_ "SeToolItemID_SIGNAL" SG_ 2466210596 ESCReqESC_CtrlTrimMode_ISig_4 "x0000001D042A710F";
BA_ "SeToolName_SIGNAL" SG_ 2466210596 ESCReqESC_CtrlTrimMode_ISig_4 "CtrlTrimMode";
BA_ "SeToolOwnerSigGroupID_SIGNAL" SG_ 2466210596 ESCReqESC_CtrlTrimMode_ISig_4 "x0000001D043D5DD2";
BA_ "SeToolOwnerSigGroup_SIGNAL" SG_ 2466210596 ESCReqESC_CtrlTrimMode_ISig_4 "ESCReqESC";
BA_ "SeToolVersion_SIGNAL" SG_ 2466210596 ESCReqESC_CtrlTrimMode_ISig_4 "1";
BA_ "GenSigCycleTime" SG_ 2466210596 IdleAdjustConditionStatus 100;
BA_ "GenSigCycleTimeActive" SG_ 2466210596 IdleAdjustConditionStatus 100;
BA_ "GenSigStartValue" SG_ 2466210596 IdleAdjustConditionStatus 3;
BA_ "Platform_VMCU1_Sig" SG_ 2466210596 IdleAdjustConditionStatus 1;
BA_ "GenSigCycleTime" SG_ 2466210596 StopProhibitStatus_ISig_4 100;
BA_ "GenSigCycleTimeActive" SG_ 2466210596 StopProhibitStatus_ISig_4 100;
BA_ "GenSigStartValue" SG_ 2466210596 StopProhibitStatus_ISig_4 3;
BA_ "Platform_VMCU1_Sig" SG_ 2466210596 StopProhibitStatus_ISig_4 1;
BA_ "GenSigCycleTime" SG_ 2466210596 ESCReqEMS_CtrlTrimStat_ISig_4 100;
BA_ "GenSigCycleTimeActive" SG_ 2466210596 ESCReqEMS_CtrlTrimStat_ISig_4 100;
BA_ "GenSigStartValue" SG_ 2466210596 ESCReqEMS_CtrlTrimStat_ISig_4 7;
BA_ "GenSigMaxLatency" SG_ 2466210596 ESCReqEMS_CtrlTrimStat_ISig_4 56;
BA_ "Platform_VMCU1_Sig" SG_ 2466210596 ESCReqEMS_CtrlTrimStat_ISig_4 1;
BA_ "SeToolAncestorID_SIGNAL" SG_ 2466210596 ESCReqEMS_CtrlTrimStat_ISig_4 "x0000001D042A710D";
BA_ "SeToolItemID_SIGNAL" SG_ 2466210596 ESCReqEMS_CtrlTrimStat_ISig_4 "x0000001D042A710D";
BA_ "SeToolName_SIGNAL" SG_ 2466210596 ESCReqEMS_CtrlTrimStat_ISig_4 "CtrlTrimStat";
BA_ "SeToolOwnerSigGroupID_SIGNAL" SG_ 2466210596 ESCReqEMS_CtrlTrimStat_ISig_4 "x0000001D043D5DDC";
BA_ "SeToolOwnerSigGroup_SIGNAL" SG_ 2466210596 ESCReqEMS_CtrlTrimStat_ISig_4 "ESCReqEMS";
BA_ "SeToolVersion_SIGNAL" SG_ 2466210596 ESCReqEMS_CtrlTrimStat_ISig_4 "1";
BA_ "GenSigCycleTime" SG_ 2466210596 TrailerConnected_ISig_4 100;
BA_ "GenSigCycleTimeActive" SG_ 2466210596 TrailerConnected_ISig_4 100;
BA_ "GenSigStartValue" SG_ 2466210596 TrailerConnected_ISig_4 3;
BA_ "NeedsUpdateBit" SG_ 2466210596 TrailerConnected_ISig_4 1;
BA_ "Platform_VMCU1_Sig" SG_ 2466210596 TrailerConnected_ISig_4 1;
BA_ "GenSigCycleTime" SG_ 2466210596 ESCReqESC_CtrlTrimValue_ISig_4 100;
BA_ "GenSigCycleTimeActive" SG_ 2466210596 ESCReqESC_CtrlTrimValue_ISig_4 100;
BA_ "GenSigStartValue" SG_ 2466210596 ESCReqESC_CtrlTrimValue_ISig_4 255;
BA_ "GenSigMaxLatency" SG_ 2466210596 ESCReqESC_CtrlTrimValue_ISig_4 56;
BA_ "Platform_VMCU1_Sig" SG_ 2466210596 ESCReqESC_CtrlTrimValue_ISig_4 1;
BA_ "SeToolAncestorID_SIGNAL" SG_ 2466210596 ESCReqESC_CtrlTrimValue_ISig_4 "x0000001D042A7114";
BA_ "SeToolItemID_SIGNAL" SG_ 2466210596 ESCReqESC_CtrlTrimValue_ISig_4 "x0000001D042A7114";
BA_ "SeToolName_SIGNAL" SG_ 2466210596 ESCReqESC_CtrlTrimValue_ISig_4 "CtrlTrimValue";
BA_ "SeToolOwnerSigGroupID_SIGNAL" SG_ 2466210596 ESCReqESC_CtrlTrimValue_ISig_4 "x0000001D043D5DD2";
BA_ "SeToolOwnerSigGroup_SIGNAL" SG_ 2466210596 ESCReqESC_CtrlTrimValue_ISig_4 "ESCReqESC";
BA_ "SeToolVersion_SIGNAL" SG_ 2466210596 ESCReqESC_CtrlTrimValue_ISig_4 "1";
BA_ "GenSigSendType" SG_ 2466210596 BrakeLight_rqst_UB_ISig_4 7;
BA_ "Platform_VMCU1_Sig" SG_ 2466210596 BrakeLight_rqst_UB_ISig_4 1;
BA_ "GenSigCycleTime" SG_ 2466210596 ESCReqESC_CtrlTrimStat_ISig_4 100;
BA_ "GenSigCycleTimeActive" SG_ 2466210596 ESCReqESC_CtrlTrimStat_ISig_4 100;
BA_ "GenSigStartValue" SG_ 2466210596 ESCReqESC_CtrlTrimStat_ISig_4 7;
BA_ "GenSigMaxLatency" SG_ 2466210596 ESCReqESC_CtrlTrimStat_ISig_4 56;
BA_ "Platform_VMCU1_Sig" SG_ 2466210596 ESCReqESC_CtrlTrimStat_ISig_4 1;
BA_ "SeToolAncestorID_SIGNAL" SG_ 2466210596 ESCReqESC_CtrlTrimStat_ISig_4 "x0000001D042A710D";
BA_ "SeToolItemID_SIGNAL" SG_ 2466210596 ESCReqESC_CtrlTrimStat_ISig_4 "x0000001D042A710D";
BA_ "SeToolName_SIGNAL" SG_ 2466210596 ESCReqESC_CtrlTrimStat_ISig_4 "CtrlTrimStat";
BA_ "SeToolOwnerSigGroupID_SIGNAL" SG_ 2466210596 ESCReqESC_CtrlTrimStat_ISig_4 "x0000001D043D5DD2";
BA_ "SeToolOwnerSigGroup_SIGNAL" SG_ 2466210596 ESCReqESC_CtrlTrimStat_ISig_4 "ESCReqESC";
BA_ "SeToolVersion_SIGNAL" SG_ 2466210596 ESCReqESC_CtrlTrimStat_ISig_4 "1";
BA_ "GenSigCycleTime" SG_ 2466210596 SCLLogicEnable_rqst 100;
BA_ "GenSigCycleTimeActive" SG_ 2466210596 SCLLogicEnable_rqst 100;
BA_ "GenSigStartValue" SG_ 2466210596 SCLLogicEnable_rqst 7;
BA_ "GenSigMaxLatency" SG_ 2466210596 SCLLogicEnable_rqst 55;
BA_ "Platform_VMCU1_Sig" SG_ 2466210596 SCLLogicEnable_rqst 1;
BA_ "SeToolAncestorID_SIGNAL" SG_ 2466210596 SCLLogicEnable_rqst "x0000001D043B4FEF";
BA_ "SeToolItemID_SIGNAL" SG_ 2466210596 SCLLogicEnable_rqst "x0000001D043FB671";
BA_ "SeToolName_SIGNAL" SG_ 2466210596 SCLLogicEnable_rqst "SCLLogicEnable_rqst";
BA_ "SeToolVersion_SIGNAL" SG_ 2466210596 SCLLogicEnable_rqst "2";
BA_ "GenSigCycleTime" SG_ 2466210596 ESCReqESC_CtrlTrimReq_ISig_4 100;
BA_ "GenSigCycleTimeActive" SG_ 2466210596 ESCReqESC_CtrlTrimReq_ISig_4 100;
BA_ "GenSigStartValue" SG_ 2466210596 ESCReqESC_CtrlTrimReq_ISig_4 7;
BA_ "GenSigMaxLatency" SG_ 2466210596 ESCReqESC_CtrlTrimReq_ISig_4 56;
BA_ "Platform_VMCU1_Sig" SG_ 2466210596 ESCReqESC_CtrlTrimReq_ISig_4 1;
BA_ "SeToolAncestorID_SIGNAL" SG_ 2466210596 ESCReqESC_CtrlTrimReq_ISig_4 "x0000001D042A710B";
BA_ "SeToolItemID_SIGNAL" SG_ 2466210596 ESCReqESC_CtrlTrimReq_ISig_4 "x0000001D042A710B";
BA_ "SeToolName_SIGNAL" SG_ 2466210596 ESCReqESC_CtrlTrimReq_ISig_4 "CtrlTrimReq";
BA_ "SeToolOwnerSigGroupID_SIGNAL" SG_ 2466210596 ESCReqESC_CtrlTrimReq_ISig_4 "x0000001D043D5DD2";
BA_ "SeToolOwnerSigGroup_SIGNAL" SG_ 2466210596 ESCReqESC_CtrlTrimReq_ISig_4 "ESCReqESC";
BA_ "SeToolVersion_SIGNAL" SG_ 2466210596 ESCReqESC_CtrlTrimReq_ISig_4 "1";
BA_ "GenSigCycleTime" SG_ 2466210596 BrakeLight_rqst_ISig_4 100;
BA_ "GenSigCycleTimeActive" SG_ 2466210596 BrakeLight_rqst_ISig_4 100;
BA_ "GenSigStartValue" SG_ 2466210596 BrakeLight_rqst_ISig_4 7;
BA_ "NeedsUpdateBit" SG_ 2466210596 BrakeLight_rqst_ISig_4 1;
BA_ "Platform_VMCU1_Sig" SG_ 2466210596 BrakeLight_rqst_ISig_4 1;
BA_ "GenSigCycleTime" SG_ 2466210596 ESCReqEMS_CtrlTrimValue_ISig_4 100;
BA_ "GenSigCycleTimeActive" SG_ 2466210596 ESCReqEMS_CtrlTrimValue_ISig_4 100;
BA_ "GenSigStartValue" SG_ 2466210596 ESCReqEMS_CtrlTrimValue_ISig_4 255;
BA_ "GenSigMaxLatency" SG_ 2466210596 ESCReqEMS_CtrlTrimValue_ISig_4 56;
BA_ "Platform_VMCU1_Sig" SG_ 2466210596 ESCReqEMS_CtrlTrimValue_ISig_4 1;
BA_ "SeToolAncestorID_SIGNAL" SG_ 2466210596 ESCReqEMS_CtrlTrimValue_ISig_4 "x0000001D042A7114";
BA_ "SeToolItemID_SIGNAL" SG_ 2466210596 ESCReqEMS_CtrlTrimValue_ISig_4 "x0000001D042A7114";
BA_ "SeToolName_SIGNAL" SG_ 2466210596 ESCReqEMS_CtrlTrimValue_ISig_4 "CtrlTrimValue";
BA_ "SeToolOwnerSigGroupID_SIGNAL" SG_ 2466210596 ESCReqEMS_CtrlTrimValue_ISig_4 "x0000001D043D5DDC";
BA_ "SeToolOwnerSigGroup_SIGNAL" SG_ 2466210596 ESCReqEMS_CtrlTrimValue_ISig_4 "ESCReqEMS";
BA_ "SeToolVersion_SIGNAL" SG_ 2466210596 ESCReqEMS_CtrlTrimValue_ISig_4 "1";
BA_ "GenSigCycleTime" SG_ 2466210596 ESCReqEMS_CtrlTrimReq_ISig_4 100;
BA_ "GenSigCycleTimeActive" SG_ 2466210596 ESCReqEMS_CtrlTrimReq_ISig_4 100;
BA_ "GenSigStartValue" SG_ 2466210596 ESCReqEMS_CtrlTrimReq_ISig_4 7;
BA_ "GenSigMaxLatency" SG_ 2466210596 ESCReqEMS_CtrlTrimReq_ISig_4 56;
BA_ "Platform_VMCU1_Sig" SG_ 2466210596 ESCReqEMS_CtrlTrimReq_ISig_4 1;
BA_ "SeToolAncestorID_SIGNAL" SG_ 2466210596 ESCReqEMS_CtrlTrimReq_ISig_4 "x0000001D042A710B";
BA_ "SeToolItemID_SIGNAL" SG_ 2466210596 ESCReqEMS_CtrlTrimReq_ISig_4 "x0000001D042A710B";
BA_ "SeToolName_SIGNAL" SG_ 2466210596 ESCReqEMS_CtrlTrimReq_ISig_4 "CtrlTrimReq";
BA_ "SeToolOwnerSigGroupID_SIGNAL" SG_ 2466210596 ESCReqEMS_CtrlTrimReq_ISig_4 "x0000001D043D5DDC";
BA_ "SeToolOwnerSigGroup_SIGNAL" SG_ 2466210596 ESCReqEMS_CtrlTrimReq_ISig_4 "ESCReqEMS";
BA_ "SeToolVersion_SIGNAL" SG_ 2466210596 ESCReqEMS_CtrlTrimReq_ISig_4 "1";
BA_ "GenSigSendType" SG_ 2466196004 WiperParkStatus_Global_UB_ISig_4 7;
BA_ "Platform_VMCU1_Sig" SG_ 2466196004 WiperParkStatus_Global_UB_ISig_4 1;
BA_ "GenSigCycleTime" SG_ 2466196004 TrailerTest_stat 100;
BA_ "GenSigCycleTimeActive" SG_ 2466196004 TrailerTest_stat 100;
BA_ "GenSigStartValue" SG_ 2466196004 TrailerTest_stat 7;
BA_ "GenSigMaxLatency" SG_ 2466196004 TrailerTest_stat 55;
BA_ "Platform_VMCU1_Sig" SG_ 2466196004 TrailerTest_stat 1;
BA_ "SeToolAncestorID_SIGNAL" SG_ 2466196004 TrailerTest_stat "x0000001D042E1ADE";
BA_ "SeToolItemID_SIGNAL" SG_ 2466196004 TrailerTest_stat "x0000001D042E1ADE";
BA_ "SeToolName_SIGNAL" SG_ 2466196004 TrailerTest_stat "TrailerTest_stat";
BA_ "SeToolVersion_SIGNAL" SG_ 2466196004 TrailerTest_stat "1";
BA_ "GenSigCycleTime" SG_ 2466196004 Washing_HMI_rqst_ISig_4 100;
BA_ "GenSigCycleTimeActive" SG_ 2466196004 Washing_HMI_rqst_ISig_4 100;
BA_ "GenSigStartValue" SG_ 2466196004 Washing_HMI_rqst_ISig_4 3;
BA_ "Platform_VMCU1_Sig" SG_ 2466196004 Washing_HMI_rqst_ISig_4 1;
BA_ "GenSigCycleTime" SG_ 2466196004 AuxBrakesDwngrdModeInd_rqst_ISig 100;
BA_ "GenSigCycleTimeActive" SG_ 2466196004 AuxBrakesDwngrdModeInd_rqst_ISig 100;
BA_ "GenSigStartValue" SG_ 2466196004 AuxBrakesDwngrdModeInd_rqst_ISig 7;
BA_ "GenSigMaxLatency" SG_ 2466196004 AuxBrakesDwngrdModeInd_rqst_ISig 55;
BA_ "Platform_VMCU1_Sig" SG_ 2466196004 AuxBrakesDwngrdModeInd_rqst_ISig 1;
BA_ "SeToolAncestorID_SIGNAL" SG_ 2466196004 AuxBrakesDwngrdModeInd_rqst_ISig "x0000001D0414CED7";
BA_ "SeToolItemID_SIGNAL" SG_ 2466196004 AuxBrakesDwngrdModeInd_rqst_ISig "x0000001D04327A04";
BA_ "SeToolName_SIGNAL" SG_ 2466196004 AuxBrakesDwngrdModeInd_rqst_ISig "AuxBrakesDowngradedModeIndicationReq";
BA_ "SeToolVersion_SIGNAL" SG_ 2466196004 AuxBrakesDwngrdModeInd_rqst_ISig "2";
BA_ "SystemSignalLongSymbol" SG_ 2466196004 AuxBrakesDwngrdModeInd_rqst_ISig "AuxBrakesDwngrdModeInd_rqst_ISig_4";
BA_ "GenSigCycleTime" SG_ 2466196004 XRSLTargetSpeedRequest 100;
BA_ "GenSigCycleTimeActive" SG_ 2466196004 XRSLTargetSpeedRequest 100;
BA_ "GenSigStartValue" SG_ 2466196004 XRSLTargetSpeedRequest 65535;
BA_ "Platform_VMCU1_Sig" SG_ 2466196004 XRSLTargetSpeedRequest 1;
BA_ "GenSigCycleTime" SG_ 2466196004 XPRsystemstate_ISig_4 100;
BA_ "GenSigCycleTimeActive" SG_ 2466196004 XPRsystemstate_ISig_4 100;
BA_ "GenSigStartValue" SG_ 2466196004 XPRsystemstate_ISig_4 255;
BA_ "Platform_VMCU1_Sig" SG_ 2466196004 XPRsystemstate_ISig_4 1;
BA_ "GenSigCycleTime" SG_ 2466196004 KeyAuthentication_rqst 100;
BA_ "GenSigCycleTimeActive" SG_ 2466196004 KeyAuthentication_rqst 100;
BA_ "GenSigStartValue" SG_ 2466196004 KeyAuthentication_rqst 7;
BA_ "Platform_VMCU1_Sig" SG_ 2466196004 KeyAuthentication_rqst 1;
BA_ "GenSigCycleTime" SG_ 2466196004 EngineSpeedControlStatus_ISig_4 100;
BA_ "GenSigCycleTimeActive" SG_ 2466196004 EngineSpeedControlStatus_ISig_4 100;
BA_ "GenSigStartValue" SG_ 2466196004 EngineSpeedControlStatus_ISig_4 7;
BA_ "GenSigMaxLatency" SG_ 2466196004 EngineSpeedControlStatus_ISig_4 55;
BA_ "Platform_VMCU1_Sig" SG_ 2466196004 EngineSpeedControlStatus_ISig_4 1;
BA_ "SeToolAncestorID_SIGNAL" SG_ 2466196004 EngineSpeedControlStatus_ISig_4 "x0000001D04154AB5";
BA_ "SeToolItemID_SIGNAL" SG_ 2466196004 EngineSpeedControlStatus_ISig_4 "x0000001D043DFB57";
BA_ "SeToolName_SIGNAL" SG_ 2466196004 EngineSpeedControlStatus_ISig_4 "EngineSpeedControlStatus";
BA_ "SeToolVersion_SIGNAL" SG_ 2466196004 EngineSpeedControlStatus_ISig_4 "2";
BA_ "GenSigCycleTime" SG_ 2466196004 EngineSpeedLimitReached 100;
BA_ "GenSigCycleTimeActive" SG_ 2466196004 EngineSpeedLimitReached 100;
BA_ "GenSigStartValue" SG_ 2466196004 EngineSpeedLimitReached 7;
BA_ "GenSigMaxLatency" SG_ 2466196004 EngineSpeedLimitReached 55;
BA_ "Platform_VMCU1_Sig" SG_ 2466196004 EngineSpeedLimitReached 1;
BA_ "SeToolAncestorID_SIGNAL" SG_ 2466196004 EngineSpeedLimitReached "x0000001D043DDB43";
BA_ "SeToolItemID_SIGNAL" SG_ 2466196004 EngineSpeedLimitReached "x0000001D043DDB43";
BA_ "SeToolName_SIGNAL" SG_ 2466196004 EngineSpeedLimitReached "EngineSpeedLimitReached";
BA_ "SeToolVersion_SIGNAL" SG_ 2466196004 EngineSpeedLimitReached "1";
BA_ "GenSigCycleTime" SG_ 2466196004 SecondThrottle 100;
BA_ "GenSigCycleTimeActive" SG_ 2466196004 SecondThrottle 100;
BA_ "GenSigStartValue" SG_ 2466196004 SecondThrottle 3;
BA_ "GenSigMaxLatency" SG_ 2466196004 SecondThrottle 55;
BA_ "Platform_VMCU1_Sig" SG_ 2466196004 SecondThrottle 1;
BA_ "SeToolAncestorID_SIGNAL" SG_ 2466196004 SecondThrottle "x0000001D0425A500";
BA_ "SeToolItemID_SIGNAL" SG_ 2466196004 SecondThrottle "x0000001D0425A500";
BA_ "SeToolName_SIGNAL" SG_ 2466196004 SecondThrottle "SecondThrottle";
BA_ "SeToolVersion_SIGNAL" SG_ 2466196004 SecondThrottle "1";
BA_ "GenSigCycleTime" SG_ 2466196004 PredeliveryModeIndication_cmd_IS 100;
BA_ "GenSigCycleTimeActive" SG_ 2466196004 PredeliveryModeIndication_cmd_IS 100;
BA_ "GenSigStartValue" SG_ 2466196004 PredeliveryModeIndication_cmd_IS 3;
BA_ "Platform_VMCU1_Sig" SG_ 2466196004 PredeliveryModeIndication_cmd_IS 1;
BA_ "SystemSignalLongSymbol" SG_ 2466196004 PredeliveryModeIndication_cmd_IS "PredeliveryModeIndication_cmd_ISig_4";
BA_ "GenSigCycleTime" SG_ 2466196004 LoadCutOffIndication_cmd_ISig_4 100;
BA_ "GenSigCycleTimeActive" SG_ 2466196004 LoadCutOffIndication_cmd_ISig_4 100;
BA_ "GenSigStartValue" SG_ 2466196004 LoadCutOffIndication_cmd_ISig_4 3;
BA_ "Platform_VMCU1_Sig" SG_ 2466196004 LoadCutOffIndication_cmd_ISig_4 1;
BA_ "GenSigCycleTime" SG_ 2466196004 AutoPBRelease_stat_ISig_4 100;
BA_ "GenSigCycleTimeActive" SG_ 2466196004 AutoPBRelease_stat_ISig_4 100;
BA_ "GenSigStartValue" SG_ 2466196004 AutoPBRelease_stat_ISig_4 3;
BA_ "GenSigMaxLatency" SG_ 2466196004 AutoPBRelease_stat_ISig_4 55;
BA_ "Platform_VMCU1_Sig" SG_ 2466196004 AutoPBRelease_stat_ISig_4 1;
BA_ "SeToolAncestorID_SIGNAL" SG_ 2466196004 AutoPBRelease_stat_ISig_4 "x0000001D042E42B1";
BA_ "SeToolItemID_SIGNAL" SG_ 2466196004 AutoPBRelease_stat_ISig_4 "x0000001D042E42B1";
BA_ "SeToolName_SIGNAL" SG_ 2466196004 AutoPBRelease_stat_ISig_4 "AutoPBRelease_stat";
BA_ "SeToolVersion_SIGNAL" SG_ 2466196004 AutoPBRelease_stat_ISig_4 "1";
BA_ "GenSigCycleTime" SG_ 2466196004 AutoParkBrakeActvnInhibd_stat_IS 100;
BA_ "GenSigCycleTimeActive" SG_ 2466196004 AutoParkBrakeActvnInhibd_stat_IS 100;
BA_ "GenSigStartValue" SG_ 2466196004 AutoParkBrakeActvnInhibd_stat_IS 3;
BA_ "GenSigMaxLatency" SG_ 2466196004 AutoParkBrakeActvnInhibd_stat_IS 55;
BA_ "Platform_VMCU1_Sig" SG_ 2466196004 AutoParkBrakeActvnInhibd_stat_IS 1;
BA_ "SeToolAncestorID_SIGNAL" SG_ 2466196004 AutoParkBrakeActvnInhibd_stat_IS "x0000001D042173BA";
BA_ "SeToolItemID_SIGNAL" SG_ 2466196004 AutoParkBrakeActvnInhibd_stat_IS "x0000001D0421DA80";
BA_ "SeToolName_SIGNAL" SG_ 2466196004 AutoParkBrakeActvnInhibd_stat_IS "AutomaticParkingBrakeActuationInhibited_stat";
BA_ "SeToolVersion_SIGNAL" SG_ 2466196004 AutoParkBrakeActvnInhibd_stat_IS "2";
BA_ "SystemSignalLongSymbol" SG_ 2466196004 AutoParkBrakeActvnInhibd_stat_IS "AutoParkBrakeActvnInhibd_stat_ISig_4";
BA_ "GenSigCycleTime" SG_ 2466196004 WiperParkStatus_Global_ISig_4 100;
BA_ "GenSigCycleTimeActive" SG_ 2466196004 WiperParkStatus_Global_ISig_4 100;
BA_ "GenSigStartValue" SG_ 2466196004 WiperParkStatus_Global_ISig_4 3;
BA_ "GenSigMaxLatency" SG_ 2466196004 WiperParkStatus_Global_ISig_4 55;
BA_ "NeedsUpdateBit" SG_ 2466196004 WiperParkStatus_Global_ISig_4 1;
BA_ "Platform_VMCU1_Sig" SG_ 2466196004 WiperParkStatus_Global_ISig_4 1;
BA_ "SeToolAncestorID_SIGNAL" SG_ 2466196004 WiperParkStatus_Global_ISig_4 "x0000001D04389505";
BA_ "SeToolItemID_SIGNAL" SG_ 2466196004 WiperParkStatus_Global_ISig_4 "x0000001D04389505";
BA_ "SeToolName_SIGNAL" SG_ 2466196004 WiperParkStatus_Global_ISig_4 "WiperParkStatus_Global";
BA_ "SeToolVersion_SIGNAL" SG_ 2466196004 WiperParkStatus_Global_ISig_4 "1";
BA_ "GenSigCycleTime" SG_ 2466196004 ExitPreDeliveryModeHMI_rqst_ISig 100;
BA_ "GenSigCycleTimeActive" SG_ 2466196004 ExitPreDeliveryModeHMI_rqst_ISig 100;
BA_ "GenSigStartValue" SG_ 2466196004 ExitPreDeliveryModeHMI_rqst_ISig 3;
BA_ "Platform_VMCU1_Sig" SG_ 2466196004 ExitPreDeliveryModeHMI_rqst_ISig 1;
BA_ "SystemSignalLongSymbol" SG_ 2466196004 ExitPreDeliveryModeHMI_rqst_ISig "ExitPreDeliveryModeHMI_rqst_ISig_4";
BA_ "GenSigCycleTime" SG_ 2466196004 FdEquipmentStatus1_ISig_4 100;
BA_ "GenSigCycleTimeActive" SG_ 2466196004 FdEquipmentStatus1_ISig_4 100;
BA_ "GenSigStartValue" SG_ 2466196004 FdEquipmentStatus1_ISig_4 3;
BA_ "GenSigMaxLatency" SG_ 2466196004 FdEquipmentStatus1_ISig_4 55;
BA_ "Platform_VMCU1_Sig" SG_ 2466196004 FdEquipmentStatus1_ISig_4 1;
BA_ "SeToolAncestorID_SIGNAL" SG_ 2466196004 FdEquipmentStatus1_ISig_4 "x0000001D041709FA";
BA_ "SeToolItemID_SIGNAL" SG_ 2466196004 FdEquipmentStatus1_ISig_4 "x0000001D041709FA";
BA_ "SeToolName_SIGNAL" SG_ 2466196004 FdEquipmentStatus1_ISig_4 "FdEquipmentStatus1";
BA_ "SeToolVersion_SIGNAL" SG_ 2466196004 FdEquipmentStatus1_ISig_4 "1";
BA_ "GenSigCycleTime" SG_ 2432649764 ParkBrakeAlert_ISig_4 100;
BA_ "GenSigCycleTimeActive" SG_ 2432649764 ParkBrakeAlert_ISig_4 100;
BA_ "GenSigStartValue" SG_ 2432649764 ParkBrakeAlert_ISig_4 3;
BA_ "Platform_VMCU1_Sig" SG_ 2432649764 ParkBrakeAlert_ISig_4 1;
BA_ "GenSigCycleTime" SG_ 2432649764 IntLightMode_CoreRqst_IL_Mode 100;
BA_ "GenSigCycleTimeActive" SG_ 2432649764 IntLightMode_CoreRqst_IL_Mode 100;
BA_ "GenSigStartValue" SG_ 2432649764 IntLightMode_CoreRqst_IL_Mode 7;
BA_ "Platform_VMCU1_Sig" SG_ 2432649764 IntLightMode_CoreRqst_IL_Mode 1;
BA_ "GenSigSendType" SG_ 2432649764 WiperModeStatus_UB_ISig_4 7;
BA_ "Platform_VMCU1_Sig" SG_ 2432649764 WiperModeStatus_UB_ISig_4 1;
BA_ "GenSigCycleTime" SG_ 2432649764 SteeringColumnLockErrInd_rqst 100;
BA_ "GenSigCycleTimeActive" SG_ 2432649764 SteeringColumnLockErrInd_rqst 100;
BA_ "GenSigStartValue" SG_ 2432649764 SteeringColumnLockErrInd_rqst 7;
BA_ "GenSigMaxLatency" SG_ 2432649764 SteeringColumnLockErrInd_rqst 29;
BA_ "Platform_VMCU1_Sig" SG_ 2432649764 SteeringColumnLockErrInd_rqst 1;
BA_ "SeToolAncestorID_SIGNAL" SG_ 2432649764 SteeringColumnLockErrInd_rqst "x0000001D0419C337";
BA_ "SeToolItemID_SIGNAL" SG_ 2432649764 SteeringColumnLockErrInd_rqst "x0000001D0419C337";
BA_ "SeToolName_SIGNAL" SG_ 2432649764 SteeringColumnLockErrInd_rqst "SteeringColumnLockErrorIndication_rqst";
BA_ "SeToolVersion_SIGNAL" SG_ 2432649764 SteeringColumnLockErrInd_rqst "1";
BA_ "GenSigCycleTime" SG_ 2432649764 MainBeamIndication_cmd 100;
BA_ "GenSigCycleTimeActive" SG_ 2432649764 MainBeamIndication_cmd 100;
BA_ "GenSigStartValue" SG_ 2432649764 MainBeamIndication_cmd 3;
BA_ "GenSigMaxLatency" SG_ 2432649764 MainBeamIndication_cmd 29;
BA_ "Platform_VMCU1_Sig" SG_ 2432649764 MainBeamIndication_cmd 1;
BA_ "SeToolAncestorID_SIGNAL" SG_ 2432649764 MainBeamIndication_cmd "x0000001D041487C7";
BA_ "SeToolItemID_SIGNAL" SG_ 2432649764 MainBeamIndication_cmd "x0000001D041487C7";
BA_ "SeToolName_SIGNAL" SG_ 2432649764 MainBeamIndication_cmd "HeadLight_MainBeam_Indication_Cmd";
BA_ "SeToolVersion_SIGNAL" SG_ 2432649764 MainBeamIndication_cmd "1";
BA_ "GenSigCycleTime" SG_ 2432649764 PosLightWarning_rqst 100;
BA_ "GenSigCycleTimeActive" SG_ 2432649764 PosLightWarning_rqst 100;
BA_ "GenSigStartValue" SG_ 2432649764 PosLightWarning_rqst 3;
BA_ "GenSigMaxLatency" SG_ 2432649764 PosLightWarning_rqst 29;
BA_ "Platform_VMCU1_Sig" SG_ 2432649764 PosLightWarning_rqst 1;
BA_ "SeToolAncestorID_SIGNAL" SG_ 2432649764 PosLightWarning_rqst "x0000001D042A1531";
BA_ "SeToolItemID_SIGNAL" SG_ 2432649764 PosLightWarning_rqst "x0000001D042A1531";
BA_ "SeToolName_SIGNAL" SG_ 2432649764 PosLightWarning_rqst "PosLightWarning_rqst";
BA_ "SeToolVersion_SIGNAL" SG_ 2432649764 PosLightWarning_rqst "1";
BA_ "GenSigCycleTime" SG_ 2432649764 RainsensorActivationHMI_stat 100;
BA_ "GenSigCycleTimeActive" SG_ 2432649764 RainsensorActivationHMI_stat 100;
BA_ "GenSigStartValue" SG_ 2432649764 RainsensorActivationHMI_stat 3;
BA_ "Platform_VMCU1_Sig" SG_ 2432649764 RainsensorActivationHMI_stat 1;
BA_ "GenSigCycleTime" SG_ 2432649764 FogLight_Front_Indication_Cmd 100;
BA_ "GenSigCycleTimeActive" SG_ 2432649764 FogLight_Front_Indication_Cmd 100;
BA_ "GenSigStartValue" SG_ 2432649764 FogLight_Front_Indication_Cmd 3;
BA_ "GenSigMaxLatency" SG_ 2432649764 FogLight_Front_Indication_Cmd 29;
BA_ "Platform_VMCU1_Sig" SG_ 2432649764 FogLight_Front_Indication_Cmd 1;
BA_ "SeToolAncestorID_SIGNAL" SG_ 2432649764 FogLight_Front_Indication_Cmd "x0000001D041487AB";
BA_ "SeToolItemID_SIGNAL" SG_ 2432649764 FogLight_Front_Indication_Cmd "x0000001D041487AB";
BA_ "SeToolName_SIGNAL" SG_ 2432649764 FogLight_Front_Indication_Cmd "FogLight_Front_Indication_Cmd";
BA_ "SeToolVersion_SIGNAL" SG_ 2432649764 FogLight_Front_Indication_Cmd "1";
BA_ "GenSigCycleTime" SG_ 2432649764 ParkingLight_Indication 100;
BA_ "GenSigCycleTimeActive" SG_ 2432649764 ParkingLight_Indication 100;
BA_ "GenSigStartValue" SG_ 2432649764 ParkingLight_Indication 3;
BA_ "GenSigMaxLatency" SG_ 2432649764 ParkingLight_Indication 29;
BA_ "Platform_VMCU1_Sig" SG_ 2432649764 ParkingLight_Indication 1;
BA_ "SeToolAncestorID_SIGNAL" SG_ 2432649764 ParkingLight_Indication "x0000001D041A7C03";
BA_ "SeToolItemID_SIGNAL" SG_ 2432649764 ParkingLight_Indication "x0000001D043C4080";
BA_ "SeToolName_SIGNAL" SG_ 2432649764 ParkingLight_Indication "ParkingLight_Indication";
BA_ "SeToolVersion_SIGNAL" SG_ 2432649764 ParkingLight_Indication "3";
BA_ "GenSigCycleTime" SG_ 2432649764 DaytimeRunningLight_Indication 100;
BA_ "GenSigCycleTimeActive" SG_ 2432649764 DaytimeRunningLight_Indication 100;
BA_ "GenSigStartValue" SG_ 2432649764 DaytimeRunningLight_Indication 3;
BA_ "GenSigMaxLatency" SG_ 2432649764 DaytimeRunningLight_Indication 29;
BA_ "Platform_VMCU1_Sig" SG_ 2432649764 DaytimeRunningLight_Indication 1;
BA_ "SeToolAncestorID_SIGNAL" SG_ 2432649764 DaytimeRunningLight_Indication "x0000001D041A7C03";
BA_ "SeToolItemID_SIGNAL" SG_ 2432649764 DaytimeRunningLight_Indication "x0000001D043C4080";
BA_ "SeToolName_SIGNAL" SG_ 2432649764 DaytimeRunningLight_Indication "DaytimeRunningLight_Indication";
BA_ "SeToolVersion_SIGNAL" SG_ 2432649764 DaytimeRunningLight_Indication "3";
BA_ "GenSigCycleTime" SG_ 2432649764 EPBBackupMode_ISig_4 100;
BA_ "GenSigCycleTimeActive" SG_ 2432649764 EPBBackupMode_ISig_4 100;
BA_ "GenSigStartValue" SG_ 2432649764 EPBBackupMode_ISig_4 15;
BA_ "Platform_VMCU1_Sig" SG_ 2432649764 EPBBackupMode_ISig_4 1;
BA_ "GenSigCycleTime" SG_ 2432649764 WiperModeStatus_ISig_4 100;
BA_ "GenSigCycleTimeActive" SG_ 2432649764 WiperModeStatus_ISig_4 100;
BA_ "GenSigStartValue" SG_ 2432649764 WiperModeStatus_ISig_4 7;
BA_ "GenSigMaxLatency" SG_ 2432649764 WiperModeStatus_ISig_4 29;
BA_ "NeedsUpdateBit" SG_ 2432649764 WiperModeStatus_ISig_4 1;
BA_ "Platform_VMCU1_Sig" SG_ 2432649764 WiperModeStatus_ISig_4 1;
BA_ "SeToolAncestorID_SIGNAL" SG_ 2432649764 WiperModeStatus_ISig_4 "x0000001D0410D271";
BA_ "SeToolItemID_SIGNAL" SG_ 2432649764 WiperModeStatus_ISig_4 "x0000001D0410D271";
BA_ "SeToolName_SIGNAL" SG_ 2432649764 WiperModeStatus_ISig_4 "WiperModeStatus";
BA_ "SeToolVersion_SIGNAL" SG_ 2432649764 WiperModeStatus_ISig_4 "1";
BA_ "GenSigCycleTime" SG_ 2432649764 FrontFog_Indication 100;
BA_ "GenSigCycleTimeActive" SG_ 2432649764 FrontFog_Indication 100;
BA_ "GenSigStartValue" SG_ 2432649764 FrontFog_Indication 3;
BA_ "GenSigMaxLatency" SG_ 2432649764 FrontFog_Indication 29;
BA_ "Platform_VMCU1_Sig" SG_ 2432649764 FrontFog_Indication 1;
BA_ "SeToolAncestorID_SIGNAL" SG_ 2432649764 FrontFog_Indication "x0000001D041A7C03";
BA_ "SeToolItemID_SIGNAL" SG_ 2432649764 FrontFog_Indication "x0000001D043C4080";
BA_ "SeToolName_SIGNAL" SG_ 2432649764 FrontFog_Indication "FrontFog_Indication";
BA_ "SeToolVersion_SIGNAL" SG_ 2432649764 FrontFog_Indication "3";
BA_ "GenSigCycleTime" SG_ 2432649764 PBReleaseAcceptance_stat_ISig_4 100;
BA_ "GenSigCycleTimeActive" SG_ 2432649764 PBReleaseAcceptance_stat_ISig_4 100;
BA_ "GenSigStartValue" SG_ 2432649764 PBReleaseAcceptance_stat_ISig_4 7;
BA_ "Platform_VMCU1_Sig" SG_ 2432649764 PBReleaseAcceptance_stat_ISig_4 1;
BA_ "GenSigSendType" SG_ 2432649764 ParkingBrake_stat_UB_ISig_4 7;
BA_ "Platform_VMCU1_Sig" SG_ 2432649764 ParkingBrake_stat_UB_ISig_4 1;
BA_ "GenSigCycleTime" SG_ 2432649764 DrivingLightPlus_Indication 100;
BA_ "GenSigCycleTimeActive" SG_ 2432649764 DrivingLightPlus_Indication 100;
BA_ "GenSigStartValue" SG_ 2432649764 DrivingLightPlus_Indication 3;
BA_ "GenSigMaxLatency" SG_ 2432649764 DrivingLightPlus_Indication 29;
BA_ "Platform_VMCU1_Sig" SG_ 2432649764 DrivingLightPlus_Indication 1;
BA_ "SeToolAncestorID_SIGNAL" SG_ 2432649764 DrivingLightPlus_Indication "x0000001D041A7C03";
BA_ "SeToolItemID_SIGNAL" SG_ 2432649764 DrivingLightPlus_Indication "x0000001D043C4080";
BA_ "SeToolName_SIGNAL" SG_ 2432649764 DrivingLightPlus_Indication "DrivingLightPlus_Indication";
BA_ "SeToolVersion_SIGNAL" SG_ 2432649764 DrivingLightPlus_Indication "3";
BA_ "GenSigCycleTime" SG_ 2432649764 IntLightMode_CoreRqst_EventFlag 100;
BA_ "GenSigCycleTimeActive" SG_ 2432649764 IntLightMode_CoreRqst_EventFlag 100;
BA_ "Platform_VMCU1_Sig" SG_ 2432649764 IntLightMode_CoreRqst_EventFlag 1;
BA_ "GenSigCycleTime" SG_ 2432649764 ParkingBrake_stat_ISig_4 100;
BA_ "GenSigCycleTimeActive" SG_ 2432649764 ParkingBrake_stat_ISig_4 100;
BA_ "GenSigStartValue" SG_ 2432649764 ParkingBrake_stat_ISig_4 3;
BA_ "NeedsUpdateBit" SG_ 2432649764 ParkingBrake_stat_ISig_4 1;
BA_ "Platform_VMCU1_Sig" SG_ 2432649764 ParkingBrake_stat_ISig_4 1;
BA_ "GenSigCycleTime" SG_ 2432649764 DrivingLight_Indication 100;
BA_ "GenSigCycleTimeActive" SG_ 2432649764 DrivingLight_Indication 100;
BA_ "GenSigStartValue" SG_ 2432649764 DrivingLight_Indication 3;
BA_ "GenSigMaxLatency" SG_ 2432649764 DrivingLight_Indication 29;
BA_ "Platform_VMCU1_Sig" SG_ 2432649764 DrivingLight_Indication 1;
BA_ "SeToolAncestorID_SIGNAL" SG_ 2432649764 DrivingLight_Indication "x0000001D041A7C03";
BA_ "SeToolItemID_SIGNAL" SG_ 2432649764 DrivingLight_Indication "x0000001D043C4080";
BA_ "SeToolName_SIGNAL" SG_ 2432649764 DrivingLight_Indication "DrivingLight_Indication";
BA_ "SeToolVersion_SIGNAL" SG_ 2432649764 DrivingLight_Indication "3";
BA_ "GenSigCycleTime" SG_ 2432649764 Rainsensor_Indication 100;
BA_ "GenSigCycleTimeActive" SG_ 2432649764 Rainsensor_Indication 100;
BA_ "GenSigStartValue" SG_ 2432649764 Rainsensor_Indication 3;
BA_ "GenSigMaxLatency" SG_ 2432649764 Rainsensor_Indication 29;
BA_ "Platform_VMCU1_Sig" SG_ 2432649764 Rainsensor_Indication 1;
BA_ "SeToolAncestorID_SIGNAL" SG_ 2432649764 Rainsensor_Indication "x0000001D041A7C03";
BA_ "SeToolItemID_SIGNAL" SG_ 2432649764 Rainsensor_Indication "x0000001D043C4080";
BA_ "SeToolName_SIGNAL" SG_ 2432649764 Rainsensor_Indication "Rainsensor_Indication";
BA_ "SeToolVersion_SIGNAL" SG_ 2432649764 Rainsensor_Indication "3";
BA_ "GenSigCycleTime" SG_ 2432649764 DippedBeamIndication_cmd 100;
BA_ "GenSigCycleTimeActive" SG_ 2432649764 DippedBeamIndication_cmd 100;
BA_ "GenSigStartValue" SG_ 2432649764 DippedBeamIndication_cmd 3;
BA_ "GenSigMaxLatency" SG_ 2432649764 DippedBeamIndication_cmd 29;
BA_ "Platform_VMCU1_Sig" SG_ 2432649764 DippedBeamIndication_cmd 1;
BA_ "SeToolAncestorID_SIGNAL" SG_ 2432649764 DippedBeamIndication_cmd "x0000001D041487D9";
BA_ "SeToolItemID_SIGNAL" SG_ 2432649764 DippedBeamIndication_cmd "x0000001D041487D9";
BA_ "SeToolName_SIGNAL" SG_ 2432649764 DippedBeamIndication_cmd "HeadLight_DippedBeam_indication_Cmd";
BA_ "SeToolVersion_SIGNAL" SG_ 2432649764 DippedBeamIndication_cmd "1";
BA_ "GenSigCycleTime" SG_ 2432649764 MirrorHeatingMode_ISig_4 100;
BA_ "GenSigCycleTimeActive" SG_ 2432649764 MirrorHeatingMode_ISig_4 100;
BA_ "GenSigStartValue" SG_ 2432649764 MirrorHeatingMode_ISig_4 7;
BA_ "GenSigMaxLatency" SG_ 2432649764 MirrorHeatingMode_ISig_4 29;
BA_ "Platform_VMCU1_Sig" SG_ 2432649764 MirrorHeatingMode_ISig_4 1;
BA_ "SeToolAncestorID_SIGNAL" SG_ 2432649764 MirrorHeatingMode_ISig_4 "x0000001D0412C1DB";
BA_ "SeToolItemID_SIGNAL" SG_ 2432649764 MirrorHeatingMode_ISig_4 "x0000001D0412C1DB";
BA_ "SeToolName_SIGNAL" SG_ 2432649764 MirrorHeatingMode_ISig_4 "MirrorHeatingMode";
BA_ "SeToolVersion_SIGNAL" SG_ 2432649764 MirrorHeatingMode_ISig_4 "1";
BA_ "GenSigCycleTime" SG_ 2432649764 RearFog_Indication 100;
BA_ "GenSigCycleTimeActive" SG_ 2432649764 RearFog_Indication 100;
BA_ "GenSigStartValue" SG_ 2432649764 RearFog_Indication 3;
BA_ "GenSigMaxLatency" SG_ 2432649764 RearFog_Indication 29;
BA_ "Platform_VMCU1_Sig" SG_ 2432649764 RearFog_Indication 1;
BA_ "SeToolAncestorID_SIGNAL" SG_ 2432649764 RearFog_Indication "x0000001D041A7C03";
BA_ "SeToolItemID_SIGNAL" SG_ 2432649764 RearFog_Indication "x0000001D043C4080";
BA_ "SeToolName_SIGNAL" SG_ 2432649764 RearFog_Indication "RearFog_Indication";
BA_ "SeToolVersion_SIGNAL" SG_ 2432649764 RearFog_Indication "3";
BA_ "GenSigCycleTime" SG_ 2432649764 InteriorLightLevelInd_cmd 100;
BA_ "GenSigCycleTimeActive" SG_ 2432649764 InteriorLightLevelInd_cmd 100;
BA_ "GenSigStartValue" SG_ 2432649764 InteriorLightLevelInd_cmd 255;
BA_ "Platform_VMCU1_Sig" SG_ 2432649764 InteriorLightLevelInd_cmd 1;
BA_ "GenSigCycleTime" SG_ 2432649764 FogLight_Rear_Indication_Cmd 100;
BA_ "GenSigCycleTimeActive" SG_ 2432649764 FogLight_Rear_Indication_Cmd 100;
BA_ "GenSigStartValue" SG_ 2432649764 FogLight_Rear_Indication_Cmd 3;
BA_ "GenSigMaxLatency" SG_ 2432649764 FogLight_Rear_Indication_Cmd 29;
BA_ "Platform_VMCU1_Sig" SG_ 2432649764 FogLight_Rear_Indication_Cmd 1;
BA_ "SeToolAncestorID_SIGNAL" SG_ 2432649764 FogLight_Rear_Indication_Cmd "x0000001D041487AD";
BA_ "SeToolItemID_SIGNAL" SG_ 2432649764 FogLight_Rear_Indication_Cmd "x0000001D041487AD";
BA_ "SeToolName_SIGNAL" SG_ 2432649764 FogLight_Rear_Indication_Cmd "FogLight_Rear_Indication_Cmd";
BA_ "SeToolVersion_SIGNAL" SG_ 2432649764 FogLight_Rear_Indication_Cmd "1";
BA_ "GenSigCycleTime" SG_ 2432649764 PosLight_Indication_Cmd 100;
BA_ "GenSigCycleTimeActive" SG_ 2432649764 PosLight_Indication_Cmd 100;
BA_ "GenSigStartValue" SG_ 2432649764 PosLight_Indication_Cmd 3;
BA_ "GenSigMaxLatency" SG_ 2432649764 PosLight_Indication_Cmd 29;
BA_ "Platform_VMCU1_Sig" SG_ 2432649764 PosLight_Indication_Cmd 1;
BA_ "SeToolAncestorID_SIGNAL" SG_ 2432649764 PosLight_Indication_Cmd "x0000001D041487E1";
BA_ "SeToolItemID_SIGNAL" SG_ 2432649764 PosLight_Indication_Cmd "x0000001D041487E1";
BA_ "SeToolName_SIGNAL" SG_ 2432649764 PosLight_Indication_Cmd "PosLight_Indication_Cmd";
BA_ "SeToolVersion_SIGNAL" SG_ 2432649764 PosLight_Indication_Cmd "1";
BA_ "GenSigCycleTime" SG_ 2432649764 DirIndicationTimeoutInd_rqst 100;
BA_ "GenSigCycleTimeActive" SG_ 2432649764 DirIndicationTimeoutInd_rqst 100;
BA_ "GenSigStartValue" SG_ 2432649764 DirIndicationTimeoutInd_rqst 3;
BA_ "GenSigMaxLatency" SG_ 2432649764 DirIndicationTimeoutInd_rqst 29;
BA_ "Platform_VMCU1_Sig" SG_ 2432649764 DirIndicationTimeoutInd_rqst 1;
BA_ "SeToolAncestorID_SIGNAL" SG_ 2432649764 DirIndicationTimeoutInd_rqst "x0000001D041A78D8";
BA_ "SeToolItemID_SIGNAL" SG_ 2432649764 DirIndicationTimeoutInd_rqst "x0000001D0437E10F";
BA_ "SeToolName_SIGNAL" SG_ 2432649764 DirIndicationTimeoutInd_rqst "DirectionIndicationTimeout_Info";
BA_ "SeToolVersion_SIGNAL" SG_ 2432649764 DirIndicationTimeoutInd_rqst "2";
BA_REL_ "GenSigFirstTimeoutTime" BU_SG_REL_ HMIIOM SG_ 2549401380 StaticCornerLightLamp_stat_ISig_ 6000;
BA_REL_ "GenSigTimeoutTime" BU_SG_REL_ HMIIOM SG_ 2549401380 StaticCornerLightLamp_stat_ISig_ 1500;
BA_REL_ "GenSigFirstTimeoutTime" BU_SG_REL_ HMIIOM SG_ 2549401380 DRLLamp_stat_ISig_4 6000;
BA_REL_ "GenSigTimeoutTime" BU_SG_REL_ HMIIOM SG_ 2549401380 DRLLamp_stat_ISig_4 1500;
BA_REL_ "GenSigFirstTimeoutTime" BU_SG_REL_ HMIIOM SG_ 2549401380 DirInd_Front_Status_ISig_4 6000;
BA_REL_ "GenSigTimeoutTime" BU_SG_REL_ HMIIOM SG_ 2549401380 DirInd_Front_Status_ISig_4 1500;
BA_REL_ "GenSigFirstTimeoutTime" BU_SG_REL_ HMIIOM SG_ 2549401380 DirInd_Rear_Status_ISig_4 6000;
BA_REL_ "GenSigTimeoutTime" BU_SG_REL_ HMIIOM SG_ 2549401380 DirInd_Rear_Status_ISig_4 1500;
BA_REL_ "GenSigFirstTimeoutTime" BU_SG_REL_ HMIIOM SG_ 2549401380 ChassiInstepLightsLamp_stat_ISig 6000;
BA_REL_ "GenSigTimeoutTime" BU_SG_REL_ HMIIOM SG_ 2549401380 ChassiInstepLightsLamp_stat_ISig 1500;
BA_REL_ "GenSigFirstTimeoutTime" BU_SG_REL_ HMIIOM SG_ 2549401380 PositionLightLamp_stat_ISig_4 6000;
BA_REL_ "GenSigTimeoutTime" BU_SG_REL_ HMIIOM SG_ 2549401380 PositionLightLamp_stat_ISig_4 1500;
BA_REL_ "GenSigFirstTimeoutTime" BU_SG_REL_ HMIIOM SG_ 2549401380 MainBeamLamp_stat_ISig_4 6000;
BA_REL_ "GenSigTimeoutTime" BU_SG_REL_ HMIIOM SG_ 2549401380 MainBeamLamp_stat_ISig_4 1500;
BA_REL_ "GenSigFirstTimeoutTime" BU_SG_REL_ HMIIOM SG_ 2549401380 BrakeLightLamp_stat_ISig_4 6000;
BA_REL_ "GenSigTimeoutTime" BU_SG_REL_ HMIIOM SG_ 2549401380 BrakeLightLamp_stat_ISig_4 1500;
BA_REL_ "GenSigFirstTimeoutTime" BU_SG_REL_ HMIIOM SG_ 2549401380 TrailerConnectionStatus_ISig_4 6000;
BA_REL_ "GenSigTimeoutTime" BU_SG_REL_ HMIIOM SG_ 2549401380 TrailerConnectionStatus_ISig_4 1500;
BA_REL_ "GenSigFirstTimeoutTime" BU_SG_REL_ HMIIOM SG_ 2549401380 RevLightLamp_stat_ISig_4 6000;
BA_REL_ "GenSigTimeoutTime" BU_SG_REL_ HMIIOM SG_ 2549401380 RevLightLamp_stat_ISig_4 1500;
BA_REL_ "GenSigFirstTimeoutTime" BU_SG_REL_ HMIIOM SG_ 2549401380 AuxFogLightLamp_stat_ISig_4 6000;
BA_REL_ "GenSigTimeoutTime" BU_SG_REL_ HMIIOM SG_ 2549401380 AuxFogLightLamp_stat_ISig_4 1500;
BA_REL_ "GenSigFirstTimeoutTime" BU_SG_REL_ HMIIOM SG_ 2549401380 DirIndSideLamp_stat 6000;
BA_REL_ "GenSigTimeoutTime" BU_SG_REL_ HMIIOM SG_ 2549401380 DirIndSideLamp_stat 1500;
BA_REL_ "GenSigFirstTimeoutTime" BU_SG_REL_ HMIIOM SG_ 2549401380 ExtraMainBeamLamp_stat_ISig_4 6000;
BA_REL_ "GenSigTimeoutTime" BU_SG_REL_ HMIIOM SG_ 2549401380 ExtraMainBeamLamp_stat_ISig_4 1500;
BA_REL_ "GenSigFirstTimeoutTime" BU_SG_REL_ HMIIOM SG_ 2549401380 FogLightFrontLamp_stat_ISig_4 6000;
BA_REL_ "GenSigTimeoutTime" BU_SG_REL_ HMIIOM SG_ 2549401380 FogLightFrontLamp_stat_ISig_4 1500;
BA_REL_ "GenSigFirstTimeoutTime" BU_SG_REL_ HMIIOM SG_ 2549401380 DippedBeamLamp_stat_ISig_4 6000;
BA_REL_ "GenSigTimeoutTime" BU_SG_REL_ HMIIOM SG_ 2549401380 DippedBeamLamp_stat_ISig_4 1500;
BA_REL_ "GenSigFirstTimeoutTime" BU_SG_REL_ HMIIOM SG_ 2549401380 FogLightRearLamp_stat_ISig_4 6000;
BA_REL_ "GenSigTimeoutTime" BU_SG_REL_ HMIIOM SG_ 2549401380 FogLightRearLamp_stat_ISig_4 1500;
BA_REL_ "GenSigFirstTimeoutTime" BU_SG_REL_ BBM SG_ 2481980708 StartupProhibitStatus_ISig_4 3000;
BA_REL_ "GenSigTimeoutTime" BU_SG_REL_ BBM SG_ 2481980708 StartupProhibitStatus_ISig_4 300;
BA_REL_ "GenSigFirstTimeoutTime" BU_SG_REL_ HMIIOM SG_ 2481980708 StartupProhibitStatus_ISig_4 3000;
BA_REL_ "GenSigTimeoutTime" BU_SG_REL_ HMIIOM SG_ 2481980708 StartupProhibitStatus_ISig_4 300;
BA_REL_ "GenSigFirstTimeoutTime" BU_SG_REL_ HMIIOM SG_ 2481980708 LoadDistributionReasonChanged_IS 3000;
BA_REL_ "GenSigTimeoutTime" BU_SG_REL_ HMIIOM SG_ 2481980708 LoadDistributionReasonChanged_IS 300;
BA_REL_ "GenSigFirstTimeoutTime" BU_SG_REL_ HMIIOM SG_ 2481980708 RampLevelStatus_ISig_4 3000;
BA_REL_ "GenSigTimeoutTime" BU_SG_REL_ HMIIOM SG_ 2481980708 RampLevelStatus_ISig_4 300;
BA_REL_ "GenSigFirstTimeoutTime" BU_SG_REL_ CIOM SG_ 2481980708 RampLevelStatus_ISig_4 3000;
BA_REL_ "GenSigTimeoutTime" BU_SG_REL_ CIOM SG_ 2481980708 RampLevelStatus_ISig_4 300;
BA_REL_ "GenSigFirstTimeoutTime" BU_SG_REL_ BBM SG_ 2481980708 KneelingInformation_ISig_4 3000;
BA_REL_ "GenSigTimeoutTime" BU_SG_REL_ BBM SG_ 2481980708 KneelingInformation_ISig_4 300;
BA_REL_ "GenSigFirstTimeoutTime" BU_SG_REL_ HMIIOM SG_ 2481980708 KneelingInformation_ISig_4 3000;
BA_REL_ "GenSigTimeoutTime" BU_SG_REL_ HMIIOM SG_ 2481980708 KneelingInformation_ISig_4 300;
BA_REL_ "GenSigFirstTimeoutTime" BU_SG_REL_ CIOM SG_ 2481980708 KneelingInformation_ISig_4 3000;
BA_REL_ "GenSigTimeoutTime" BU_SG_REL_ CIOM SG_ 2481980708 KneelingInformation_ISig_4 300;
BA_REL_ "GenSigFirstTimeoutTime" BU_SG_REL_ TECU SG_ 2481980708 FrontAxleInBumperRange_ISig_4 3000;
BA_REL_ "GenSigTimeoutTime" BU_SG_REL_ TECU SG_ 2481980708 FrontAxleInBumperRange_ISig_4 500;
BA_REL_ "GenSigFirstTimeoutTime" BU_SG_REL_ HMIIOM SG_ 2481980708 FrontAxleInBumperRange_ISig_4 3000;
BA_REL_ "GenSigTimeoutTime" BU_SG_REL_ HMIIOM SG_ 2481980708 FrontAxleInBumperRange_ISig_4 500;
BA_REL_ "GenSigFirstTimeoutTime" BU_SG_REL_ HMIIOM SG_ 2481980708 FerryFunctionStatus_ISig_4 3000;
BA_REL_ "GenSigTimeoutTime" BU_SG_REL_ HMIIOM SG_ 2481980708 FerryFunctionStatus_ISig_4 300;
BA_REL_ "GenSigFirstTimeoutTime" BU_SG_REL_ CIOM SG_ 2481980708 FerryFunctionStatus_ISig_4 3000;
BA_REL_ "GenSigTimeoutTime" BU_SG_REL_ CIOM SG_ 2481980708 FerryFunctionStatus_ISig_4 300;
BA_REL_ "GenSigFirstTimeoutTime" BU_SG_REL_ TECU SG_ 2481980708 EngPtoConsumesTorque 3000;
BA_REL_ "GenSigTimeoutTime" BU_SG_REL_ TECU SG_ 2481980708 EngPtoConsumesTorque 500;
BA_REL_ "GenSigFirstTimeoutTime" BU_SG_REL_ BBM SG_ 2481980708 LiftingControlModeRearAxle_ISig_ 3000;
BA_REL_ "GenSigTimeoutTime" BU_SG_REL_ BBM SG_ 2481980708 LiftingControlModeRearAxle_ISig_ 300;
BA_REL_ "GenSigFirstTimeoutTime" BU_SG_REL_ CIOM SG_ 2481980708 KneelingStatusHMI_ISig_4 3000;
BA_REL_ "GenSigTimeoutTime" BU_SG_REL_ CIOM SG_ 2481980708 KneelingStatusHMI_ISig_4 300;
BA_REL_ "GenSigFirstTimeoutTime" BU_SG_REL_ VGGSECUSystem SG_ 2481980708 SWEngineStop_rqst_ISig_4 3000;
BA_REL_ "GenSigTimeoutTime" BU_SG_REL_ VGGSECUSystem SG_ 2481980708 SWEngineStop_rqst_ISig_4 300;
BA_REL_ "GenSigFirstTimeoutTime" BU_SG_REL_ BBM SG_ 2481980708 SWEngineStop_rqst_ISig_4 3000;
BA_REL_ "GenSigTimeoutTime" BU_SG_REL_ BBM SG_ 2481980708 SWEngineStop_rqst_ISig_4 300;
BA_REL_ "GenSigFirstTimeoutTime" BU_SG_REL_ CIOM SG_ 2481980708 FrontEndPositionStatus_ISig_4 3000;
BA_REL_ "GenSigTimeoutTime" BU_SG_REL_ CIOM SG_ 2481980708 FrontEndPositionStatus_ISig_4 300;
BA_REL_ "GenSigFirstTimeoutTime" BU_SG_REL_ BBM SG_ 2481980708 LiftingControlModeFrontAxle_ISig 3000;
BA_REL_ "GenSigTimeoutTime" BU_SG_REL_ BBM SG_ 2481980708 LiftingControlModeFrontAxle_ISig 300;
BA_REL_ "GenSigFirstTimeoutTime" BU_SG_REL_ HMIIOM SG_ 2481980708 UnevenLoadWarning_ISig_4 3000;
BA_REL_ "GenSigTimeoutTime" BU_SG_REL_ HMIIOM SG_ 2481980708 UnevenLoadWarning_ISig_4 300;
BA_REL_ "GenSigFirstTimeoutTime" BU_SG_REL_ HMIIOM SG_ 2481980708 RampHeightOutsideTargetRange_ISi 3000;
BA_REL_ "GenSigTimeoutTime" BU_SG_REL_ HMIIOM SG_ 2481980708 RampHeightOutsideTargetRange_ISi 300;
BA_REL_ "GenSigFirstTimeoutTime" BU_SG_REL_ CIOM SG_ 2481980708 RampHeightOutsideTargetRange_ISi 3000;
BA_REL_ "GenSigTimeoutTime" BU_SG_REL_ CIOM SG_ 2481980708 RampHeightOutsideTargetRange_ISi 300;
BA_REL_ "GenSigFirstTimeoutTime" BU_SG_REL_ HMIIOM SG_ 2481980708 DriveLevelPosUserInteraction_ISi 3000;
BA_REL_ "GenSigTimeoutTime" BU_SG_REL_ HMIIOM SG_ 2481980708 DriveLevelPosUserInteraction_ISi 300;
BA_REL_ "GenSigFirstTimeoutTime" BU_SG_REL_ TECU SG_ 2481980708 RearEndPositionStatus_ISig_4 3000;
BA_REL_ "GenSigTimeoutTime" BU_SG_REL_ TECU SG_ 2481980708 RearEndPositionStatus_ISig_4 500;
BA_REL_ "GenSigFirstTimeoutTime" BU_SG_REL_ CIOM SG_ 2481980708 RearEndPositionStatus_ISig_4 3000;
BA_REL_ "GenSigTimeoutTime" BU_SG_REL_ CIOM SG_ 2481980708 RearEndPositionStatus_ISig_4 300;
BA_REL_ "GenSigFirstTimeoutTime" BU_SG_REL_ HMIIOM SG_ 2481980708 ProhibitControlStatus_ISig_4 3000;
BA_REL_ "GenSigTimeoutTime" BU_SG_REL_ HMIIOM SG_ 2481980708 ProhibitControlStatus_ISig_4 300;
BA_REL_ "GenSigFirstTimeoutTime" BU_SG_REL_ BBM SG_ 2481980708 ProhibitControlStatus_ISig_4 3000;
BA_REL_ "GenSigTimeoutTime" BU_SG_REL_ BBM SG_ 2481980708 ProhibitControlStatus_ISig_4 300;
BA_REL_ "GenSigFirstTimeoutTime" BU_SG_REL_ CIOM SG_ 2481980708 ChangeKneelACK_ISig_4 3000;
BA_REL_ "GenSigTimeoutTime" BU_SG_REL_ CIOM SG_ 2481980708 ChangeKneelACK_ISig_4 300;
BA_REL_ "GenSigFirstTimeoutTime" BU_SG_REL_ CIOM SG_ 2481980708 RollEndPositionStatus_ISig_4 3000;
BA_REL_ "GenSigTimeoutTime" BU_SG_REL_ CIOM SG_ 2481980708 RollEndPositionStatus_ISig_4 300;
BA_REL_ "GenSigFirstTimeoutTime" BU_SG_REL_ HMIIOM SG_ 2481980708 TransferCaseBadCondition 3000;
BA_REL_ "GenSigTimeoutTime" BU_SG_REL_ HMIIOM SG_ 2481980708 TransferCaseBadCondition 300;
BA_REL_ "GenSigFirstTimeoutTime" BU_SG_REL_ CIOM SG_ 2481980708 ECSStandbyAllowed_ISig_4 3000;
BA_REL_ "GenSigTimeoutTime" BU_SG_REL_ CIOM SG_ 2481980708 ECSStandbyAllowed_ISig_4 300;
BA_REL_ "GenSigFirstTimeoutTime" BU_SG_REL_ TECU SG_ 2481980708 RearAxleInBumperRange_ISig_4 3000;
BA_REL_ "GenSigTimeoutTime" BU_SG_REL_ TECU SG_ 2481980708 RearAxleInBumperRange_ISig_4 500;
BA_REL_ "GenSigFirstTimeoutTime" BU_SG_REL_ HMIIOM SG_ 2481980708 RearAxleInBumperRange_ISig_4 3000;
BA_REL_ "GenSigTimeoutTime" BU_SG_REL_ HMIIOM SG_ 2481980708 RearAxleInBumperRange_ISig_4 500;
BA_REL_ "GenSigFirstTimeoutTime" BU_SG_REL_ BBM SG_ 2515190820 RelativeLevelRearAxleRight_ISig_ 3000;
BA_REL_ "GenSigTimeoutTime" BU_SG_REL_ BBM SG_ 2515190820 RelativeLevelRearAxleRight_ISig_ 600;
BA_REL_ "GenSigFirstTimeoutTime" BU_SG_REL_ BBM SG_ 2515190820 RelativeLevelFrontAxleRight_ISig 3000;
BA_REL_ "GenSigTimeoutTime" BU_SG_REL_ BBM SG_ 2515190820 RelativeLevelFrontAxleRight_ISig 600;
BA_REL_ "GenSigFirstTimeoutTime" BU_SG_REL_ BBM SG_ 2515190820 RelativeLevelFrontAxleLeft_ISig_ 3000;
BA_REL_ "GenSigTimeoutTime" BU_SG_REL_ BBM SG_ 2515190820 RelativeLevelFrontAxleLeft_ISig_ 600;
BA_REL_ "GenSigFirstTimeoutTime" BU_SG_REL_ BBM SG_ 2515190820 RelativeLevelRearAxleLeft_ISig_4 3000;
BA_REL_ "GenSigTimeoutTime" BU_SG_REL_ BBM SG_ 2515190820 RelativeLevelRearAxleLeft_ISig_4 600;
BA_REL_ "GenSigFirstTimeoutTime" BU_SG_REL_ HMIIOM SG_ 2549579812 RefrigTimer_rqst_DayOfWeekRq 6000;
BA_REL_ "GenSigTimeoutTime" BU_SG_REL_ HMIIOM SG_ 2549579812 RefrigTimer_rqst_DayOfWeekRq 1500;
BA_REL_ "GenSigFirstTimeoutTime" BU_SG_REL_ HMIIOM SG_ 2549579812 RefrigTimer_rqst_Hours 6000;
BA_REL_ "GenSigTimeoutTime" BU_SG_REL_ HMIIOM SG_ 2549579812 RefrigTimer_rqst_Hours 1500;
BA_REL_ "GenSigFirstTimeoutTime" BU_SG_REL_ TECU SG_ 2549579812 RSLAssistStatus 6000;
BA_REL_ "GenSigTimeoutTime" BU_SG_REL_ TECU SG_ 2549579812 RSLAssistStatus 1500;
BA_REL_ "GenSigFirstTimeoutTime" BU_SG_REL_ HMIIOM SG_ 2549579812 RefrigTimer_rqst_SetAlarmOper 6000;
BA_REL_ "GenSigTimeoutTime" BU_SG_REL_ HMIIOM SG_ 2549579812 RefrigTimer_rqst_SetAlarmOper 1500;
BA_REL_ "GenSigFirstTimeoutTime" BU_SG_REL_ HMIIOM SG_ 2549579812 RefrigTimer_rqst_Minutes 6000;
BA_REL_ "GenSigTimeoutTime" BU_SG_REL_ HMIIOM SG_ 2549579812 RefrigTimer_rqst_Minutes 1500;
BA_REL_ "GenSigFirstTimeoutTime" BU_SG_REL_ VGGSECUSystem SG_ 2549430564 HighResolutionTripDistance2_ISig 12000;
BA_REL_ "GenSigTimeoutTime" BU_SG_REL_ VGGSECUSystem SG_ 2549430564 HighResolutionTripDistance2_ISig 3000;
BA_REL_ "GenSigFirstTimeoutTime" BU_SG_REL_ HMIIOM SG_ 2549430564 HighResolutionTripDistance2_ISig 6000;
BA_REL_ "GenSigTimeoutTime" BU_SG_REL_ HMIIOM SG_ 2549430564 HighResolutionTripDistance2_ISig 1500;
BA_REL_ "GenSigFirstTimeoutTime" BU_SG_REL_ BBM SG_ 2549430564 HighResolutionTripDistance1_ISig 6000;
BA_REL_ "GenSigTimeoutTime" BU_SG_REL_ BBM SG_ 2549430564 HighResolutionTripDistance1_ISig 1500;
BA_REL_ "GenSigFirstTimeoutTime" BU_SG_REL_ VGGSECUSystem SG_ 2549430564 HighResolutionTripDistance1_ISig 12000;
BA_REL_ "GenSigTimeoutTime" BU_SG_REL_ VGGSECUSystem SG_ 2549430564 HighResolutionTripDistance1_ISig 3000;
BA_REL_ "GenSigFirstTimeoutTime" BU_SG_REL_ HMIIOM SG_ 2549430564 HighResolutionTripDistance1_ISig 6000;
BA_REL_ "GenSigTimeoutTime" BU_SG_REL_ HMIIOM SG_ 2549430564 HighResolutionTripDistance1_ISig 1500;
BA_REL_ "GenSigFirstTimeoutTime" BU_SG_REL_ HMIIOM SG_ 2566559268 WasherFluidLevel_ISig_4 12000;
BA_REL_ "GenSigTimeoutTime" BU_SG_REL_ HMIIOM SG_ 2566559268 WasherFluidLevel_ISig_4 3000;
BA_REL_ "GenSigFirstTimeoutTime" BU_SG_REL_ HMIIOM SG_ 2566559268 FuelVolume_ISig_4 12000;
BA_REL_ "GenSigTimeoutTime" BU_SG_REL_ HMIIOM SG_ 2566559268 FuelVolume_ISig_4 3000;
BA_REL_ "GenSigFirstTimeoutTime" BU_SG_REL_ EMS SG_ 2566559268 KFactor 12000;
BA_REL_ "GenSigTimeoutTime" BU_SG_REL_ EMS SG_ 2566559268 KFactor 3000;
BA_REL_ "GenSigFirstTimeoutTime" BU_SG_REL_ TECU SG_ 2566559268 KFactor 12000;
BA_REL_ "GenSigTimeoutTime" BU_SG_REL_ TECU SG_ 2566559268 KFactor 3000;
BA_REL_ "GenSigFirstTimeoutTime" BU_SG_REL_ BBM SG_ 2566559268 KFactor 12000;
BA_REL_ "GenSigTimeoutTime" BU_SG_REL_ BBM SG_ 2566559268 KFactor 3000;
BA_REL_ "GenSigFirstTimeoutTime" BU_SG_REL_ DACU SG_ 2566559268 KFactor 12000;
BA_REL_ "GenSigTimeoutTime" BU_SG_REL_ DACU SG_ 2566559268 KFactor 3000;
BA_REL_ "GenSigFirstTimeoutTime" BU_SG_REL_ HMIIOM SG_ 2566559268 ManTransmiOilTemp_ISig_4 12000;
BA_REL_ "GenSigTimeoutTime" BU_SG_REL_ HMIIOM SG_ 2566559268 ManTransmiOilTemp_ISig_4 3000;
BA_REL_ "GenSigFirstTimeoutTime" BU_SG_REL_ HMIIOM SG_ 2566559268 EngSpeedGreenAreaMode_ISig_4 12000;
BA_REL_ "GenSigTimeoutTime" BU_SG_REL_ HMIIOM SG_ 2566559268 EngSpeedGreenAreaMode_ISig_4 3000;
BA_REL_ "GenSigFirstTimeoutTime" BU_SG_REL_ CIOM SG_ 2515721252 CabRoofSignLightFeedback_stat 6000;
BA_REL_ "GenSigTimeoutTime" BU_SG_REL_ CIOM SG_ 2515721252 CabRoofSignLightFeedback_stat 6000;
BA_REL_ "GenSigFirstTimeoutTime" BU_SG_REL_ CIOM SG_ 2515721252 TemporaryRSLStatus 6000;
BA_REL_ "GenSigTimeoutTime" BU_SG_REL_ CIOM SG_ 2515721252 TemporaryRSLStatus 6000;
BA_REL_ "GenSigFirstTimeoutTime" BU_SG_REL_ CIOM SG_ 2515721252 CabExtraSideWrknLightFdbk_stat_I 6000;
BA_REL_ "GenSigTimeoutTime" BU_SG_REL_ CIOM SG_ 2515721252 CabExtraSideWrknLightFdbk_stat_I 6000;
BA_REL_ "GenSigFirstTimeoutTime" BU_SG_REL_ BBM SG_ 2515721252 CabExtraSideWrknLightFdbk_stat_I 3000;
BA_REL_ "GenSigTimeoutTime" BU_SG_REL_ BBM SG_ 2515721252 CabExtraSideWrknLightFdbk_stat_I 600;
BA_REL_ "GenSigFirstTimeoutTime" BU_SG_REL_ BBM SG_ 2515721252 CabWrknLightChassisFdbk_stat_ISi 3000;
BA_REL_ "GenSigTimeoutTime" BU_SG_REL_ BBM SG_ 2515721252 CabWrknLightChassisFdbk_stat_ISi 600;
BA_REL_ "GenSigFirstTimeoutTime" BU_SG_REL_ CIOM SG_ 2515721252 CabWrknLightChassisFdbk_stat_ISi 6000;
BA_REL_ "GenSigTimeoutTime" BU_SG_REL_ CIOM SG_ 2515721252 CabWrknLightChassisFdbk_stat_ISi 6000;
BA_REL_ "GenSigFirstTimeoutTime" BU_SG_REL_ HMIIOM SG_ 2515721252 HeadLightLevelRequest_stat 3000;
BA_REL_ "GenSigTimeoutTime" BU_SG_REL_ HMIIOM SG_ 2515721252 HeadLightLevelRequest_stat 600;
BA_REL_ "GenSigFirstTimeoutTime" BU_SG_REL_ CIOM SG_ 2515721252 CabTrailerBodyLgthnFdbk_stat 6000;
BA_REL_ "GenSigTimeoutTime" BU_SG_REL_ CIOM SG_ 2515721252 CabTrailerBodyLgthnFdbk_stat 6000;
BA_REL_ "GenSigFirstTimeoutTime" BU_SG_REL_ BBM SG_ 2515721252 DiffLockInterWhlStatusSplitBox_I 3000;
BA_REL_ "GenSigTimeoutTime" BU_SG_REL_ BBM SG_ 2515721252 DiffLockInterWhlStatusSplitBox_I 600;
BA_REL_ "GenSigFirstTimeoutTime" BU_SG_REL_ CIOM SG_ 2515721252 BodyOrCabWorkingLightFdbk_stat_I 6000;
BA_REL_ "GenSigTimeoutTime" BU_SG_REL_ CIOM SG_ 2515721252 BodyOrCabWorkingLightFdbk_stat_I 6000;
BA_REL_ "GenSigFirstTimeoutTime" BU_SG_REL_ BBM SG_ 2515721252 BodyOrCabWorkingLightFdbk_stat_I 3000;
BA_REL_ "GenSigTimeoutTime" BU_SG_REL_ BBM SG_ 2515721252 BodyOrCabWorkingLightFdbk_stat_I 600;
BA_REL_ "GenSigFirstTimeoutTime" BU_SG_REL_ HMIIOM SG_ 2515721252 WheelBasedVehicleSpeedLowRes_ISi 3000;
BA_REL_ "GenSigTimeoutTime" BU_SG_REL_ HMIIOM SG_ 2515721252 WheelBasedVehicleSpeedLowRes_ISi 600;
BA_REL_ "GenSigFirstTimeoutTime" BU_SG_REL_ CIOM SG_ 2515721252 WheelBasedVehicleSpeedLowRes_ISi 6000;
BA_REL_ "GenSigTimeoutTime" BU_SG_REL_ CIOM SG_ 2515721252 WheelBasedVehicleSpeedLowRes_ISi 6000;
BA_REL_ "GenSigFirstTimeoutTime" BU_SG_REL_ VGGSECUSystem SG_ 2515721252 AirDryerCoolingFanSpeed_rqst 3000;
BA_REL_ "GenSigTimeoutTime" BU_SG_REL_ VGGSECUSystem SG_ 2515721252 AirDryerCoolingFanSpeed_rqst 600;
BA_REL_ "GenSigFirstTimeoutTime" BU_SG_REL_ EMS SG_ 2515721252 AirDryerCoolingFanSpeed_rqst 6000;
BA_REL_ "GenSigTimeoutTime" BU_SG_REL_ EMS SG_ 2515721252 AirDryerCoolingFanSpeed_rqst 1500;
BA_REL_ "GenSigFirstTimeoutTime" BU_SG_REL_ CIOM SG_ 2515721252 CabFrontSpotFeedback_Status 6000;
BA_REL_ "GenSigTimeoutTime" BU_SG_REL_ CIOM SG_ 2515721252 CabFrontSpotFeedback_Status 6000;
BA_REL_ "GenSigFirstTimeoutTime" BU_SG_REL_ CIOM SG_ 2515721252 CabTiltEnableStatus 6000;
BA_REL_ "GenSigTimeoutTime" BU_SG_REL_ CIOM SG_ 2515721252 CabTiltEnableStatus 6000;
BA_REL_ "GenSigFirstTimeoutTime" BU_SG_REL_ BBM SG_ 2515721252 TransmReverseDirectionSw_stat_IS 3000;
BA_REL_ "GenSigTimeoutTime" BU_SG_REL_ BBM SG_ 2515721252 TransmReverseDirectionSw_stat_IS 600;
BA_REL_ "GenSigFirstTimeoutTime" BU_SG_REL_ HMIIOM SG_ 2515721252 CabRoofSpotFeedback_Status 3000;
BA_REL_ "GenSigTimeoutTime" BU_SG_REL_ HMIIOM SG_ 2515721252 CabRoofSpotFeedback_Status 600;
BA_REL_ "GenSigFirstTimeoutTime" BU_SG_REL_ CIOM SG_ 2515721252 CabRoofSpotFeedback_Status 6000;
BA_REL_ "GenSigTimeoutTime" BU_SG_REL_ CIOM SG_ 2515721252 CabRoofSpotFeedback_Status 6000;
BA_REL_ "GenSigFirstTimeoutTime" BU_SG_REL_ CIOM SG_ 2515721252 CabBeaconLightFeedback_Status_IS 6000;
BA_REL_ "GenSigTimeoutTime" BU_SG_REL_ CIOM SG_ 2515721252 CabBeaconLightFeedback_Status_IS 6000;
BA_REL_ "GenSigFirstTimeoutTime" BU_SG_REL_ BBM SG_ 2515721252 CabBeaconLightFeedback_Status_IS 3000;
BA_REL_ "GenSigTimeoutTime" BU_SG_REL_ BBM SG_ 2515721252 CabBeaconLightFeedback_Status_IS 600;
BA_REL_ "GenSigFirstTimeoutTime" BU_SG_REL_ CIOM SG_ 2515721252 ExtraAxleSteeringFunctionStat_IS 6000;
BA_REL_ "GenSigTimeoutTime" BU_SG_REL_ CIOM SG_ 2515721252 ExtraAxleSteeringFunctionStat_IS 6000;
BA_REL_ "GenSigFirstTimeoutTime" BU_SG_REL_ BBM SG_ 2515721252 CabTiltLockStatus_ISig_4 3000;
BA_REL_ "GenSigTimeoutTime" BU_SG_REL_ BBM SG_ 2515721252 CabTiltLockStatus_ISig_4 600;
BA_REL_ "GenSigFirstTimeoutTime" BU_SG_REL_ HMIIOM SG_ 2515721252 CabTiltLockStatus_ISig_4 3000;
BA_REL_ "GenSigTimeoutTime" BU_SG_REL_ HMIIOM SG_ 2515721252 CabTiltLockStatus_ISig_4 600;
BA_REL_ "GenSigFirstTimeoutTime" BU_SG_REL_ HMIIOM SG_ 2515721252 PositionLightRearLamp_stat_ISig_ 3000;
BA_REL_ "GenSigTimeoutTime" BU_SG_REL_ HMIIOM SG_ 2515721252 PositionLightRearLamp_stat_ISig_ 600;
BA_REL_ "GenSigFirstTimeoutTime" BU_SG_REL_ BBM SG_ 2498842916 Pto1BadCondition_ISig_4 3000;
BA_REL_ "GenSigTimeoutTime" BU_SG_REL_ BBM SG_ 2498842916 Pto1BadCondition_ISig_4 450;
BA_REL_ "GenSigFirstTimeoutTime" BU_SG_REL_ HMIIOM SG_ 2498842916 Pto1BadCondition_ISig_4 3000;
BA_REL_ "GenSigTimeoutTime" BU_SG_REL_ HMIIOM SG_ 2498842916 Pto1BadCondition_ISig_4 450;
BA_REL_ "GenSigFirstTimeoutTime" BU_SG_REL_ HMIIOM SG_ 2498842916 Pto4BadCondition 3000;
BA_REL_ "GenSigTimeoutTime" BU_SG_REL_ HMIIOM SG_ 2498842916 Pto4BadCondition 450;
BA_REL_ "GenSigFirstTimeoutTime" BU_SG_REL_ BBM SG_ 2498842916 Pto4BadCondition 3000;
BA_REL_ "GenSigTimeoutTime" BU_SG_REL_ BBM SG_ 2498842916 Pto4BadCondition 450;
BA_REL_ "GenSigFirstTimeoutTime" BU_SG_REL_ HMIIOM SG_ 2498842916 Pto2BadCondition 3000;
BA_REL_ "GenSigTimeoutTime" BU_SG_REL_ HMIIOM SG_ 2498842916 Pto2BadCondition 450;
BA_REL_ "GenSigFirstTimeoutTime" BU_SG_REL_ BBM SG_ 2498842916 Pto2BadCondition 3000;
BA_REL_ "GenSigTimeoutTime" BU_SG_REL_ BBM SG_ 2498842916 Pto2BadCondition 450;
BA_REL_ "GenSigFirstTimeoutTime" BU_SG_REL_ EMS SG_ 2498842916 PtoRequest 3000;
BA_REL_ "GenSigTimeoutTime" BU_SG_REL_ EMS SG_ 2498842916 PtoRequest 450;
BA_REL_ "GenSigFirstTimeoutTime" BU_SG_REL_ TECU SG_ 2498842916 Pto2ConsentRequest 3000;
BA_REL_ "GenSigTimeoutTime" BU_SG_REL_ TECU SG_ 2498842916 Pto2ConsentRequest 450;
BA_REL_ "GenSigFirstTimeoutTime" BU_SG_REL_ HMIIOM SG_ 2498842916 PBStatusDisplay_cmd_ISig_4 3000;
BA_REL_ "GenSigTimeoutTime" BU_SG_REL_ HMIIOM SG_ 2498842916 PBStatusDisplay_cmd_ISig_4 450;
BA_REL_ "GenSigFirstTimeoutTime" BU_SG_REL_ BBM SG_ 2498842916 Pto4DrivingRequest 3000;
BA_REL_ "GenSigTimeoutTime" BU_SG_REL_ BBM SG_ 2498842916 Pto4DrivingRequest 450;
BA_REL_ "GenSigFirstTimeoutTime" BU_SG_REL_ CIOM SG_ 2498842916 Pto3Indication 3000;
BA_REL_ "GenSigTimeoutTime" BU_SG_REL_ CIOM SG_ 2498842916 Pto3Indication 450;
BA_REL_ "GenSigFirstTimeoutTime" BU_SG_REL_ HMIIOM SG_ 2498842916 Pto2Status_ISig_4 3000;
BA_REL_ "GenSigTimeoutTime" BU_SG_REL_ HMIIOM SG_ 2498842916 Pto2Status_ISig_4 450;
BA_REL_ "GenSigFirstTimeoutTime" BU_SG_REL_ TECU SG_ 2498842916 Pto2Status_ISig_4 3000;
BA_REL_ "GenSigTimeoutTime" BU_SG_REL_ TECU SG_ 2498842916 Pto2Status_ISig_4 450;
BA_REL_ "GenSigFirstTimeoutTime" BU_SG_REL_ CIOM SG_ 2498842916 Pto2Status_ISig_4 3000;
BA_REL_ "GenSigTimeoutTime" BU_SG_REL_ CIOM SG_ 2498842916 Pto2Status_ISig_4 450;
BA_REL_ "GenSigFirstTimeoutTime" BU_SG_REL_ BBM SG_ 2498842916 Pto2Status_ISig_4 3000;
BA_REL_ "GenSigTimeoutTime" BU_SG_REL_ BBM SG_ 2498842916 Pto2Status_ISig_4 450;
BA_REL_ "GenSigFirstTimeoutTime" BU_SG_REL_ CIOM SG_ 2498842916 Pto4Status_ISig_4 3000;
BA_REL_ "GenSigTimeoutTime" BU_SG_REL_ CIOM SG_ 2498842916 Pto4Status_ISig_4 450;
BA_REL_ "GenSigFirstTimeoutTime" BU_SG_REL_ HMIIOM SG_ 2498842916 Pto4Status_ISig_4 3000;
BA_REL_ "GenSigTimeoutTime" BU_SG_REL_ HMIIOM SG_ 2498842916 Pto4Status_ISig_4 450;
BA_REL_ "GenSigFirstTimeoutTime" BU_SG_REL_ BBM SG_ 2498842916 Pto4Status_ISig_4 3000;
BA_REL_ "GenSigTimeoutTime" BU_SG_REL_ BBM SG_ 2498842916 Pto4Status_ISig_4 450;
BA_REL_ "GenSigFirstTimeoutTime" BU_SG_REL_ CIOM SG_ 2498842916 RampLevelRequestACK_ISig_4 3000;
BA_REL_ "GenSigTimeoutTime" BU_SG_REL_ CIOM SG_ 2498842916 RampLevelRequestACK_ISig_4 450;
BA_REL_ "GenSigFirstTimeoutTime" BU_SG_REL_ HMIIOM SG_ 2498842916 Pto3BadCondition 3000;
BA_REL_ "GenSigTimeoutTime" BU_SG_REL_ HMIIOM SG_ 2498842916 Pto3BadCondition 450;
BA_REL_ "GenSigFirstTimeoutTime" BU_SG_REL_ BBM SG_ 2498842916 Pto3BadCondition 3000;
BA_REL_ "GenSigTimeoutTime" BU_SG_REL_ BBM SG_ 2498842916 Pto3BadCondition 450;
BA_REL_ "GenSigFirstTimeoutTime" BU_SG_REL_ BBM SG_ 2498842916 PtosStatus_ISig_4 3000;
BA_REL_ "GenSigTimeoutTime" BU_SG_REL_ BBM SG_ 2498842916 PtosStatus_ISig_4 600;
BA_REL_ "GenSigFirstTimeoutTime" BU_SG_REL_ CIOM SG_ 2498842916 PtosStatus_ISig_4 3000;
BA_REL_ "GenSigTimeoutTime" BU_SG_REL_ CIOM SG_ 2498842916 PtosStatus_ISig_4 600;
BA_REL_ "GenSigFirstTimeoutTime" BU_SG_REL_ EMS SG_ 2498842916 PtosStatus_ISig_4 3000;
BA_REL_ "GenSigTimeoutTime" BU_SG_REL_ EMS SG_ 2498842916 PtosStatus_ISig_4 600;
BA_REL_ "GenSigFirstTimeoutTime" BU_SG_REL_ HMIIOM SG_ 2498842916 PtosStatus_ISig_4 3000;
BA_REL_ "GenSigTimeoutTime" BU_SG_REL_ HMIIOM SG_ 2498842916 PtosStatus_ISig_4 450;
BA_REL_ "GenSigFirstTimeoutTime" BU_SG_REL_ BBM SG_ 2498842916 FrontWheelDriveAutoStatus_ISig_4 3000;
BA_REL_ "GenSigTimeoutTime" BU_SG_REL_ BBM SG_ 2498842916 FrontWheelDriveAutoStatus_ISig_4 450;
BA_REL_ "GenSigFirstTimeoutTime" BU_SG_REL_ HMIIOM SG_ 2498842916 FrontWheelDriveAutoStatus_ISig_4 3000;
BA_REL_ "GenSigTimeoutTime" BU_SG_REL_ HMIIOM SG_ 2498842916 FrontWheelDriveAutoStatus_ISig_4 450;
BA_REL_ "GenSigFirstTimeoutTime" BU_SG_REL_ TECU SG_ 2498842916 Pto1ConsentRequest 3000;
BA_REL_ "GenSigTimeoutTime" BU_SG_REL_ TECU SG_ 2498842916 Pto1ConsentRequest 450;
BA_REL_ "GenSigFirstTimeoutTime" BU_SG_REL_ CIOM SG_ 2498842916 Pto4Indication 3000;
BA_REL_ "GenSigTimeoutTime" BU_SG_REL_ CIOM SG_ 2498842916 Pto4Indication 450;
BA_REL_ "GenSigFirstTimeoutTime" BU_SG_REL_ CIOM SG_ 2498842916 Pto1Indication 3000;
BA_REL_ "GenSigTimeoutTime" BU_SG_REL_ CIOM SG_ 2498842916 Pto1Indication 450;
BA_REL_ "GenSigFirstTimeoutTime" BU_SG_REL_ BBM SG_ 2498842916 Pto3Status_ISig_4 3000;
BA_REL_ "GenSigTimeoutTime" BU_SG_REL_ BBM SG_ 2498842916 Pto3Status_ISig_4 450;
BA_REL_ "GenSigFirstTimeoutTime" BU_SG_REL_ HMIIOM SG_ 2498842916 Pto3Status_ISig_4 3000;
BA_REL_ "GenSigTimeoutTime" BU_SG_REL_ HMIIOM SG_ 2498842916 Pto3Status_ISig_4 450;
BA_REL_ "GenSigFirstTimeoutTime" BU_SG_REL_ CIOM SG_ 2498842916 Pto3Status_ISig_4 3000;
BA_REL_ "GenSigTimeoutTime" BU_SG_REL_ CIOM SG_ 2498842916 Pto3Status_ISig_4 450;
BA_REL_ "GenSigFirstTimeoutTime" BU_SG_REL_ CIOM SG_ 2498842916 Pto2Indication 3000;
BA_REL_ "GenSigTimeoutTime" BU_SG_REL_ CIOM SG_ 2498842916 Pto2Indication 450;
BA_REL_ "GenSigFirstTimeoutTime" BU_SG_REL_ HMIIOM SG_ 2498842916 Pto1FeedbackStatus_ISig_4 3000;
BA_REL_ "GenSigTimeoutTime" BU_SG_REL_ HMIIOM SG_ 2498842916 Pto1FeedbackStatus_ISig_4 500;
BA_REL_ "GenSigFirstTimeoutTime" BU_SG_REL_ BBM SG_ 2498842916 Pto1FeedbackStatus_ISig_4 3000;
BA_REL_ "GenSigTimeoutTime" BU_SG_REL_ BBM SG_ 2498842916 Pto1FeedbackStatus_ISig_4 500;
BA_REL_ "GenSigFirstTimeoutTime" BU_SG_REL_ TECU SG_ 2498842916 TransferCaseOrSplitboxPTOMode_IS 3000;
BA_REL_ "GenSigTimeoutTime" BU_SG_REL_ TECU SG_ 2498842916 TransferCaseOrSplitboxPTOMode_IS 450;
BA_REL_ "GenSigFirstTimeoutTime" BU_SG_REL_ BBM SG_ 2498842916 TransferCaseOrSplitboxPTOMode_IS 3000;
BA_REL_ "GenSigTimeoutTime" BU_SG_REL_ BBM SG_ 2498842916 TransferCaseOrSplitboxPTOMode_IS 450;
BA_REL_ "GenSigFirstTimeoutTime" BU_SG_REL_ HMIIOM SG_ 2498842916 TransferCaseOrSplitboxPTOMode_IS 3000;
BA_REL_ "GenSigTimeoutTime" BU_SG_REL_ HMIIOM SG_ 2498842916 TransferCaseOrSplitboxPTOMode_IS 450;
BA_REL_ "GenSigFirstTimeoutTime" BU_SG_REL_ HMIIOM SG_ 2498842916 FrontWheelDriveMenuFeedback 3000;
BA_REL_ "GenSigTimeoutTime" BU_SG_REL_ HMIIOM SG_ 2498842916 FrontWheelDriveMenuFeedback 450;
BA_REL_ "GenSigFirstTimeoutTime" BU_SG_REL_ HMIIOM SG_ 2498842916 DirIndRearLamp_Stat_ISig_4 3000;
BA_REL_ "GenSigTimeoutTime" BU_SG_REL_ HMIIOM SG_ 2498842916 DirIndRearLamp_Stat_ISig_4 450;
BA_REL_ "GenSigFirstTimeoutTime" BU_SG_REL_ CIOM SG_ 2498842916 Pto1Status_ISig_4 3000;
BA_REL_ "GenSigTimeoutTime" BU_SG_REL_ CIOM SG_ 2498842916 Pto1Status_ISig_4 450;
BA_REL_ "GenSigFirstTimeoutTime" BU_SG_REL_ TECU SG_ 2498842916 Pto1Status_ISig_4 3000;
BA_REL_ "GenSigTimeoutTime" BU_SG_REL_ TECU SG_ 2498842916 Pto1Status_ISig_4 450;
BA_REL_ "GenSigFirstTimeoutTime" BU_SG_REL_ BBM SG_ 2498842916 Pto1Status_ISig_4 3000;
BA_REL_ "GenSigTimeoutTime" BU_SG_REL_ BBM SG_ 2498842916 Pto1Status_ISig_4 450;
BA_REL_ "GenSigFirstTimeoutTime" BU_SG_REL_ HMIIOM SG_ 2498842916 Pto1Status_ISig_4 3000;
BA_REL_ "GenSigTimeoutTime" BU_SG_REL_ HMIIOM SG_ 2498842916 Pto1Status_ISig_4 450;
BA_REL_ "GenSigFirstTimeoutTime" BU_SG_REL_ BBM SG_ 2498842916 Pto3DrivingRequest 3000;
BA_REL_ "GenSigTimeoutTime" BU_SG_REL_ BBM SG_ 2498842916 Pto3DrivingRequest 450;
BA_REL_ "GenSigFirstTimeoutTime" BU_SG_REL_ EMS SG_ 2466224932 CCBTargetSpeedRequest 3000;
BA_REL_ "GenSigTimeoutTime" BU_SG_REL_ EMS SG_ 2466224932 CCBTargetSpeedRequest 270;
BA_REL_ "GenSigFirstTimeoutTime" BU_SG_REL_ TECU SG_ 2466224932 CCBTargetSpeedRequest 3000;
BA_REL_ "GenSigTimeoutTime" BU_SG_REL_ TECU SG_ 2466224932 CCBTargetSpeedRequest 270;
BA_REL_ "GenSigFirstTimeoutTime" BU_SG_REL_ HMIIOM SG_ 2466224932 EngineStartControlStatus_ISig_4 3000;
BA_REL_ "GenSigTimeoutTime" BU_SG_REL_ HMIIOM SG_ 2466224932 EngineStartControlStatus_ISig_4 270;
BA_REL_ "GenSigFirstTimeoutTime" BU_SG_REL_ BBM SG_ 2466224932 EngineStartControlStatus_ISig_4 3000;
BA_REL_ "GenSigTimeoutTime" BU_SG_REL_ BBM SG_ 2466224932 EngineStartControlStatus_ISig_4 270;
BA_REL_ "GenSigFirstTimeoutTime" BU_SG_REL_ VGGSECUSystem SG_ 2466224932 EngineStartControlStatus_ISig_4 3000;
BA_REL_ "GenSigTimeoutTime" BU_SG_REL_ VGGSECUSystem SG_ 2466224932 EngineStartControlStatus_ISig_4 270;
BA_REL_ "GenSigFirstTimeoutTime" BU_SG_REL_ TECU SG_ 2466224932 CCTargetSpeedRequest 3000;
BA_REL_ "GenSigTimeoutTime" BU_SG_REL_ TECU SG_ 2466224932 CCTargetSpeedRequest 270;
BA_REL_ "GenSigFirstTimeoutTime" BU_SG_REL_ EMS SG_ 2466224932 CCTargetSpeedRequest 3000;
BA_REL_ "GenSigTimeoutTime" BU_SG_REL_ EMS SG_ 2466224932 CCTargetSpeedRequest 270;
BA_REL_ "GenSigFirstTimeoutTime" BU_SG_REL_ HMIIOM SG_ 2466210596 StoreIdleValue_ISig_4 3000;
BA_REL_ "GenSigTimeoutTime" BU_SG_REL_ HMIIOM SG_ 2466210596 StoreIdleValue_ISig_4 270;
BA_REL_ "GenSigFirstTimeoutTime" BU_SG_REL_ EMS SG_ 2466210596 StoreIdleValue_ISig_4 3000;
BA_REL_ "GenSigTimeoutTime" BU_SG_REL_ EMS SG_ 2466210596 StoreIdleValue_ISig_4 270;
BA_REL_ "GenSigFirstTimeoutTime" BU_SG_REL_ HMIIOM SG_ 2466210596 EngSpdCtrlBadConditions_ISig_4 3000;
BA_REL_ "GenSigTimeoutTime" BU_SG_REL_ HMIIOM SG_ 2466210596 EngSpdCtrlBadConditions_ISig_4 270;
BA_REL_ "GenSigFirstTimeoutTime" BU_SG_REL_ VGGSECUSystem SG_ 2466210596 EngSpdCtrlBadConditions_ISig_4 3000;
BA_REL_ "GenSigTimeoutTime" BU_SG_REL_ VGGSECUSystem SG_ 2466210596 EngSpdCtrlBadConditions_ISig_4 270;
BA_REL_ "GenSigFirstTimeoutTime" BU_SG_REL_ HMIIOM SG_ 2466210596 CrossCountryBadConditions 3000;
BA_REL_ "GenSigTimeoutTime" BU_SG_REL_ HMIIOM SG_ 2466210596 CrossCountryBadConditions 270;
BA_REL_ "GenSigFirstTimeoutTime" BU_SG_REL_ EMS SG_ 2466210596 ESCReqEMS_CtrlTrimMode_ISig_4 3000;
BA_REL_ "GenSigTimeoutTime" BU_SG_REL_ EMS SG_ 2466210596 ESCReqEMS_CtrlTrimMode_ISig_4 270;
BA_REL_ "GenSigFirstTimeoutTime" BU_SG_REL_ TECU SG_ 2466210596 ESCReqEMS_CtrlTrimMode_ISig_4 3000;
BA_REL_ "GenSigTimeoutTime" BU_SG_REL_ TECU SG_ 2466210596 ESCReqEMS_CtrlTrimMode_ISig_4 300;
BA_REL_ "GenSigFirstTimeoutTime" BU_SG_REL_ HMIIOM SG_ 2466210596 ESCReqEMS_CtrlTrimMode_ISig_4 3000;
BA_REL_ "GenSigTimeoutTime" BU_SG_REL_ HMIIOM SG_ 2466210596 ESCReqEMS_CtrlTrimMode_ISig_4 270;
BA_REL_ "GenSigFirstTimeoutTime" BU_SG_REL_ CIOM SG_ 2466210596 ESCReqESC_CtrlTrimMode_ISig_4 3000;
BA_REL_ "GenSigTimeoutTime" BU_SG_REL_ CIOM SG_ 2466210596 ESCReqESC_CtrlTrimMode_ISig_4 270;
BA_REL_ "GenSigFirstTimeoutTime" BU_SG_REL_ HMIIOM SG_ 2466210596 ESCReqESC_CtrlTrimMode_ISig_4 3000;
BA_REL_ "GenSigTimeoutTime" BU_SG_REL_ HMIIOM SG_ 2466210596 ESCReqESC_CtrlTrimMode_ISig_4 270;
BA_REL_ "GenSigFirstTimeoutTime" BU_SG_REL_ BBM SG_ 2466210596 ESCReqESC_CtrlTrimMode_ISig_4 3000;
BA_REL_ "GenSigTimeoutTime" BU_SG_REL_ BBM SG_ 2466210596 ESCReqESC_CtrlTrimMode_ISig_4 270;
BA_REL_ "GenSigFirstTimeoutTime" BU_SG_REL_ VGGSECUSystem SG_ 2466210596 ESCReqESC_CtrlTrimMode_ISig_4 3000;
BA_REL_ "GenSigTimeoutTime" BU_SG_REL_ VGGSECUSystem SG_ 2466210596 ESCReqESC_CtrlTrimMode_ISig_4 270;
BA_REL_ "GenSigFirstTimeoutTime" BU_SG_REL_ HMIIOM SG_ 2466210596 IdleAdjustConditionStatus 3000;
BA_REL_ "GenSigTimeoutTime" BU_SG_REL_ HMIIOM SG_ 2466210596 IdleAdjustConditionStatus 270;
BA_REL_ "GenSigFirstTimeoutTime" BU_SG_REL_ HMIIOM SG_ 2466210596 StopProhibitStatus_ISig_4 3000;
BA_REL_ "GenSigTimeoutTime" BU_SG_REL_ HMIIOM SG_ 2466210596 StopProhibitStatus_ISig_4 270;
BA_REL_ "GenSigFirstTimeoutTime" BU_SG_REL_ BBM SG_ 2466210596 StopProhibitStatus_ISig_4 3000;
BA_REL_ "GenSigTimeoutTime" BU_SG_REL_ BBM SG_ 2466210596 StopProhibitStatus_ISig_4 270;
BA_REL_ "GenSigFirstTimeoutTime" BU_SG_REL_ HMIIOM SG_ 2466210596 ESCReqEMS_CtrlTrimStat_ISig_4 3000;
BA_REL_ "GenSigTimeoutTime" BU_SG_REL_ HMIIOM SG_ 2466210596 ESCReqEMS_CtrlTrimStat_ISig_4 270;
BA_REL_ "GenSigFirstTimeoutTime" BU_SG_REL_ EMS SG_ 2466210596 ESCReqEMS_CtrlTrimStat_ISig_4 3000;
BA_REL_ "GenSigTimeoutTime" BU_SG_REL_ EMS SG_ 2466210596 ESCReqEMS_CtrlTrimStat_ISig_4 270;
BA_REL_ "GenSigFirstTimeoutTime" BU_SG_REL_ TECU SG_ 2466210596 ESCReqEMS_CtrlTrimStat_ISig_4 3000;
BA_REL_ "GenSigTimeoutTime" BU_SG_REL_ TECU SG_ 2466210596 ESCReqEMS_CtrlTrimStat_ISig_4 300;
BA_REL_ "GenSigFirstTimeoutTime" BU_SG_REL_ TECU SG_ 2466210596 TrailerConnected_ISig_4 3000;
BA_REL_ "GenSigTimeoutTime" BU_SG_REL_ TECU SG_ 2466210596 TrailerConnected_ISig_4 500;
BA_REL_ "GenSigFirstTimeoutTime" BU_SG_REL_ HMIIOM SG_ 2466210596 TrailerConnected_ISig_4 3000;
BA_REL_ "GenSigTimeoutTime" BU_SG_REL_ HMIIOM SG_ 2466210596 TrailerConnected_ISig_4 500;
BA_REL_ "GenSigFirstTimeoutTime" BU_SG_REL_ EMS SG_ 2466210596 TrailerConnected_ISig_4 3000;
BA_REL_ "GenSigTimeoutTime" BU_SG_REL_ EMS SG_ 2466210596 TrailerConnected_ISig_4 500;
BA_REL_ "GenSigFirstTimeoutTime" BU_SG_REL_ DACU SG_ 2466210596 TrailerConnected_ISig_4 3000;
BA_REL_ "GenSigTimeoutTime" BU_SG_REL_ DACU SG_ 2466210596 TrailerConnected_ISig_4 500;
BA_REL_ "GenSigFirstTimeoutTime" BU_SG_REL_ BBM SG_ 2466210596 TrailerConnected_ISig_4 3000;
BA_REL_ "GenSigTimeoutTime" BU_SG_REL_ BBM SG_ 2466210596 TrailerConnected_ISig_4 500;
BA_REL_ "GenSigFirstTimeoutTime" BU_SG_REL_ VGGSECUSystem SG_ 2466210596 ESCReqESC_CtrlTrimValue_ISig_4 3000;
BA_REL_ "GenSigTimeoutTime" BU_SG_REL_ VGGSECUSystem SG_ 2466210596 ESCReqESC_CtrlTrimValue_ISig_4 270;
BA_REL_ "GenSigFirstTimeoutTime" BU_SG_REL_ BBM SG_ 2466210596 ESCReqESC_CtrlTrimValue_ISig_4 3000;
BA_REL_ "GenSigTimeoutTime" BU_SG_REL_ BBM SG_ 2466210596 ESCReqESC_CtrlTrimValue_ISig_4 270;
BA_REL_ "GenSigFirstTimeoutTime" BU_SG_REL_ HMIIOM SG_ 2466210596 ESCReqESC_CtrlTrimValue_ISig_4 3000;
BA_REL_ "GenSigTimeoutTime" BU_SG_REL_ HMIIOM SG_ 2466210596 ESCReqESC_CtrlTrimValue_ISig_4 270;
BA_REL_ "GenSigFirstTimeoutTime" BU_SG_REL_ CIOM SG_ 2466210596 ESCReqESC_CtrlTrimValue_ISig_4 3000;
BA_REL_ "GenSigTimeoutTime" BU_SG_REL_ CIOM SG_ 2466210596 ESCReqESC_CtrlTrimValue_ISig_4 270;
BA_REL_ "GenSigFirstTimeoutTime" BU_SG_REL_ CIOM SG_ 2466210596 ESCReqESC_CtrlTrimStat_ISig_4 3000;
BA_REL_ "GenSigTimeoutTime" BU_SG_REL_ CIOM SG_ 2466210596 ESCReqESC_CtrlTrimStat_ISig_4 270;
BA_REL_ "GenSigFirstTimeoutTime" BU_SG_REL_ BBM SG_ 2466210596 ESCReqESC_CtrlTrimStat_ISig_4 3000;
BA_REL_ "GenSigTimeoutTime" BU_SG_REL_ BBM SG_ 2466210596 ESCReqESC_CtrlTrimStat_ISig_4 270;
BA_REL_ "GenSigFirstTimeoutTime" BU_SG_REL_ HMIIOM SG_ 2466210596 ESCReqESC_CtrlTrimStat_ISig_4 3000;
BA_REL_ "GenSigTimeoutTime" BU_SG_REL_ HMIIOM SG_ 2466210596 ESCReqESC_CtrlTrimStat_ISig_4 270;
BA_REL_ "GenSigFirstTimeoutTime" BU_SG_REL_ VGGSECUSystem SG_ 2466210596 ESCReqESC_CtrlTrimStat_ISig_4 3000;
BA_REL_ "GenSigTimeoutTime" BU_SG_REL_ VGGSECUSystem SG_ 2466210596 ESCReqESC_CtrlTrimStat_ISig_4 270;
BA_REL_ "GenSigFirstTimeoutTime" BU_SG_REL_ CIOM SG_ 2466210596 SCLLogicEnable_rqst 3000;
BA_REL_ "GenSigTimeoutTime" BU_SG_REL_ CIOM SG_ 2466210596 SCLLogicEnable_rqst 270;
BA_REL_ "GenSigFirstTimeoutTime" BU_SG_REL_ HMIIOM SG_ 2466210596 ESCReqESC_CtrlTrimReq_ISig_4 3000;
BA_REL_ "GenSigTimeoutTime" BU_SG_REL_ HMIIOM SG_ 2466210596 ESCReqESC_CtrlTrimReq_ISig_4 270;
BA_REL_ "GenSigFirstTimeoutTime" BU_SG_REL_ CIOM SG_ 2466210596 ESCReqESC_CtrlTrimReq_ISig_4 3000;
BA_REL_ "GenSigTimeoutTime" BU_SG_REL_ CIOM SG_ 2466210596 ESCReqESC_CtrlTrimReq_ISig_4 270;
BA_REL_ "GenSigFirstTimeoutTime" BU_SG_REL_ BBM SG_ 2466210596 ESCReqESC_CtrlTrimReq_ISig_4 3000;
BA_REL_ "GenSigTimeoutTime" BU_SG_REL_ BBM SG_ 2466210596 ESCReqESC_CtrlTrimReq_ISig_4 270;
BA_REL_ "GenSigFirstTimeoutTime" BU_SG_REL_ VGGSECUSystem SG_ 2466210596 ESCReqESC_CtrlTrimReq_ISig_4 3000;
BA_REL_ "GenSigTimeoutTime" BU_SG_REL_ VGGSECUSystem SG_ 2466210596 ESCReqESC_CtrlTrimReq_ISig_4 270;
BA_REL_ "GenSigFirstTimeoutTime" BU_SG_REL_ BBM SG_ 2466210596 BrakeLight_rqst_ISig_4 3000;
BA_REL_ "GenSigTimeoutTime" BU_SG_REL_ BBM SG_ 2466210596 BrakeLight_rqst_ISig_4 500;
BA_REL_ "GenSigFirstTimeoutTime" BU_SG_REL_ HMIIOM SG_ 2466210596 ESCReqEMS_CtrlTrimValue_ISig_4 3000;
BA_REL_ "GenSigTimeoutTime" BU_SG_REL_ HMIIOM SG_ 2466210596 ESCReqEMS_CtrlTrimValue_ISig_4 270;
BA_REL_ "GenSigFirstTimeoutTime" BU_SG_REL_ TECU SG_ 2466210596 ESCReqEMS_CtrlTrimValue_ISig_4 3000;
BA_REL_ "GenSigTimeoutTime" BU_SG_REL_ TECU SG_ 2466210596 ESCReqEMS_CtrlTrimValue_ISig_4 300;
BA_REL_ "GenSigFirstTimeoutTime" BU_SG_REL_ EMS SG_ 2466210596 ESCReqEMS_CtrlTrimValue_ISig_4 3000;
BA_REL_ "GenSigTimeoutTime" BU_SG_REL_ EMS SG_ 2466210596 ESCReqEMS_CtrlTrimValue_ISig_4 270;
BA_REL_ "GenSigFirstTimeoutTime" BU_SG_REL_ HMIIOM SG_ 2466210596 ESCReqEMS_CtrlTrimReq_ISig_4 3000;
BA_REL_ "GenSigTimeoutTime" BU_SG_REL_ HMIIOM SG_ 2466210596 ESCReqEMS_CtrlTrimReq_ISig_4 270;
BA_REL_ "GenSigFirstTimeoutTime" BU_SG_REL_ TECU SG_ 2466210596 ESCReqEMS_CtrlTrimReq_ISig_4 3000;
BA_REL_ "GenSigTimeoutTime" BU_SG_REL_ TECU SG_ 2466210596 ESCReqEMS_CtrlTrimReq_ISig_4 300;
BA_REL_ "GenSigFirstTimeoutTime" BU_SG_REL_ EMS SG_ 2466210596 ESCReqEMS_CtrlTrimReq_ISig_4 3000;
BA_REL_ "GenSigTimeoutTime" BU_SG_REL_ EMS SG_ 2466210596 ESCReqEMS_CtrlTrimReq_ISig_4 270;
BA_REL_ "GenSigFirstTimeoutTime" BU_SG_REL_ VGGSECUSystem SG_ 2466196004 TrailerTest_stat 3000;
BA_REL_ "GenSigTimeoutTime" BU_SG_REL_ VGGSECUSystem SG_ 2466196004 TrailerTest_stat 270;
BA_REL_ "GenSigFirstTimeoutTime" BU_SG_REL_ HMIIOM SG_ 2466196004 TrailerTest_stat 3000;
BA_REL_ "GenSigTimeoutTime" BU_SG_REL_ HMIIOM SG_ 2466196004 TrailerTest_stat 270;
BA_REL_ "GenSigFirstTimeoutTime" BU_SG_REL_ CIOM SG_ 2466196004 Washing_HMI_rqst_ISig_4 3000;
BA_REL_ "GenSigTimeoutTime" BU_SG_REL_ CIOM SG_ 2466196004 Washing_HMI_rqst_ISig_4 270;
BA_REL_ "GenSigFirstTimeoutTime" BU_SG_REL_ HMIIOM SG_ 2466196004 AuxBrakesDwngrdModeInd_rqst_ISig 3000;
BA_REL_ "GenSigTimeoutTime" BU_SG_REL_ HMIIOM SG_ 2466196004 AuxBrakesDwngrdModeInd_rqst_ISig 270;
BA_REL_ "GenSigFirstTimeoutTime" BU_SG_REL_ VGGSECUSystem SG_ 2466196004 AuxBrakesDwngrdModeInd_rqst_ISig 3000;
BA_REL_ "GenSigTimeoutTime" BU_SG_REL_ VGGSECUSystem SG_ 2466196004 AuxBrakesDwngrdModeInd_rqst_ISig 270;
BA_REL_ "GenSigFirstTimeoutTime" BU_SG_REL_ EMS SG_ 2466196004 XRSLTargetSpeedRequest 3000;
BA_REL_ "GenSigTimeoutTime" BU_SG_REL_ EMS SG_ 2466196004 XRSLTargetSpeedRequest 270;
BA_REL_ "GenSigFirstTimeoutTime" BU_SG_REL_ DACU SG_ 2466196004 XPRsystemstate_ISig_4 3000;
BA_REL_ "GenSigTimeoutTime" BU_SG_REL_ DACU SG_ 2466196004 XPRsystemstate_ISig_4 270;
BA_REL_ "GenSigFirstTimeoutTime" BU_SG_REL_ BBM SG_ 2466196004 XPRsystemstate_ISig_4 3000;
BA_REL_ "GenSigTimeoutTime" BU_SG_REL_ BBM SG_ 2466196004 XPRsystemstate_ISig_4 270;
BA_REL_ "GenSigFirstTimeoutTime" BU_SG_REL_ CIOM SG_ 2466196004 KeyAuthentication_rqst 3000;
BA_REL_ "GenSigTimeoutTime" BU_SG_REL_ CIOM SG_ 2466196004 KeyAuthentication_rqst 270;
BA_REL_ "GenSigFirstTimeoutTime" BU_SG_REL_ CIOM SG_ 2466196004 EngineSpeedControlStatus_ISig_4 3000;
BA_REL_ "GenSigTimeoutTime" BU_SG_REL_ CIOM SG_ 2466196004 EngineSpeedControlStatus_ISig_4 270;
BA_REL_ "GenSigFirstTimeoutTime" BU_SG_REL_ HMIIOM SG_ 2466196004 EngineSpeedControlStatus_ISig_4 3000;
BA_REL_ "GenSigTimeoutTime" BU_SG_REL_ HMIIOM SG_ 2466196004 EngineSpeedControlStatus_ISig_4 270;
BA_REL_ "GenSigFirstTimeoutTime" BU_SG_REL_ BBM SG_ 2466196004 EngineSpeedControlStatus_ISig_4 3000;
BA_REL_ "GenSigTimeoutTime" BU_SG_REL_ BBM SG_ 2466196004 EngineSpeedControlStatus_ISig_4 270;
BA_REL_ "GenSigFirstTimeoutTime" BU_SG_REL_ VGGSECUSystem SG_ 2466196004 EngineSpeedControlStatus_ISig_4 3000;
BA_REL_ "GenSigTimeoutTime" BU_SG_REL_ VGGSECUSystem SG_ 2466196004 EngineSpeedControlStatus_ISig_4 270;
BA_REL_ "GenSigFirstTimeoutTime" BU_SG_REL_ HMIIOM SG_ 2466196004 EngineSpeedLimitReached 3000;
BA_REL_ "GenSigTimeoutTime" BU_SG_REL_ HMIIOM SG_ 2466196004 EngineSpeedLimitReached 270;
BA_REL_ "GenSigFirstTimeoutTime" BU_SG_REL_ EMS SG_ 2466196004 SecondThrottle 3000;
BA_REL_ "GenSigTimeoutTime" BU_SG_REL_ EMS SG_ 2466196004 SecondThrottle 270;
BA_REL_ "GenSigFirstTimeoutTime" BU_SG_REL_ DACU SG_ 2466196004 SecondThrottle 3000;
BA_REL_ "GenSigTimeoutTime" BU_SG_REL_ DACU SG_ 2466196004 SecondThrottle 270;
BA_REL_ "GenSigFirstTimeoutTime" BU_SG_REL_ HMIIOM SG_ 2466196004 PredeliveryModeIndication_cmd_IS 3000;
BA_REL_ "GenSigTimeoutTime" BU_SG_REL_ HMIIOM SG_ 2466196004 PredeliveryModeIndication_cmd_IS 270;
BA_REL_ "GenSigFirstTimeoutTime" BU_SG_REL_ CIOM SG_ 2466196004 PredeliveryModeIndication_cmd_IS 3000;
BA_REL_ "GenSigTimeoutTime" BU_SG_REL_ CIOM SG_ 2466196004 PredeliveryModeIndication_cmd_IS 270;
BA_REL_ "GenSigFirstTimeoutTime" BU_SG_REL_ HMIIOM SG_ 2466196004 LoadCutOffIndication_cmd_ISig_4 3000;
BA_REL_ "GenSigTimeoutTime" BU_SG_REL_ HMIIOM SG_ 2466196004 LoadCutOffIndication_cmd_ISig_4 270;
BA_REL_ "GenSigFirstTimeoutTime" BU_SG_REL_ HMIIOM SG_ 2466196004 AutoPBRelease_stat_ISig_4 3000;
BA_REL_ "GenSigTimeoutTime" BU_SG_REL_ HMIIOM SG_ 2466196004 AutoPBRelease_stat_ISig_4 270;
BA_REL_ "GenSigFirstTimeoutTime" BU_SG_REL_ HMIIOM SG_ 2466196004 AutoParkBrakeActvnInhibd_stat_IS 3000;
BA_REL_ "GenSigTimeoutTime" BU_SG_REL_ HMIIOM SG_ 2466196004 AutoParkBrakeActvnInhibd_stat_IS 270;
BA_REL_ "GenSigFirstTimeoutTime" BU_SG_REL_ DACU SG_ 2466196004 WiperParkStatus_Global_ISig_4 3000;
BA_REL_ "GenSigTimeoutTime" BU_SG_REL_ DACU SG_ 2466196004 WiperParkStatus_Global_ISig_4 500;
BA_REL_ "GenSigFirstTimeoutTime" BU_SG_REL_ CIOM SG_ 2466196004 ExitPreDeliveryModeHMI_rqst_ISig 3000;
BA_REL_ "GenSigTimeoutTime" BU_SG_REL_ CIOM SG_ 2466196004 ExitPreDeliveryModeHMI_rqst_ISig 270;
BA_REL_ "GenSigFirstTimeoutTime" BU_SG_REL_ BBM SG_ 2466196004 FdEquipmentStatus1_ISig_4 3000;
BA_REL_ "GenSigTimeoutTime" BU_SG_REL_ BBM SG_ 2466196004 FdEquipmentStatus1_ISig_4 270;
BA_REL_ "GenSigFirstTimeoutTime" BU_SG_REL_ HMIIOM SG_ 2466196004 FdEquipmentStatus1_ISig_4 3000;
BA_REL_ "GenSigTimeoutTime" BU_SG_REL_ HMIIOM SG_ 2466196004 FdEquipmentStatus1_ISig_4 270;
BA_REL_ "GenSigFirstTimeoutTime" BU_SG_REL_ CIOM SG_ 2466196004 FdEquipmentStatus1_ISig_4 3000;
BA_REL_ "GenSigTimeoutTime" BU_SG_REL_ CIOM SG_ 2466196004 FdEquipmentStatus1_ISig_4 270;
BA_REL_ "GenSigFirstTimeoutTime" BU_SG_REL_ HMIIOM SG_ 2432649764 ParkBrakeAlert_ISig_4 3000;
BA_REL_ "GenSigTimeoutTime" BU_SG_REL_ HMIIOM SG_ 2432649764 ParkBrakeAlert_ISig_4 150;
BA_REL_ "GenSigFirstTimeoutTime" BU_SG_REL_ HMIIOM SG_ 2432649764 IntLightMode_CoreRqst_IL_Mode 3000;
BA_REL_ "GenSigTimeoutTime" BU_SG_REL_ HMIIOM SG_ 2432649764 IntLightMode_CoreRqst_IL_Mode 150;
BA_REL_ "GenSigFirstTimeoutTime" BU_SG_REL_ CIOM SG_ 2432649764 IntLightMode_CoreRqst_IL_Mode 6000;
BA_REL_ "GenSigTimeoutTime" BU_SG_REL_ CIOM SG_ 2432649764 IntLightMode_CoreRqst_IL_Mode 6000;
BA_REL_ "GenSigFirstTimeoutTime" BU_SG_REL_ HMIIOM SG_ 2432649764 SteeringColumnLockErrInd_rqst 3000;
BA_REL_ "GenSigTimeoutTime" BU_SG_REL_ HMIIOM SG_ 2432649764 SteeringColumnLockErrInd_rqst 150;
BA_REL_ "GenSigFirstTimeoutTime" BU_SG_REL_ HMIIOM SG_ 2432649764 MainBeamIndication_cmd 3000;
BA_REL_ "GenSigTimeoutTime" BU_SG_REL_ HMIIOM SG_ 2432649764 MainBeamIndication_cmd 150;
BA_REL_ "GenSigFirstTimeoutTime" BU_SG_REL_ HMIIOM SG_ 2432649764 PosLightWarning_rqst 3000;
BA_REL_ "GenSigTimeoutTime" BU_SG_REL_ HMIIOM SG_ 2432649764 PosLightWarning_rqst 150;
BA_REL_ "GenSigFirstTimeoutTime" BU_SG_REL_ HMIIOM SG_ 2432649764 RainsensorActivationHMI_stat 3000;
BA_REL_ "GenSigTimeoutTime" BU_SG_REL_ HMIIOM SG_ 2432649764 RainsensorActivationHMI_stat 150;
BA_REL_ "GenSigFirstTimeoutTime" BU_SG_REL_ HMIIOM SG_ 2432649764 FogLight_Front_Indication_Cmd 3000;
BA_REL_ "GenSigTimeoutTime" BU_SG_REL_ HMIIOM SG_ 2432649764 FogLight_Front_Indication_Cmd 150;
BA_REL_ "GenSigFirstTimeoutTime" BU_SG_REL_ CIOM SG_ 2432649764 ParkingLight_Indication 6000;
BA_REL_ "GenSigTimeoutTime" BU_SG_REL_ CIOM SG_ 2432649764 ParkingLight_Indication 6000;
BA_REL_ "GenSigFirstTimeoutTime" BU_SG_REL_ CIOM SG_ 2432649764 DaytimeRunningLight_Indication 3000;
BA_REL_ "GenSigTimeoutTime" BU_SG_REL_ CIOM SG_ 2432649764 DaytimeRunningLight_Indication 1000;
BA_REL_ "GenSigFirstTimeoutTime" BU_SG_REL_ HMIIOM SG_ 2432649764 EPBBackupMode_ISig_4 3000;
BA_REL_ "GenSigTimeoutTime" BU_SG_REL_ HMIIOM SG_ 2432649764 EPBBackupMode_ISig_4 150;
BA_REL_ "GenSigFirstTimeoutTime" BU_SG_REL_ CIOM SG_ 2432649764 WiperModeStatus_ISig_4 3000;
BA_REL_ "GenSigTimeoutTime" BU_SG_REL_ CIOM SG_ 2432649764 WiperModeStatus_ISig_4 500;
BA_REL_ "GenSigFirstTimeoutTime" BU_SG_REL_ DACU SG_ 2432649764 WiperModeStatus_ISig_4 3000;
BA_REL_ "GenSigTimeoutTime" BU_SG_REL_ DACU SG_ 2432649764 WiperModeStatus_ISig_4 500;
BA_REL_ "GenSigFirstTimeoutTime" BU_SG_REL_ CIOM SG_ 2432649764 FrontFog_Indication 6000;
BA_REL_ "GenSigTimeoutTime" BU_SG_REL_ CIOM SG_ 2432649764 FrontFog_Indication 6000;
BA_REL_ "GenSigFirstTimeoutTime" BU_SG_REL_ HMIIOM SG_ 2432649764 PBReleaseAcceptance_stat_ISig_4 3000;
BA_REL_ "GenSigTimeoutTime" BU_SG_REL_ HMIIOM SG_ 2432649764 PBReleaseAcceptance_stat_ISig_4 150;
BA_REL_ "GenSigFirstTimeoutTime" BU_SG_REL_ CIOM SG_ 2432649764 DrivingLightPlus_Indication 6000;
BA_REL_ "GenSigTimeoutTime" BU_SG_REL_ CIOM SG_ 2432649764 DrivingLightPlus_Indication 6000;
BA_REL_ "GenSigFirstTimeoutTime" BU_SG_REL_ CIOM SG_ 2432649764 IntLightMode_CoreRqst_EventFlag 6000;
BA_REL_ "GenSigTimeoutTime" BU_SG_REL_ CIOM SG_ 2432649764 IntLightMode_CoreRqst_EventFlag 6000;
BA_REL_ "GenSigFirstTimeoutTime" BU_SG_REL_ HMIIOM SG_ 2432649764 IntLightMode_CoreRqst_EventFlag 3000;
BA_REL_ "GenSigTimeoutTime" BU_SG_REL_ HMIIOM SG_ 2432649764 IntLightMode_CoreRqst_EventFlag 150;
BA_REL_ "GenSigFirstTimeoutTime" BU_SG_REL_ EMS SG_ 2432649764 ParkingBrake_stat_ISig_4 3000;
BA_REL_ "GenSigTimeoutTime" BU_SG_REL_ EMS SG_ 2432649764 ParkingBrake_stat_ISig_4 500;
BA_REL_ "GenSigFirstTimeoutTime" BU_SG_REL_ HMIIOM SG_ 2432649764 ParkingBrake_stat_ISig_4 3000;
BA_REL_ "GenSigTimeoutTime" BU_SG_REL_ HMIIOM SG_ 2432649764 ParkingBrake_stat_ISig_4 500;
BA_REL_ "GenSigFirstTimeoutTime" BU_SG_REL_ VGGSECUSystem SG_ 2432649764 ParkingBrake_stat_ISig_4 3000;
BA_REL_ "GenSigTimeoutTime" BU_SG_REL_ VGGSECUSystem SG_ 2432649764 ParkingBrake_stat_ISig_4 150;
BA_REL_ "GenSigFirstTimeoutTime" BU_SG_REL_ CIOM SG_ 2432649764 ParkingBrake_stat_ISig_4 3000;
BA_REL_ "GenSigTimeoutTime" BU_SG_REL_ CIOM SG_ 2432649764 ParkingBrake_stat_ISig_4 500;
BA_REL_ "GenSigFirstTimeoutTime" BU_SG_REL_ BBM SG_ 2432649764 ParkingBrake_stat_ISig_4 3000;
BA_REL_ "GenSigTimeoutTime" BU_SG_REL_ BBM SG_ 2432649764 ParkingBrake_stat_ISig_4 500;
BA_REL_ "GenSigFirstTimeoutTime" BU_SG_REL_ TECU SG_ 2432649764 ParkingBrake_stat_ISig_4 3000;
BA_REL_ "GenSigTimeoutTime" BU_SG_REL_ TECU SG_ 2432649764 ParkingBrake_stat_ISig_4 500;
BA_REL_ "GenSigFirstTimeoutTime" BU_SG_REL_ CIOM SG_ 2432649764 DrivingLight_Indication 6000;
BA_REL_ "GenSigTimeoutTime" BU_SG_REL_ CIOM SG_ 2432649764 DrivingLight_Indication 6000;
BA_REL_ "GenSigFirstTimeoutTime" BU_SG_REL_ HMIIOM SG_ 2432649764 Rainsensor_Indication 3000;
BA_REL_ "GenSigTimeoutTime" BU_SG_REL_ HMIIOM SG_ 2432649764 Rainsensor_Indication 150;
BA_REL_ "GenSigFirstTimeoutTime" BU_SG_REL_ HMIIOM SG_ 2432649764 DippedBeamIndication_cmd 3000;
BA_REL_ "GenSigTimeoutTime" BU_SG_REL_ HMIIOM SG_ 2432649764 DippedBeamIndication_cmd 150;
BA_REL_ "GenSigFirstTimeoutTime" BU_SG_REL_ CIOM SG_ 2432649764 MirrorHeatingMode_ISig_4 6000;
BA_REL_ "GenSigTimeoutTime" BU_SG_REL_ CIOM SG_ 2432649764 MirrorHeatingMode_ISig_4 6000;
BA_REL_ "GenSigFirstTimeoutTime" BU_SG_REL_ CIOM SG_ 2432649764 RearFog_Indication 6000;
BA_REL_ "GenSigTimeoutTime" BU_SG_REL_ CIOM SG_ 2432649764 RearFog_Indication 6000;
BA_REL_ "GenSigFirstTimeoutTime" BU_SG_REL_ CIOM SG_ 2432649764 InteriorLightLevelInd_cmd 6000;
BA_REL_ "GenSigTimeoutTime" BU_SG_REL_ CIOM SG_ 2432649764 InteriorLightLevelInd_cmd 6000;
BA_REL_ "GenSigFirstTimeoutTime" BU_SG_REL_ HMIIOM SG_ 2432649764 FogLight_Rear_Indication_Cmd 3000;
BA_REL_ "GenSigTimeoutTime" BU_SG_REL_ HMIIOM SG_ 2432649764 FogLight_Rear_Indication_Cmd 150;
BA_REL_ "GenSigFirstTimeoutTime" BU_SG_REL_ HMIIOM SG_ 2432649764 PosLight_Indication_Cmd 3000;
BA_REL_ "GenSigTimeoutTime" BU_SG_REL_ HMIIOM SG_ 2432649764 PosLight_Indication_Cmd 150;
BA_REL_ "GenSigFirstTimeoutTime" BU_SG_REL_ HMIIOM SG_ 2432649764 DirIndicationTimeoutInd_rqst 3000;
BA_REL_ "GenSigTimeoutTime" BU_SG_REL_ HMIIOM SG_ 2432649764 DirIndicationTimeoutInd_rqst 150;
VAL_ 2549401380 StaticCornerLightLamp_stat_ISig_ 7 "LampCheckLeftRight_stat_NotAvailable" 6 "LampCheckLeftRight_stat_Error" 5 "LampCheckLeftRight_stat_Spare" 4 "LampCheckLeftRight_stat_TestedLeftAndRightLampNOK" 3 "LampCheckLeftRight_stat_TestedRightLampNOK" 2 "LampCheckLeftRight_stat_TestedLeftLampNOK" 1 "LampCheckLeftRight_stat_TestedLampOK" 0 "LampCheckLeftRight_stat_NotTested" ;
VAL_ 2549401380 DRLLamp_stat_ISig_4 7 "LampCheckLeftRight_stat_NotAvailable" 6 "LampCheckLeftRight_stat_Error" 5 "LampCheckLeftRight_stat_Spare" 4 "LampCheckLeftRight_stat_TestedLeftAndRightLampNOK" 3 "LampCheckLeftRight_stat_TestedRightLampNOK" 2 "LampCheckLeftRight_stat_TestedLeftLampNOK" 1 "LampCheckLeftRight_stat_TestedLampOK" 0 "LampCheckLeftRight_stat_NotTested" ;
VAL_ 2549401380 DirInd_Front_Status_ISig_4 7 "DirIndFaultStatus_NotAvailable" 6 "DirIndFaultStatus_Error" 5 "DirIndFaultStatus_SpareValue_01" 4 "DirIndFaultStatus_SpareValue" 3 "DirIndFaultStatus_BothLeftAndRightDirectionIndicatorsFault" 2 "DirIndFaultStatus_RightDirectionIndicatorLampFault" 1 "DirIndFaultStatus_LeftDirectionIndicatorLampFault" 0 "DirIndFaultStatus_NoError" ;
VAL_ 2549401380 DirInd_Rear_Status_ISig_4 7 "DirIndFaultStatus_NotAvailable" 6 "DirIndFaultStatus_Error" 5 "DirIndFaultStatus_SpareValue_01" 4 "DirIndFaultStatus_SpareValue" 3 "DirIndFaultStatus_BothLeftAndRightDirectionIndicatorsFault" 2 "DirIndFaultStatus_RightDirectionIndicatorLampFault" 1 "DirIndFaultStatus_LeftDirectionIndicatorLampFault" 0 "DirIndFaultStatus_NoError" ;
VAL_ 2549401380 ChassiInstepLightsLamp_stat_ISig 7 "LampCheck_stat_NotAvailable" 6 "LampCheck_stat_Error" 5 "LampCheck_stat_Spare_02" 4 "LampCheck_stat_Spare_01" 3 "LampCheck_stat_Spare" 2 "LampCheck_stat_TestedLampNOK" 1 "LampCheck_stat_TestedLampOK" 0 "LampCheck_stat_NotTested" ;
VAL_ 2549401380 PositionLightLamp_stat_ISig_4 7 "LampCheckLeftRight_stat_NotAvailable" 6 "LampCheckLeftRight_stat_Error" 5 "LampCheckLeftRight_stat_Spare" 4 "LampCheckLeftRight_stat_TestedLeftAndRightLampNOK" 3 "LampCheckLeftRight_stat_TestedRightLampNOK" 2 "LampCheckLeftRight_stat_TestedLeftLampNOK" 1 "LampCheckLeftRight_stat_TestedLampOK" 0 "LampCheckLeftRight_stat_NotTested" ;
VAL_ 2549401380 MainBeamLamp_stat_ISig_4 7 "LampCheckLeftRight_stat_NotAvailable" 6 "LampCheckLeftRight_stat_Error" 5 "LampCheckLeftRight_stat_Spare" 4 "LampCheckLeftRight_stat_TestedLeftAndRightLampNOK" 3 "LampCheckLeftRight_stat_TestedRightLampNOK" 2 "LampCheckLeftRight_stat_TestedLeftLampNOK" 1 "LampCheckLeftRight_stat_TestedLampOK" 0 "LampCheckLeftRight_stat_NotTested" ;
VAL_ 2549401380 BrakeLightLamp_stat_ISig_4 7 "LampCheckLeftRight_stat_NotAvailable" 6 "LampCheckLeftRight_stat_Error" 5 "LampCheckLeftRight_stat_Spare" 4 "LampCheckLeftRight_stat_TestedLeftAndRightLampNOK" 3 "LampCheckLeftRight_stat_TestedRightLampNOK" 2 "LampCheckLeftRight_stat_TestedLeftLampNOK" 1 "LampCheckLeftRight_stat_TestedLampOK" 0 "LampCheckLeftRight_stat_NotTested" ;
VAL_ 2549401380 TrailerConnectionStatus_ISig_4 3 "Error1_NotAvailable" 2 "Error1_Spare" 1 "Error1_Error" 0 "Error1_NoError" ;
VAL_ 2549401380 RevLightLamp_stat_ISig_4 7 "LampCheckLeftRight_stat_NotAvailable" 6 "LampCheckLeftRight_stat_Error" 5 "LampCheckLeftRight_stat_Spare" 4 "LampCheckLeftRight_stat_TestedLeftAndRightLampNOK" 3 "LampCheckLeftRight_stat_TestedRightLampNOK" 2 "LampCheckLeftRight_stat_TestedLeftLampNOK" 1 "LampCheckLeftRight_stat_TestedLampOK" 0 "LampCheckLeftRight_stat_NotTested" ;
VAL_ 2549401380 AuxFogLightLamp_stat_ISig_4 7 "LampCheckLeftRight_stat_NotAvailable" 6 "LampCheckLeftRight_stat_Error" 5 "LampCheckLeftRight_stat_Spare" 4 "LampCheckLeftRight_stat_TestedLeftAndRightLampNOK" 3 "LampCheckLeftRight_stat_TestedRightLampNOK" 2 "LampCheckLeftRight_stat_TestedLeftLampNOK" 1 "LampCheckLeftRight_stat_TestedLampOK" 0 "LampCheckLeftRight_stat_NotTested" ;
VAL_ 2549401380 DirIndSideLamp_stat 7 "LampCheckLeftRight_stat_NotAvailable" 6 "LampCheckLeftRight_stat_Error" 5 "LampCheckLeftRight_stat_Spare" 4 "LampCheckLeftRight_stat_TestedLeftAndRightLampNOK" 3 "LampCheckLeftRight_stat_TestedRightLampNOK" 2 "LampCheckLeftRight_stat_TestedLeftLampNOK" 1 "LampCheckLeftRight_stat_TestedLampOK" 0 "LampCheckLeftRight_stat_NotTested" ;
VAL_ 2549401380 ExtraMainBeamLamp_stat_ISig_4 7 "LampCheckLeftRight_stat_NotAvailable" 6 "LampCheckLeftRight_stat_Error" 5 "LampCheckLeftRight_stat_Spare" 4 "LampCheckLeftRight_stat_TestedLeftAndRightLampNOK" 3 "LampCheckLeftRight_stat_TestedRightLampNOK" 2 "LampCheckLeftRight_stat_TestedLeftLampNOK" 1 "LampCheckLeftRight_stat_TestedLampOK" 0 "LampCheckLeftRight_stat_NotTested" ;
VAL_ 2549401380 FogLightFrontLamp_stat_ISig_4 7 "LampCheck_stat_NotAvailable" 6 "LampCheck_stat_Error" 5 "LampCheck_stat_Spare_02" 4 "LampCheck_stat_Spare_01" 3 "LampCheck_stat_Spare" 2 "LampCheck_stat_TestedLampNOK" 1 "LampCheck_stat_TestedLampOK" 0 "LampCheck_stat_NotTested" ;
VAL_ 2549401380 DippedBeamLamp_stat_ISig_4 7 "LampCheckLeftRight_stat_NotAvailable" 6 "LampCheckLeftRight_stat_Error" 5 "LampCheckLeftRight_stat_Spare" 4 "LampCheckLeftRight_stat_TestedLeftAndRightLampNOK" 3 "LampCheckLeftRight_stat_TestedRightLampNOK" 2 "LampCheckLeftRight_stat_TestedLeftLampNOK" 1 "LampCheckLeftRight_stat_TestedLampOK" 0 "LampCheckLeftRight_stat_NotTested" ;
VAL_ 2549401380 FogLightRearLamp_stat_ISig_4 7 "LampCheck_stat_NotAvailable" 6 "LampCheck_stat_Error" 5 "LampCheck_stat_Spare_02" 4 "LampCheck_stat_Spare_01" 3 "LampCheck_stat_Spare" 2 "LampCheck_stat_TestedLampNOK" 1 "LampCheck_stat_TestedLampOK" 0 "LampCheck_stat_NotTested" ;
VAL_ 2481980708 StartupProhibitStatus_ISig_4 3 "InactiveActive_NotAvailable" 2 "InactiveActive_Error" 1 "InactiveActive_Active" 0 "InactiveActive_Inactive" ;
VAL_ 2481980708 LoadDistributionReasonChanged_IS 7 "LoadDistributionReasonChanged_NotAvailable" 6 "LoadDistributionReasonChanged_Error" 5 "LoadDistributionReasonChanged_Spare3" 4 "LoadDistributionReasonChanged_Spare2" 3 "LoadDistributionReasonChanged_Spare1" 2 "LoadDistributionReasonChanged_SystemForced" 1 "LoadDistributionReasonChanged_UserForced" 0 "LoadDistributionReasonChanged_NoUnexpectedReason" ;
VAL_ 2481980708 RampLevelStatus_ISig_4 15 "RampLevelStatus_NotAvaiable" 14 "RampLevelStatus_ErrorIndicator" 13 "RampLevelStatus_NotDefined_05" 12 "RampLevelStatus_NotDefined_04" 11 "RampLevelStatus_NotDefined_03" 10 "RampLevelStatus_NotDefined_02" 9 "RampLevelStatus_NotDefined_01" 8 "RampLevelStatus_NotDefined" 7 "RampLevelStatus_RampLevelM7" 6 "RampLevelStatus_RampLevelM6" 5 "RampLevelStatus_RampLevelM5" 4 "RampLevelStatus_RampLevelM4" 3 "RampLevelStatus_RampLevelM3" 2 "RampLevelStatus_RampLevelM2" 1 "RampLevelStatus_RampLevelM1" 0 "RampLevelStatus_Inactive" ;
VAL_ 2481980708 KneelingInformation_ISig_4 15 "KneelingInformation_NotAvailable" 14 "KneelingInformation_ErrorIndicator" 13 "KneelingInformation_NotDefined_08" 12 "KneelingInformation_NotDefined_07" 11 "KneelingInformation_NotDefined_06" 10 "KneelingInformation_NotDefined_05" 9 "KneelingInformation_NotDefined_04" 8 "KneelingInformation_NotDefined_03" 7 "KneelingInformation_NotDefined_02" 6 "KneelingInformation_NotDefined_01" 5 "KneelingInformation_NotDefined" 4 "KneelingInformation_KneelingAborted" 3 "KneelingInformation_LiftingActiveVehicleIsLiftedDueToRcvrReq" 2 "KneelingInformation_KneelLevelReachedVehicleIsAtFixeKneelLvl" 1 "KneelingInformation_LoweringActiveTheVehIsLoweredDueToKneelReq" 0 "KneelingInformation_NotActiveTheKneelingFunctionIsNotActive" ;
VAL_ 2481980708 FrontAxleInBumperRange_ISig_4 3 "AxleInBumperRange_NotAvailable" 2 "AxleInBumperRange_ErrorIndicator" 1 "AxleInBumperRange_ActualLevelWithinBumperRange" 0 "AxleInBumperRange_ActualLevelOutOfBumperRange" ;
VAL_ 2481980708 FerryFunctionStatus_ISig_4 7 "FerryFunctionStatus_NotAvailable" 6 "FerryFunctionStatus_Error" 5 "FerryFunctionStatus_Spare_03" 4 "FerryFunctionStatus_Spare_02" 3 "FerryFunctionStatus_Spare_01" 2 "FerryFunctionStatus_FerryFunctionActiveLeveNotlReached" 1 "FerryFunctionStatus_FerryFunctionActiveLevelReached" 0 "FerryFunctionStatus_FerryFunctionNotActive" ;
VAL_ 2481980708 EngPtoConsumesTorque 3 "PtoTorqueRequest_NotAvailable" 2 "PtoTorqueRequest_Error" 1 "PtoTorqueRequest_PtoIsRequestingHighTorque" 0 "PtoTorqueRequest_PtoIsNotRequestingHighTorque" ;
VAL_ 2481980708 LiftingControlModeRearAxle_ISig_ 3 "InactiveActive_NotAvailable" 2 "InactiveActive_Error" 1 "InactiveActive_Active" 0 "InactiveActive_Inactive" ;
VAL_ 2481980708 KneelingStatusHMI_ISig_4 3 "KneelingStatusHMI_NotAvailable" 2 "KneelingStatusHMI_Error" 1 "KneelingStatusHMI_Active" 0 "KneelingStatusHMI_Inactive" ;
VAL_ 2481980708 SWEngineStop_rqst_ISig_4 7 "SWEngineStop_rqst_NotAvailable" 6 "SWEngineStop_rqst_Error" 5 "SWEngineStop_rqst_Spare_04" 4 "SWEngineStop_rqst_Spare_03" 3 "SWEngineStop_rqst_Spare_02" 2 "SWEngineStop_rqst_Spare_01" 1 "SWEngineStop_rqst_EngineStopRequested" 0 "SWEngineStop_rqst_EngineStopNotRequested" ;
VAL_ 2481980708 FrontEndPositionStatus_ISig_4 7 "EndPositionStatus_NotAvailable" 6 "EndPositionStatus_Error" 5 "EndPositionStatus_Reserved_01" 4 "EndPositionStatus_Reserved" 3 "EndPositionStatus_LiftingAndLoweringNotAllowed" 2 "EndPositionStatus_MinEndLevelReached" 1 "EndPositionStatus_MaxEndLevelReached" 0 "EndPositionStatus_NoEndLevelReached" ;
VAL_ 2481980708 LiftingControlModeFrontAxle_ISig 3 "InactiveActive_NotAvailable" 2 "InactiveActive_Error" 1 "InactiveActive_Active" 0 "InactiveActive_Inactive" ;
VAL_ 2481980708 UnevenLoadWarning_ISig_4 3 "Warning_NotAvailable" 2 "Warning_Error" 1 "Warning_Warning" 0 "Warning_NoWarning" ;
VAL_ 2481980708 RampHeightOutsideTargetRange_ISi 7 "HeightOutsideTargetRange_NotAvailable" 6 "HeightOutsideTargetRange_Error" 5 "HeightOutsideTargetRange_NotDefined_02" 4 "HeightOutsideTargetRange_NotDefined_01" 3 "HeightOutsideTargetRange_NotDefined" 2 "HeightOutsideTargetRange_ToHigh" 1 "HeightOutsideTargetRange_ToLow" 0 "HeightOutsideTargetRange_Inactive" ;
VAL_ 2481980708 DriveLevelPosUserInteraction_ISi 7 "DriveLevelPosUserInteraction_NotAvailable" 6 "DriveLevelPosUserInteraction_Error" 5 "DriveLevelPosUserInteraction_Spare3" 4 "DriveLevelPosUserInteraction_Spare2" 3 "DriveLevelPosUserInteraction_Spare1" 2 "DriveLevelPosUserInteraction_WarningDriveLevelPosNotSelected" 1 "DriveLevelPosUserInteraction_DriveLevelPositionNotSelected" 0 "DriveLevelPosUserInteraction_DriveLevelPositionSelected" ;
VAL_ 2481980708 RearEndPositionStatus_ISig_4 7 "EndPositionStatus_NotAvailable" 6 "EndPositionStatus_Error" 5 "EndPositionStatus_Reserved_01" 4 "EndPositionStatus_Reserved" 3 "EndPositionStatus_LiftingAndLoweringNotAllowed" 2 "EndPositionStatus_MinEndLevelReached" 1 "EndPositionStatus_MaxEndLevelReached" 0 "EndPositionStatus_NoEndLevelReached" ;
VAL_ 2481980708 ProhibitControlStatus_ISig_4 3 "InactiveActive_NotAvailable" 2 "InactiveActive_Error" 1 "InactiveActive_Active" 0 "InactiveActive_Inactive" ;
VAL_ 2481980708 ChangeKneelACK_ISig_4 3 "ChangeKneelACK_NotAvailable" 2 "ChangeKneelACK_Error" 1 "ChangeKneelACK_ChangeAcknowledged" 0 "ChangeKneelACK_NoAction" ;
VAL_ 2481980708 RollEndPositionStatus_ISig_4 7 "RollEndPositionStatus_NotAvailable" 6 "RollEndPositionStatus_Error" 5 "RollEndPositionStatus_Reserved_01" 4 "RollEndPositionStatus_Reserved" 3 "RollEndPositionStatus_NoRollingAllowed" 2 "RollEndPositionStatus_CounterClockwiseEndLevelReached" 1 "RollEndPositionStatus_ClockwiseEndLevelReached" 0 "RollEndPositionStatus_NoEndLevelReached" ;
VAL_ 2481980708 TransferCaseBadCondition 7 "TransferCaseBadCondition_NotAvailable" 6 "TransferCaseBadCondition_Error" 5 "TransferCaseBadCondition_Spare3" 4 "TransferCaseBadCondition_Spare2" 3 "TransferCaseBadCondition_Spare1" 2 "TransferCaseBadCondition_GearboxNetrualConditionNotMet" 1 "TransferCaseBadCondition_ParkBrakeConditionNotMet" 0 "TransferCaseBadCondition_EntryConditionMet" ;
VAL_ 2481980708 ECSStandbyAllowed_ISig_4 3 "FalseTrue_NotAvaiable" 2 "FalseTrue_Error" 1 "FalseTrue_True" 0 "FalseTrue_False" ;
VAL_ 2481980708 RearAxleInBumperRange_ISig_4 3 "AxleInBumperRange_NotAvailable" 2 "AxleInBumperRange_ErrorIndicator" 1 "AxleInBumperRange_ActualLevelWithinBumperRange" 0 "AxleInBumperRange_ActualLevelOutOfBumperRange" ;
VAL_ 2549579812 RefrigTimer_rqst_DayOfWeekRq 15 "DayOfWeekRq_NotAvailable" 14 "DayOfWeekRq_Error" 13 "DayOfWeekRq_Spare_7" 12 "DayOfWeekRq_Spare_6" 11 "DayOfWeekRq_Spare_5" 10 "DayOfWeekRq_Spare_4" 9 "DayOfWeekRq_Spare_3" 8 "DayOfWeekRq_Spare_2" 7 "DayOfWeekRq_NoDay" 6 "DayOfWeekRq_Sunday" 5 "DayOfWeekRq_Saturday" 4 "DayOfWeekRq_Friday" 3 "DayOfWeekRq_Thursday" 2 "DayOfWeekRq_Wednesday" 1 "DayOfWeekRq_Tuesday" 0 "DayOfWeekRq_Monday" ;
VAL_ 2549579812 RSLAssistStatus 7 "RSLAssistStatus_NotAvailable" 6 "RSLAssistStatus_Error" 5 "RSLAssistStatus_Spare2" 4 "RSLAssistStatus_Spare1" 3 "RSLAssistStatus_PreActive" 2 "RSLAssistStatus_Active" 1 "RSLAssistStatus_Enable" 0 "RSLAssistStatus_Disable" ;
VAL_ 2549579812 RefrigTimer_rqst_SetAlarmOper 7 "SetAlarmOperation_NotAvailable" 6 "SetAlarmOperation_Error" 5 "SetAlarmOperation_Spare_02" 4 "SetAlarmOperation_Spare_01" 3 "SetAlarmOperation_Reset" 2 "SetAlarmOperation_Continue" 1 "SetAlarmOperation_Stop" 0 "SetAlarmOperation_Start" ;
VAL_ 2566559268 WasherFluidLevel_ISig_4 7 "WasherFluidLevel_NotAvailable" 6 "WasherFluidLevel_ErrorIndicator" 5 "WasherFluidLevel_Spare_02" 4 "WasherFluidLevel_Spare_01" 3 "WasherFluidLevel_Spare" 2 "WasherFluidLevel_Level2" 1 "WasherFluidLevel_Level1" 0 "WasherFluidLevel_Level0" ;
VAL_ 2566559268 EngSpeedGreenAreaMode_ISig_4 7 "EngSpeedGreenAreaMode_NotAvailable" 6 "EngSpeedGreenAreaMode_Error" 5 "EngSpeedGreenAreaMode_Spare3" 4 "EngSpeedGreenAreaMode_Spare2" 3 "EngSpeedGreenAreaMode_Spare1" 2 "EngSpeedGreenAreaMode_Above" 1 "EngSpeedGreenAreaMode_Within" 0 "EngSpeedGreenAreaMode_Below" ;
VAL_ 2515721252 CabRoofSignLightFeedback_stat 3 "OffOn_NotAvailable" 2 "OffOn_Error" 1 "OffOn_On" 0 "OffOn_Off" ;
VAL_ 2515721252 TemporaryRSLStatus 3 "InactiveActive_NotAvailable" 2 "InactiveActive_Error" 1 "InactiveActive_Active" 0 "InactiveActive_Inactive" ;
VAL_ 2515721252 CabExtraSideWrknLightFdbk_stat_I 3 "OffOn_NotAvailable" 2 "OffOn_Error" 1 "OffOn_On" 0 "OffOn_Off" ;
VAL_ 2515721252 CabWrknLightChassisFdbk_stat_ISi 3 "OffOn_NotAvailable" 2 "OffOn_Error" 1 "OffOn_On" 0 "OffOn_Off" ;
VAL_ 2515721252 HeadLightLevelRequest_stat 31 "HeadLightLevelRequest_stat_NotAvailable" 30 "HeadLightLevelRequest_stat_Error" 29 "HeadLightLevelRequest_stat_Spare14" 28 "HeadLightLevelRequest_stat_Spare13" 27 "HeadLightLevelRequest_stat_Spare12" 26 "HeadLightLevelRequest_stat_Spare11" 25 "HeadLightLevelRequest_stat_Spare10" 24 "HeadLightLevelRequest_stat_Spare09" 23 "HeadLightLevelRequest_stat_Spare08" 22 "HeadLightLevelRequest_stat_Spare07" 21 "HeadLightLevelRequest_stat_Spare06" 20 "HeadLightLevelRequest_stat_Spare05" 19 "HeadLightLevelRequest_stat_Spare04" 18 "HeadLightLevelRequest_stat_Spare03" 17 "HeadLightLevelRequest_stat_Spare02" 16 "HeadLightLevelRequest_stat_Spare01" 15 "HeadLightLevelRequest_stat_Level7Pos" 14 "HeadLightLevelRequest_stat_Level6Pos" 13 "HeadLightLevelRequest_stat_Level5Pos" 12 "HeadLightLevelRequest_stat_Level4Pos" 11 "HeadLightLevelRequest_stat_Level3Pos" 10 "HeadLightLevelRequest_stat_Level2Pos" 9 "HeadLightLevelRequest_stat_Level1Pos" 8 "HeadLightLevelRequest_stat_Level0" 7 "HeadLightLevelRequest_stat_Level1Neg" 6 "HeadLightLevelRequest_stat_Level2Neg" 5 "HeadLightLevelRequest_stat_Level3Neg" 4 "HeadLightLevelRequest_stat_Level4Neg" 3 "HeadLightLevelRequest_stat_Level5Neg" 2 "HeadLightLevelRequest_stat_Level6Neg" 1 "HeadLightLevelRequest_stat_Level7Neg" 0 "HeadLightLevelRequest_stat_NoIndication" ;
VAL_ 2515721252 CabTrailerBodyLgthnFdbk_stat 3 "OffOn_NotAvailable" 2 "OffOn_Error" 1 "OffOn_On" 0 "OffOn_Off" ;
VAL_ 2515721252 DiffLockInterWhlStatusSplitBox_I 3 "DisengageEngage_NotAvailable" 2 "DisengageEngage_Error" 1 "DisengageEngage_Engage" 0 "DisengageEngage_Disengage" ;
VAL_ 2515721252 BodyOrCabWorkingLightFdbk_stat_I 3 "OffOn_NotAvailable" 2 "OffOn_Error" 1 "OffOn_On" 0 "OffOn_Off" ;
VAL_ 2515721252 CabFrontSpotFeedback_Status 3 "OffOn_NotAvailable" 2 "OffOn_Error" 1 "OffOn_On" 0 "OffOn_Off" ;
VAL_ 2515721252 CabTiltEnableStatus 3 "DisableEnable_NotAvailable" 2 "DisableEnable_Error" 1 "DisableEnable_Enable" 0 "DisableEnable_Disable" ;
VAL_ 2515721252 TransmReverseDirectionSw_stat_IS 3 "OffOn_NotAvailable" 2 "OffOn_Error" 1 "OffOn_On" 0 "OffOn_Off" ;
VAL_ 2515721252 CabRoofSpotFeedback_Status 3 "OffOn_NotAvailable" 2 "OffOn_Error" 1 "OffOn_On" 0 "OffOn_Off" ;
VAL_ 2515721252 CabBeaconLightFeedback_Status_IS 3 "OffOn_NotAvailable" 2 "OffOn_Error" 1 "OffOn_On" 0 "OffOn_Off" ;
VAL_ 2515721252 ExtraAxleSteeringFunctionStat_IS 7 "RearAxleSteeringFunctionStatus_NotAvailable" 6 "RearAxleSteeringFunctionStatus_Error" 5 "RearAxleSteeringFunctionStatus_SpareValue_01" 4 "RearAxleSteeringFunctionStatus_SpareValue" 3 "RearAxleSteeringFunctionStatus_ActiveFailureMode" 2 "RearAxleSteeringFunctionStatus_PassiveFailureMode" 1 "RearAxleSteeringFunctionStatus_Active" 0 "RearAxleSteeringFunctionStatus_NotActive" ;
VAL_ 2515721252 CabTiltLockStatus_ISig_4 3 "UnlockedLocked_NotAvailable" 2 "UnlockedLocked_Error" 1 "UnlockedLocked_Locked" 0 "UnlockedLocked_Unlocked" ;
VAL_ 2515721252 PositionLightRearLamp_stat_ISig_ 7 "LampCheckLeftRight_stat_NotAvailable" 6 "LampCheckLeftRight_stat_Error" 5 "LampCheckLeftRight_stat_Spare" 4 "LampCheckLeftRight_stat_TestedLeftAndRightLampNOK" 3 "LampCheckLeftRight_stat_TestedRightLampNOK" 2 "LampCheckLeftRight_stat_TestedLeftLampNOK" 1 "LampCheckLeftRight_stat_TestedLampOK" 0 "LampCheckLeftRight_stat_NotTested" ;
VAL_ 2498842916 Pto1BadCondition_ISig_4 15 "PtoBadCondition_NotAvailable" 14 "PtoBadCondition_Error" 13 "PtoBadCondition_Spare_02" 12 "PtoBadCondition_TransferBoxNotInNeutral" 11 "PtoBadCondition_CrossCountryAlreadyactive" 10 "PtoBadCondition_AirPressureTooLow" 9 "PtoBadCondition_WrongGearSplitSelected" 8 "PtoBadCondition_ClutchPedalNotPressed" 7 "PtoBadCondition_ServiceBrakeNotApplied" 6 "PtoBadCondition_ParkbrakeNotActive" 5 "PtoBadCondition_VehicleSpeedTooHigh" 4 "PtoBadCondition_EngineSpeedTooLow" 3 "PtoBadCondition_EngineSpeedTooHigh" 2 "PtoBadCondition_GearboxNotInNeutral" 1 "PtoBadCondition_BadConditionsForEngagementGeneric" 0 "PtoBadCondition_NoBadConditionForEngagement" ;
VAL_ 2498842916 Pto4BadCondition 15 "PtoBadCondition_NotAvailable" 14 "PtoBadCondition_Error" 13 "PtoBadCondition_Spare_02" 12 "PtoBadCondition_TransferBoxNotInNeutral" 11 "PtoBadCondition_CrossCountryAlreadyactive" 10 "PtoBadCondition_AirPressureTooLow" 9 "PtoBadCondition_WrongGearSplitSelected" 8 "PtoBadCondition_ClutchPedalNotPressed" 7 "PtoBadCondition_ServiceBrakeNotApplied" 6 "PtoBadCondition_ParkbrakeNotActive" 5 "PtoBadCondition_VehicleSpeedTooHigh" 4 "PtoBadCondition_EngineSpeedTooLow" 3 "PtoBadCondition_EngineSpeedTooHigh" 2 "PtoBadCondition_GearboxNotInNeutral" 1 "PtoBadCondition_BadConditionsForEngagementGeneric" 0 "PtoBadCondition_NoBadConditionForEngagement" ;
VAL_ 2498842916 Pto2BadCondition 15 "PtoBadCondition_NotAvailable" 14 "PtoBadCondition_Error" 13 "PtoBadCondition_Spare_02" 12 "PtoBadCondition_TransferBoxNotInNeutral" 11 "PtoBadCondition_CrossCountryAlreadyactive" 10 "PtoBadCondition_AirPressureTooLow" 9 "PtoBadCondition_WrongGearSplitSelected" 8 "PtoBadCondition_ClutchPedalNotPressed" 7 "PtoBadCondition_ServiceBrakeNotApplied" 6 "PtoBadCondition_ParkbrakeNotActive" 5 "PtoBadCondition_VehicleSpeedTooHigh" 4 "PtoBadCondition_EngineSpeedTooLow" 3 "PtoBadCondition_EngineSpeedTooHigh" 2 "PtoBadCondition_GearboxNotInNeutral" 1 "PtoBadCondition_BadConditionsForEngagementGeneric" 0 "PtoBadCondition_NoBadConditionForEngagement" ;
VAL_ 2498842916 PtoRequest 3 "InactiveActive_NotAvailable" 2 "InactiveActive_Error" 1 "InactiveActive_Active" 0 "InactiveActive_Inactive" ;
VAL_ 2498842916 Pto2ConsentRequest 3 "PtoConsentRequest_NotAvailable" 2 "PtoConsentRequest_Error" 1 "PtoConsentRequest_PTOOperationDesired" 0 "PtoConsentRequest_PTOOperationNotDesired" ;
VAL_ 2498842916 PBStatusDisplay_cmd_ISig_4 3 "DisableEnable_NotAvailable" 2 "DisableEnable_Error" 1 "DisableEnable_Enable" 0 "DisableEnable_Disable" ;
VAL_ 2498842916 Pto4DrivingRequest 3 "OffOn_NotAvailable" 2 "OffOn_Error" 1 "OffOn_On" 0 "OffOn_Off" ;
VAL_ 2498842916 Pto3Indication 3 "Request_NotAvailable" 2 "Request_Error" 1 "Request_RequestActive" 0 "Request_NotRequested" ;
VAL_ 2498842916 Pto2Status_ISig_4 3 "InactiveActive_NotAvailable" 2 "InactiveActive_Error" 1 "InactiveActive_Active" 0 "InactiveActive_Inactive" ;
VAL_ 2498842916 Pto4Status_ISig_4 3 "InactiveActive_NotAvailable" 2 "InactiveActive_Error" 1 "InactiveActive_Active" 0 "InactiveActive_Inactive" ;
VAL_ 2498842916 RampLevelRequestACK_ISig_4 3 "ChangeRequest2Bit_NotAvailable" 2 "ChangeRequest2Bit_Error" 1 "ChangeRequest2Bit_Change" 0 "ChangeRequest2Bit_TakeNoAction" ;
VAL_ 2498842916 Pto3BadCondition 15 "PtoBadCondition_NotAvailable" 14 "PtoBadCondition_Error" 13 "PtoBadCondition_Spare_02" 12 "PtoBadCondition_TransferBoxNotInNeutral" 11 "PtoBadCondition_CrossCountryAlreadyactive" 10 "PtoBadCondition_AirPressureTooLow" 9 "PtoBadCondition_WrongGearSplitSelected" 8 "PtoBadCondition_ClutchPedalNotPressed" 7 "PtoBadCondition_ServiceBrakeNotApplied" 6 "PtoBadCondition_ParkbrakeNotActive" 5 "PtoBadCondition_VehicleSpeedTooHigh" 4 "PtoBadCondition_EngineSpeedTooLow" 3 "PtoBadCondition_EngineSpeedTooHigh" 2 "PtoBadCondition_GearboxNotInNeutral" 1 "PtoBadCondition_BadConditionsForEngagementGeneric" 0 "PtoBadCondition_NoBadConditionForEngagement" ;
VAL_ 2498842916 PtosStatus_ISig_4 3 "PtosStatus_NotAvailable" 2 "PtosStatus_Error" 1 "PtosStatus_OneOrMorePTOEngaged" 0 "PtosStatus_NoPTOEngaged" ;
VAL_ 2498842916 FrontWheelDriveAutoStatus_ISig_4 3 "OffAutomatic_NotAvailable" 2 "OffAutomatic_Error" 1 "OffAutomatic_Automatic" 0 "OffAutomatic_Off" ;
VAL_ 2498842916 Pto1ConsentRequest 3 "PtoConsentRequest_NotAvailable" 2 "PtoConsentRequest_Error" 1 "PtoConsentRequest_PTOOperationDesired" 0 "PtoConsentRequest_PTOOperationNotDesired" ;
VAL_ 2498842916 Pto4Indication 3 "Request_NotAvailable" 2 "Request_Error" 1 "Request_RequestActive" 0 "Request_NotRequested" ;
VAL_ 2498842916 Pto1Indication 3 "Request_NotAvailable" 2 "Request_Error" 1 "Request_RequestActive" 0 "Request_NotRequested" ;
VAL_ 2498842916 Pto3Status_ISig_4 3 "InactiveActive_NotAvailable" 2 "InactiveActive_Error" 1 "InactiveActive_Active" 0 "InactiveActive_Inactive" ;
VAL_ 2498842916 Pto2Indication 3 "Request_NotAvailable" 2 "Request_Error" 1 "Request_RequestActive" 0 "Request_NotRequested" ;
VAL_ 2498842916 Pto1FeedbackStatus_ISig_4 3 "OffOn_NotAvailable" 2 "OffOn_Error" 1 "OffOn_On" 0 "OffOn_Off" ;
VAL_ 2498842916 TransferCaseOrSplitboxPTOMode_IS 3 "InactiveActive_NotAvailable" 2 "InactiveActive_Error" 1 "InactiveActive_Active" 0 "InactiveActive_Inactive" ;
VAL_ 2498842916 FrontWheelDriveMenuFeedback 3 "OffOn_NotAvailable" 2 "OffOn_Error" 1 "OffOn_On" 0 "OffOn_Off" ;
VAL_ 2498842916 DirIndRearLamp_Stat_ISig_4 7 "LampCheckLeftRight_stat_NotAvailable" 6 "LampCheckLeftRight_stat_Error" 5 "LampCheckLeftRight_stat_Spare" 4 "LampCheckLeftRight_stat_TestedLeftAndRightLampNOK" 3 "LampCheckLeftRight_stat_TestedRightLampNOK" 2 "LampCheckLeftRight_stat_TestedLeftLampNOK" 1 "LampCheckLeftRight_stat_TestedLampOK" 0 "LampCheckLeftRight_stat_NotTested" ;
VAL_ 2498842916 Pto1Status_ISig_4 3 "InactiveActive_NotAvailable" 2 "InactiveActive_Error" 1 "InactiveActive_Active" 0 "InactiveActive_Inactive" ;
VAL_ 2498842916 Pto3DrivingRequest 3 "OffOn_NotAvailable" 2 "OffOn_Error" 1 "OffOn_On" 0 "OffOn_Off" ;
VAL_ 2466210596 StoreIdleValue_ISig_4 3 "StoreIdleValue_NotAvailable" 2 "StoreIdleValue_Error" 1 "StoreIdleValue_StoreSetValue" 0 "StoreIdleValue_DoNOTStoreValue" ;
VAL_ 2466210596 EngSpdCtrlBadConditions_ISig_4 31 "EngSpdCtrlBadConditions_NotAvailable" 30 "EngSpdCtrlBadConditions_Error" 29 "EngSpdCtrlBadConditions_Spare_16" 28 "EngSpdCtrlBadConditions_Spare_15" 27 "EngSpdCtrlBadConditions_Spare_14" 26 "EngSpdCtrlBadConditions_Spare_13" 25 "EngSpdCtrlBadConditions_Spare_12" 24 "EngSpdCtrlBadConditions_Spare_11" 23 "EngSpdCtrlBadConditions_Spare_10" 22 "EngSpdCtrlBadConditions_Spare_09" 21 "EngSpdCtrlBadConditions_Spare_08" 20 "EngSpdCtrlBadConditions_Spare_07" 19 "EngSpdCtrlBadConditions_Spare_06" 18 "EngSpdCtrlBadConditions_Spare_05" 17 "EngSpdCtrlBadConditions_Spare_04" 16 "EngSpdCtrlBadConditions_Spare_03" 15 "EngSpdCtrlBadConditions_Spare_02" 14 "EngSpdCtrlBadConditions_Spare_01" 13 "EngSpdCtrlBadConditions_Spare" 12 "EngSpdCtrlBadConditions_IdleAdjustmentAlreadyActive" 11 "EngSpdCtrlBadConditions_CrossCountryAlreadyActive" 10 "EngSpdCtrlBadConditions_CruiseControlAlreadyActive" 9 "EngSpdCtrlBadConditions_WrongGearSplitSelected" 8 "EngSpdCtrlBadConditions_ClutchPedalNotPressed" 7 "EngSpdCtrlBadConditions_ServiceBrakeNotApplied" 6 "EngSpdCtrlBadConditions_ParkBrakeNotActive" 5 "EngSpdCtrlBadConditions_VehicleSpeedTooHigh" 4 "EngSpdCtrlBadConditions_EngineSpeedTooHigh" 3 "EngSpdCtrlBadConditions_EngineSpeedTooLow" 2 "EngSpdCtrlBadConditions_GearboxNotInNeutral" 1 "EngSpdCtrlBadConditions_OtherConditionNotMet" 0 "EngSpdCtrlBadConditions_None" ;
VAL_ 2466210596 CrossCountryBadConditions 31 "EngSpdCtrlBadConditions_NotAvailable" 30 "EngSpdCtrlBadConditions_Error" 29 "EngSpdCtrlBadConditions_Spare_16" 28 "EngSpdCtrlBadConditions_Spare_15" 27 "EngSpdCtrlBadConditions_Spare_14" 26 "EngSpdCtrlBadConditions_Spare_13" 25 "EngSpdCtrlBadConditions_Spare_12" 24 "EngSpdCtrlBadConditions_Spare_11" 23 "EngSpdCtrlBadConditions_Spare_10" 22 "EngSpdCtrlBadConditions_Spare_09" 21 "EngSpdCtrlBadConditions_Spare_08" 20 "EngSpdCtrlBadConditions_Spare_07" 19 "EngSpdCtrlBadConditions_Spare_06" 18 "EngSpdCtrlBadConditions_Spare_05" 17 "EngSpdCtrlBadConditions_Spare_04" 16 "EngSpdCtrlBadConditions_Spare_03" 15 "EngSpdCtrlBadConditions_Spare_02" 14 "EngSpdCtrlBadConditions_Spare_01" 13 "EngSpdCtrlBadConditions_Spare" 12 "EngSpdCtrlBadConditions_IdleAdjustmentAlreadyActive" 11 "EngSpdCtrlBadConditions_CrossCountryAlreadyActive" 10 "EngSpdCtrlBadConditions_CruiseControlAlreadyActive" 9 "EngSpdCtrlBadConditions_WrongGearSplitSelected" 8 "EngSpdCtrlBadConditions_ClutchPedalNotPressed" 7 "EngSpdCtrlBadConditions_ServiceBrakeNotApplied" 6 "EngSpdCtrlBadConditions_ParkBrakeNotActive" 5 "EngSpdCtrlBadConditions_VehicleSpeedTooHigh" 4 "EngSpdCtrlBadConditions_EngineSpeedTooHigh" 3 "EngSpdCtrlBadConditions_EngineSpeedTooLow" 2 "EngSpdCtrlBadConditions_GearboxNotInNeutral" 1 "EngSpdCtrlBadConditions_OtherConditionNotMet" 0 "EngSpdCtrlBadConditions_None" ;
VAL_ 2466210596 ESCReqEMS_CtrlTrimMode_ISig_4 15 "CtrlTrimMode_NotAvailable" 14 "CtrlTrimMode_Error" 13 "CtrlTrimMode_Spare_08" 12 "CtrlTrimMode_Spare_07" 11 "CtrlTrimMode_Spare_06" 10 "CtrlTrimMode_Spare_05" 9 "CtrlTrimMode_Spare_04" 8 "CtrlTrimMode_Spare_03" 7 "CtrlTrimMode_Spare_02" 6 "CtrlTrimMode_Spare_01" 5 "CtrlTrimMode_Spare" 4 "CtrlTrimMode_MuddySiteEngineSpeedControl" 3 "CtrlTrimMode_AirManagementEngineSpeedControl" 2 "CtrlTrimMode_IdleAdjust" 1 "CtrlTrimMode_PTOEngineSpeedControl" 0 "CtrlTrimMode_NoRequest" ;
VAL_ 2466210596 ESCReqESC_CtrlTrimMode_ISig_4 15 "CtrlTrimMode_NotAvailable" 14 "CtrlTrimMode_Error" 13 "CtrlTrimMode_Spare_08" 12 "CtrlTrimMode_Spare_07" 11 "CtrlTrimMode_Spare_06" 10 "CtrlTrimMode_Spare_05" 9 "CtrlTrimMode_Spare_04" 8 "CtrlTrimMode_Spare_03" 7 "CtrlTrimMode_Spare_02" 6 "CtrlTrimMode_Spare_01" 5 "CtrlTrimMode_Spare" 4 "CtrlTrimMode_MuddySiteEngineSpeedControl" 3 "CtrlTrimMode_AirManagementEngineSpeedControl" 2 "CtrlTrimMode_IdleAdjust" 1 "CtrlTrimMode_PTOEngineSpeedControl" 0 "CtrlTrimMode_NoRequest" ;
VAL_ 2466210596 IdleAdjustConditionStatus 3 "IdleAdjustConditionStatus_NotAvailable" 2 "IdleAdjustConditionStatus_Error" 1 "IdleAdjustConditionStatus_ConditionsMet" 0 "IdleAdjustConditionStatus_ConditionsNotMet" ;
VAL_ 2466210596 StopProhibitStatus_ISig_4 3 "InactiveActive_NotAvailable" 2 "InactiveActive_Error" 1 "InactiveActive_Active" 0 "InactiveActive_Inactive" ;
VAL_ 2466210596 ESCReqEMS_CtrlTrimStat_ISig_4 7 "CtrlTrimStat_NotAvailable" 6 "CtrlTrimStat_Error" 5 "CtrlTrimStat_Spare_02" 4 "CtrlTrimStat_Spare_01" 3 "CtrlTrimStat_Spare" 2 "CtrlTrimStat_TrimActive" 1 "CtrlTrimStat_ControlActive" 0 "CtrlTrimStat_NoRequestActive" ;
VAL_ 2466210596 TrailerConnected_ISig_4 3 "NoYes_NotAvailable" 2 "NoYes_Error" 1 "NoYes_Yes" 0 "NoYes_No" ;
VAL_ 2466210596 ESCReqESC_CtrlTrimStat_ISig_4 7 "CtrlTrimStat_NotAvailable" 6 "CtrlTrimStat_Error" 5 "CtrlTrimStat_Spare_02" 4 "CtrlTrimStat_Spare_01" 3 "CtrlTrimStat_Spare" 2 "CtrlTrimStat_TrimActive" 1 "CtrlTrimStat_ControlActive" 0 "CtrlTrimStat_NoRequestActive" ;
VAL_ 2466210596 SCLLogicEnable_rqst 7 "SCLLogicEnable_rqst_NotAvailable" 6 "SCLLogicEnable_rqst_Error" 5 "SCLLogicEnable_rqst_Spare_disable_value_02" 4 "SCLLogicEnable_rqst_Spare_disable_value_01" 3 "SCLLogicEnable_rqst_Enable_locking" 2 "SCLLogicEnable_rqst_Enable_unlocking" 1 "SCLLogicEnable_rqst_Retry_disable" 0 "SCLLogicEnable_rqst_Disable" ;
VAL_ 2466210596 ESCReqESC_CtrlTrimReq_ISig_4 7 "CtrlTrimReq_NotAvailable" 6 "CtrlTrimReq_Error" 5 "CtrlTrimReq_Spare_02" 4 "CtrlTrimReq_Spare_01" 3 "CtrlTrimReq_Spare" 2 "CtrlTrimReq_TrimRampDown" 1 "CtrlTrimReq_TrimRampUp" 0 "CtrlTrimReq_NoRamp" ;
VAL_ 2466210596 BrakeLight_rqst_ISig_4 7 "BrakeLight_rqst_NotAvailable" 6 "BrakeLight_rqst_SpareValue_03" 5 "BrakeLight_rqst_SpareValue_02" 4 "BrakeLight_rqst_SpareValue_01" 3 "BrakeLight_rqst_SpareValue" 2 "BrakeLight_rqst_EmergencyBrakeLightOn" 1 "BrakeLight_rqst_BrakeLightOn" 0 "BrakeLight_rqst_BrakeLightAndEmergencyBrakeLightOff" ;
VAL_ 2466210596 ESCReqEMS_CtrlTrimReq_ISig_4 7 "CtrlTrimReq_NotAvailable" 6 "CtrlTrimReq_Error" 5 "CtrlTrimReq_Spare_02" 4 "CtrlTrimReq_Spare_01" 3 "CtrlTrimReq_Spare" 2 "CtrlTrimReq_TrimRampDown" 1 "CtrlTrimReq_TrimRampUp" 0 "CtrlTrimReq_NoRamp" ;
VAL_ 2466196004 TrailerTest_stat 7 "TrailerTest_stat_NotAvailable" 6 "TrailerTest_stat_Error" 5 "TrailerTest_stat_InProgress_TrailerNotConnected" 4 "TrailerTest_stat_NotPossibleLowVoltgeOrLowPressure" 3 "TrailerTest_stat_TrailerTestIncentive" 2 "TrailerTest_stat_NotPossibleServiceBrakeApplied" 1 "TrailerTest_stat_InProgress" 0 "TrailerTest_stat_IdleNoTrailerTest" ;
VAL_ 2466196004 Washing_HMI_rqst_ISig_4 3 "InactiveActive_NotAvailable" 2 "InactiveActive_Error" 1 "InactiveActive_Active" 0 "InactiveActive_Inactive" ;
VAL_ 2466196004 AuxBrakesDwngrdModeInd_rqst_ISig 7 "AuxBrakesDwngrdModeInd_rqst_NotAvailable" 6 "AuxBrakesDwngrdModeInd_rqst_Error" 5 "AuxBrakesDwngrdModeInd_rqst_Spare_3" 4 "AuxBrakesDwngrdModeInd_rqst_Spare_2" 3 "AuxBrakesDwngrdModeInd_rqst_Spare_1" 2 "AuxBrakesDwngrdModeInd_rqst_AuxiliaryBrakesShutdown" 1 "AuxBrakesDwngrdModeInd_rqst_ABSDowngradedMode" 0 "AuxBrakesDwngrdModeInd_rqst_NoRequest" ;
VAL_ 2466196004 KeyAuthentication_rqst 7 "KeyAuthentication_rqst_NotAvailable" 6 "KeyAuthentication_rqst_Error" 5 "KeyAuthentication_rqst_Spare02" 4 "KeyAuthentication_rqst_Spare01" 3 "KeyAuthentication_rqst_Spare" 2 "KeyAuthentication_rqst_RequestAuthentication" 1 "KeyAuthentication_rqst_KeyIsInserted" 0 "KeyAuthentication_rqst_KeyNotPresent" ;
VAL_ 2466196004 EngineSpeedControlStatus_ISig_4 7 "EngineSpeedControlStatus_NotAvailable" 6 "EngineSpeedControlStatus_Error" 5 "EngineSpeedControlStatus_Spare_01" 4 "EngineSpeedControlStatus_AutoPtoMin_AutoNeutral" 3 "EngineSpeedControlStatus_CrossCountryEngineSpeedControlActive" 2 "EngineSpeedControlStatus_ActiveExternalSource" 1 "EngineSpeedControlStatus_ActiveManual" 0 "EngineSpeedControlStatus_Inactive" ;
VAL_ 2466196004 EngineSpeedLimitReached 7 "EngineSpeedLimitReached_NotAvailable" 6 "EngineSpeedLimitReached_Error" 5 "EngineSpeedLimitReached_Spare_02" 4 "EngineSpeedLimitReached_Spare_01" 3 "EngineSpeedLimitReached_Spare" 2 "EngineSpeedLimitReached_MaximumReached" 1 "EngineSpeedLimitReached_MinimumReached" 0 "EngineSpeedLimitReached_NotReached" ;
VAL_ 2466196004 SecondThrottle 3 "InactiveActive_NotAvailable" 2 "InactiveActive_Error" 1 "InactiveActive_Active" 0 "InactiveActive_Inactive" ;
VAL_ 2466196004 PredeliveryModeIndication_cmd_IS 3 "DeactivateActivate_NotAvailable" 2 "DeactivateActivate_Error" 1 "DeactivateActivate_Activate" 0 "DeactivateActivate_Deactivate" ;
VAL_ 2466196004 LoadCutOffIndication_cmd_ISig_4 3 "LoadCutOffIndication_cmd_NotAvailable" 2 "LoadCutOffIndication_cmd_Error" 1 "LoadCutOffIndication_cmd_LoadCutOffIndication" 0 "LoadCutOffIndication_cmd_NoIndication" ;
VAL_ 2466196004 AutoPBRelease_stat_ISig_4 3 "AutoPBRelease_stat_NotAvailable" 2 "AutoPBRelease_stat_Error" 1 "AutoPBRelease_stat_FunctionInhibited" 0 "AutoPBRelease_stat_FunctionArmed" ;
VAL_ 2466196004 AutoParkBrakeActvnInhibd_stat_IS 3 "Inhibit_NotAvailable" 2 "Inhibit_Error" 1 "Inhibit_InhibitActive" 0 "Inhibit_NoInhibit" ;
VAL_ 2466196004 WiperParkStatus_Global_ISig_4 3 "WiperParkStatus_NotAvailable" 2 "WiperParkStatus_ErrorIndicator" 1 "WiperParkStatus_WiperNotParked" 0 "WiperParkStatus_WiperParked" ;
VAL_ 2466196004 ExitPreDeliveryModeHMI_rqst_ISig 3 "FalseTrue_NotAvaiable" 2 "FalseTrue_Error" 1 "FalseTrue_True" 0 "FalseTrue_False" ;
VAL_ 2466196004 FdEquipmentStatus1_ISig_4 3 "InactiveActive_NotAvailable" 2 "InactiveActive_Error" 1 "InactiveActive_Active" 0 "InactiveActive_Inactive" ;
VAL_ 2432649764 ParkBrakeAlert_ISig_4 3 "Alert_NotAvailable" 2 "Alert_Error" 1 "Alert_Alert" 0 "Alert_NoAlert" ;
VAL_ 2432649764 IntLightMode_CoreRqst_IL_Mode 7 "IL_ModeReq_NotAvailable" 6 "IL_ModeReq_ErrorIndicator" 5 "IL_ModeReq_NonHMIModeMax" 4 "IL_ModeReq_NonHMIModeResting" 3 "IL_ModeReq_Max" 2 "IL_ModeReq_Resting" 1 "IL_ModeReq_NightDriving" 0 "IL_ModeReq_OFF" ;
VAL_ 2432649764 SteeringColumnLockErrInd_rqst 7 "SteeringColumnLockErrInd_rqst_NotAvailable" 6 "SteeringColumnLockErrInd_rqst_Error" 5 "SteeringColumnLockErrInd_rqst_SpareValue01" 4 "SteeringColumnLockErrInd_rqst_SpareValue" 3 "SteeringColumnLockErrInd_rqst_OtherError" 2 "SteeringColumnLockErrInd_rqst_NotPossibleToUnlock" 1 "SteeringColumnLockErrInd_rqst_NotPossibleToLock" 0 "SteeringColumnLockErrInd_rqst_NoErrorIndication" ;
VAL_ 2432649764 MainBeamIndication_cmd 3 "InactiveActive_NotAvailable" 2 "InactiveActive_Error" 1 "InactiveActive_Active" 0 "InactiveActive_Inactive" ;
VAL_ 2432649764 PosLightWarning_rqst 3 "Request_NotAvailable" 2 "Request_Error" 1 "Request_RequestActive" 0 "Request_NotRequested" ;
VAL_ 2432649764 RainsensorActivationHMI_stat 3 "RainsensorActivationHMI_stat_NotAvailable" 2 "RainsensorActivationHMI_stat_Error" 1 "RainsensorActivationHMI_stat_Activated" 0 "RainsensorActivationHMI_stat_Deactivated" ;
VAL_ 2432649764 FogLight_Front_Indication_Cmd 3 "InactiveActive_NotAvailable" 2 "InactiveActive_Error" 1 "InactiveActive_Active" 0 "InactiveActive_Inactive" ;
VAL_ 2432649764 ParkingLight_Indication 3 "DeviceIndication_SpareValue" 2 "DeviceIndication_Blink" 1 "DeviceIndication_On" 0 "DeviceIndication_Off" ;
VAL_ 2432649764 DaytimeRunningLight_Indication 3 "DeviceIndication_SpareValue" 2 "DeviceIndication_Blink" 1 "DeviceIndication_On" 0 "DeviceIndication_Off" ;
VAL_ 2432649764 EPBBackupMode_ISig_4 15 "EPBBackupMode_NotAvailable" 14 "EPBBackupMode_Error" 13 "EPBBackupMode_Level13" 12 "EPBBackupMode_Level12" 11 "EPBBackupMode_Level11" 10 "EPBBackupMode_Level10" 9 "EPBBackupMode_Level9" 8 "EPBBackupMode_Level8" 7 "EPBBackupMode_Level7" 6 "EPBBackupMode_Level6" 5 "EPBBackupMode_Level5" 4 "EPBBackupMode_Level4" 3 "EPBBackupMode_Level3" 2 "EPBBackupMode_Level2" 1 "EPBBackupMode_Level1" 0 "EPBBackupMode_Level0_NoBackUp" ;
VAL_ 2432649764 WiperModeStatus_ISig_4 7 "WiperModeStatus_NotAvailable" 6 "WiperModeStatus_ErrorIndicator" 5 "WiperModeStatus_Spare02" 4 "WiperModeStatus_Spare01" 3 "WiperModeStatus_Spare" 2 "WiperModeStatus_HighSpeedWiping" 1 "WiperModeStatus_LowSpeedWiping" 0 "WiperModeStatus_WiperOff" ;
VAL_ 2432649764 FrontFog_Indication 3 "DeviceIndication_SpareValue" 2 "DeviceIndication_Blink" 1 "DeviceIndication_On" 0 "DeviceIndication_Off" ;
VAL_ 2432649764 PBReleaseAcceptance_stat_ISig_4 7 "PBReleaseAcceptance_stat_NotAvailable" 6 "PBReleaseAcceptance_stat_Error" 5 "PBReleaseAcceptance_stat_Spare_03" 4 "PBReleaseAcceptance_stat_AccelPedalOrHCURequested" 3 "PBReleaseAcceptance_stat_ReleaseRequestAccepted" 2 "PBReleaseAcceptance_stat_BrakeOrAccelPedalRequested" 1 "PBReleaseAcceptance_stat_BrakePedalRequested" 0 "PBReleaseAcceptance_stat_NoRequestDetectedOrRequestAborted" ;
VAL_ 2432649764 DrivingLightPlus_Indication 3 "DeviceIndication_SpareValue" 2 "DeviceIndication_Blink" 1 "DeviceIndication_On" 0 "DeviceIndication_Off" ;
VAL_ 2432649764 IntLightMode_CoreRqst_EventFlag 1 "EventFlag_High" 0 "EventFlag_Low" ;
VAL_ 2432649764 ParkingBrake_stat_ISig_4 3 "ParkingBrake_stat_NotAvailable" 2 "ParkingBrake_stat_Error" 1 "ParkingBrake_stat_ParkingBrakeActivated" 0 "ParkingBrake_stat_ParkingBrakeReleased" ;
VAL_ 2432649764 DrivingLight_Indication 3 "DeviceIndication_SpareValue" 2 "DeviceIndication_Blink" 1 "DeviceIndication_On" 0 "DeviceIndication_Off" ;
VAL_ 2432649764 Rainsensor_Indication 3 "DeviceIndication_SpareValue" 2 "DeviceIndication_Blink" 1 "DeviceIndication_On" 0 "DeviceIndication_Off" ;
VAL_ 2432649764 DippedBeamIndication_cmd 3 "InactiveActive_NotAvailable" 2 "InactiveActive_Error" 1 "InactiveActive_Active" 0 "InactiveActive_Inactive" ;
VAL_ 2432649764 MirrorHeatingMode_ISig_4 7 "MirrorHeat_NotAvailable" 6 "MirrorHeat_ErrorIndicator" 5 "MirrorHeat_SpareValue_02" 4 "MirrorHeat_SpareValue_01" 3 "MirrorHeat_SpareValue" 2 "MirrorHeat_ONExtendedMode" 1 "MirrorHeat_ONNormalMode" 0 "MirrorHeat_OFF" ;
VAL_ 2432649764 RearFog_Indication 3 "DeviceIndication_SpareValue" 2 "DeviceIndication_Blink" 1 "DeviceIndication_On" 0 "DeviceIndication_Off" ;
VAL_ 2432649764 FogLight_Rear_Indication_Cmd 3 "InactiveActive_NotAvailable" 2 "InactiveActive_Error" 1 "InactiveActive_Active" 0 "InactiveActive_Inactive" ;
VAL_ 2432649764 PosLight_Indication_Cmd 3 "OffOn_NotAvailable" 2 "OffOn_Error" 1 "OffOn_On" 0 "OffOn_Off" ;
VAL_ 2432649764 DirIndicationTimeoutInd_rqst 3 "DirIndicationTimeoutInd_rqst_NotAvailable" 2 "DirIndicationTimeoutInd_rqst_Error" 1 "DirIndicationTimeoutInd_rqst_IndicateDirectionIndicationTimeout" 0 "DirIndicationTimeoutInd_rqst_NoInfo" ;
SIG_GROUP_ 2549579812 RefrigTimer_rqst_sg 1 : RefrigTimer_rqst_DayOfWeekRq RefrigTimer_rqst_Hours RefrigTimer_rqst_SetAlarmOper RefrigTimer_rqst_Minutes;
SIG_GROUP_ 2466210596 ESCReqEMS_sg_ISig_4 1 : ESCReqEMS_CtrlTrimMode_ISig_4 ESCReqEMS_CtrlTrimStat_ISig_4 ESCReqEMS_CtrlTrimValue_ISig_4 ESCReqEMS_CtrlTrimReq_ISig_4;
SIG_GROUP_ 2466210596 ESCReqESC_sg_ISig_4 1 : ESCReqESC_CtrlTrimMode_ISig_4 ESCReqESC_CtrlTrimValue_ISig_4 ESCReqESC_CtrlTrimStat_ISig_4 ESCReqESC_CtrlTrimReq_ISig_4;
SIG_GROUP_ 2432649764 IntLightMode_CoreRqst_sg 1 : IntLightMode_CoreRqst_IL_Mode IntLightMode_CoreRqst_EventFlag;
